VERSION ""

NS_ :

BS_:

BU_:  Battery  Charger  Host

BO_ 2566852862 BATT_eventMatrix_A_8: 8 Battery
 SG_ BATT_packModIdFault_8 : 8|1@1+ (1,0) [0|1] "" Host
 SG_ BATT_packModExitedFromBus_8 : 16|1@1+ (1,0) [0|1] "" Host
 SG_ BATT_packFetChgWelded_8 : 35|1@1+ (1,0) [0|1] "" Host
 SG_ BATT_packFetDsgWelded_8 : 36|1@1+ (1,0) [0|1] "" Host
 SG_ BATT_fetDsgShortedAux_8 : 63|1@1+ (1,0) [0|1] "" Host
 SG_ BATT_fetChgShortedAux_8 : 25|1@1+ (1,0) [0|1] "" Host
 SG_ BATT_prechargeFetFail_8 : 39|1@1+ (1,0) [0|1] "" Host
 SG_ BATT_abnormalResetReason_8 : 31|1@1+ (1,0) [0|1] "" Host
 SG_ BATT_prechargeTooSlow_8 : 49|1@1+ (1,0) [0|1] "" Host
 SG_ BATT_prechargeTooFast_8 : 50|1@1+ (1,0) [0|1] "" Host
 SG_ BATT_prechargeTimeout_8 : 51|1@1+ (1,0) [0|1] "" Host
 SG_ BATT_fetChgShorted_8 : 23|1@1+ (1,0) [0|1] "" Host
 SG_ BATT_fetChgFailToClose_8 : 22|1@1+ (1,0) [0|1] "" Host
 SG_ BATT_packModSelectFault_8 : 21|1@1+ (1,0) [0|1] "" Host
 SG_ BATT_packModConnectFault_8 : 20|1@1+ (1,0) [0|1] "" Host
 SG_ BATT_packModMIA_8 : 19|1@1+ (1,0) [0|1] "" Host
 SG_ BATT_packModImbalance_8 : 18|1@1+ (1,0) [0|1] "" Host
 SG_ BATT_afeFault_8 : 17|1@1+ (1,0) [0|1] "" Host
 SG_ BATT_chargerMIA_8 : 60|1@1+ (1,0) [0|1] "" Host
 SG_ BATT_chargerError_8 : 59|1@1+ (1,0) [0|1] "" Host
 SG_ BATT_vBrickUnderWar_8 : 58|1@1+ (1,0) [0|1] "" Host
 SG_ BATT_vBrickUnderSev_8 : 57|1@1+ (1,0) [0|1] "" Host
 SG_ BATT_vBrickUnderMod_8 : 56|1@1+ (1,0) [0|1] "" Host
 SG_ BATT_vBrickOverWar_8 : 55|1@1+ (1,0) [0|1] "" Host
 SG_ BATT_vBrickOverSev_8 : 54|1@1+ (1,0) [0|1] "" Host
 SG_ BATT_vBrickOverMod_8 : 53|1@1+ (1,0) [0|1] "" Host
 SG_ BATT_vBrickImbalance_8 : 52|1@1+ (1,0) [0|1] "" Host
 SG_ BATT_loggerAlmostFull_8 : 61|1@1+ (1,0) [0|1] "" Host
 SG_ BATT_tempModuleUnderWar_8 : 48|1@1+ (1,0) [0|1] "" Host
 SG_ BATT_tempModuleUnderSev_8 : 47|1@1+ (1,0) [0|1] "" Host
 SG_ BATT_tempModuleUnderMod_8 : 46|1@1+ (1,0) [0|1] "" Host
 SG_ BATT_tempModuleOverWar_8 : 45|1@1+ (1,0) [0|1] "" Host
 SG_ BATT_tempModuleOverSev_8 : 44|1@1+ (1,0) [0|1] "" Host
 SG_ BATT_tempModuleOverMod_8 : 43|1@1+ (1,0) [0|1] "" Host
 SG_ BATT_tempBrickImbalance_8 : 42|1@1+ (1,0) [0|1] "" Host
 SG_ BATT_taskLockupError_8 : 41|1@1+ (1,0) [0|1] "" Host
 SG_ BATT_tempBoardOverWar_8 : 40|1@1+ (1,0) [0|1] "" Host
 SG_ BATT_tempBoardOverSev_8 : 38|1@1+ (1,0) [0|1] "" Host
 SG_ BATT_tempBoardOverMod_8 : 37|1@1+ (1,0) [0|1] "" Host
 SG_ BATT_sensePackVoltError_8 : 34|1@1+ (1,0) [0|1] "" Host
 SG_ BATT_senseLoadVoltError_8 : 33|1@1+ (1,0) [0|1] "" Host
 SG_ BATT_loggerFull_8 : 62|1@1+ (1,0) [0|1] "" Host
 SG_ BATT_senseCurrentError_8 : 32|1@1+ (1,0) [0|1] "" Host
 SG_ BATT_senseBrickTempError_8 : 30|1@1+ (1,0) [0|1] "" Host
 SG_ BATT_resPackHigh_8 : 29|1@1+ (1,0) [0|1] "" Host
 SG_ BATT_ramOverUtilError_8 : 28|1@1+ (1,0) [0|1] "" Host
 SG_ BATT_powerPackInsufficient_8 : 27|1@1+ (1,0) [0|1] "" Host
 SG_ BATT_packCellSoftShort_8 : 26|1@1+ (1,0) [0|1] "" Host
 SG_ BATT_iOverHardware_8 : 24|1@1+ (1,0) [0|1] "" Host
 SG_ BATT_fetOverTemp_8 : 15|1@1+ (1,0) [0|1] "" Host
 SG_ BATT_iOverDischarge_8 : 14|1@1+ (1,0) [0|1] "" Host
 SG_ BATT_iOverCharge_8 : 13|1@1+ (1,0) [0|1] "" Host
 SG_ BATT_inverterDriveMIA_8 : 12|1@1+ (1,0) [0|1] "" Host
 SG_ BATT_iUnderCharge_8 : 11|1@1+ (1,0) [0|1] "" Host
 SG_ BATT_hostMIA_8 : 10|1@1+ (1,0) [0|1] "" Host
 SG_ BATT_fetDsgShorted_8 : 7|1@1+ (1,0) [0|1] "" Host
 SG_ BATT_fetDsgFailToClose_8 : 6|1@1+ (1,0) [0|1] "" Host
 SG_ BATT_capLow_8 : 5|1@1+ (1,0) [0|1] "" Host
 SG_ BATT_brickOverDischarge_8 : 4|1@1+ (1,0) [0|1] "" Host
 SG_ BATT_brickOverCharge_8 : 3|1@1+ (1,0) [0|1] "" Host
 SG_ BATT_bmsProcessorError_8 : 2|1@1+ (1,0) [0|1] "" Host
 SG_ BATT_bmsMemoryError_8 : 1|1@1+ (1,0) [0|1] "" Host
 SG_ BATT_afeError_8 : 0|1@1+ (1,0) [0|1] "" Host

BO_ 2566852863 BATT_eventMatrix_A_9: 8 Battery
 SG_ BATT_packModIdFault_9 : 8|1@1+ (1,0) [0|1] "" Host
 SG_ BATT_packModExitedFromBus_9 : 16|1@1+ (1,0) [0|1] "" Host
 SG_ BATT_packFetChgWelded_9 : 35|1@1+ (1,0) [0|1] "" Host
 SG_ BATT_packFetDsgWelded_9 : 36|1@1+ (1,0) [0|1] "" Host
 SG_ BATT_fetDsgShortedAux_9 : 63|1@1+ (1,0) [0|1] "" Host
 SG_ BATT_fetChgShortedAux_9 : 25|1@1+ (1,0) [0|1] "" Host
 SG_ BATT_prechargeFetFail_9 : 39|1@1+ (1,0) [0|1] "" Host
 SG_ BATT_abnormalResetReason_9 : 31|1@1+ (1,0) [0|1] "" Host
 SG_ BATT_prechargeTooSlow_9 : 49|1@1+ (1,0) [0|1] "" Host
 SG_ BATT_prechargeTooFast_9 : 50|1@1+ (1,0) [0|1] "" Host
 SG_ BATT_prechargeTimeout_9 : 51|1@1+ (1,0) [0|1] "" Host
 SG_ BATT_fetChgShorted_9 : 23|1@1+ (1,0) [0|1] "" Host
 SG_ BATT_fetChgFailToClose_9 : 22|1@1+ (1,0) [0|1] "" Host
 SG_ BATT_packModSelectFault_9 : 21|1@1+ (1,0) [0|1] "" Host
 SG_ BATT_packModConnectFault_9 : 20|1@1+ (1,0) [0|1] "" Host
 SG_ BATT_packModMIA_9 : 19|1@1+ (1,0) [0|1] "" Host
 SG_ BATT_packModImbalance_9 : 18|1@1+ (1,0) [0|1] "" Host
 SG_ BATT_afeFault_9 : 17|1@1+ (1,0) [0|1] "" Host
 SG_ BATT_chargerMIA_9 : 60|1@1+ (1,0) [0|1] "" Host
 SG_ BATT_chargerError_9 : 59|1@1+ (1,0) [0|1] "" Host
 SG_ BATT_vBrickUnderWar_9 : 58|1@1+ (1,0) [0|1] "" Host
 SG_ BATT_vBrickUnderSev_9 : 57|1@1+ (1,0) [0|1] "" Host
 SG_ BATT_vBrickUnderMod_9 : 56|1@1+ (1,0) [0|1] "" Host
 SG_ BATT_vBrickOverWar_9 : 55|1@1+ (1,0) [0|1] "" Host
 SG_ BATT_vBrickOverSev_9 : 54|1@1+ (1,0) [0|1] "" Host
 SG_ BATT_vBrickOverMod_9 : 53|1@1+ (1,0) [0|1] "" Host
 SG_ BATT_vBrickImbalance_9 : 52|1@1+ (1,0) [0|1] "" Host
 SG_ BATT_loggerAlmostFull_9 : 61|1@1+ (1,0) [0|1] "" Host
 SG_ BATT_tempModuleUnderWar_9 : 48|1@1+ (1,0) [0|1] "" Host
 SG_ BATT_tempModuleUnderSev_9 : 47|1@1+ (1,0) [0|1] "" Host
 SG_ BATT_tempModuleUnderMod_9 : 46|1@1+ (1,0) [0|1] "" Host
 SG_ BATT_tempModuleOverWar_9 : 45|1@1+ (1,0) [0|1] "" Host
 SG_ BATT_tempModuleOverSev_9 : 44|1@1+ (1,0) [0|1] "" Host
 SG_ BATT_tempModuleOverMod_9 : 43|1@1+ (1,0) [0|1] "" Host
 SG_ BATT_tempBrickImbalance_9 : 42|1@1+ (1,0) [0|1] "" Host
 SG_ BATT_taskLockupError_9 : 41|1@1+ (1,0) [0|1] "" Host
 SG_ BATT_tempBoardOverWar_9 : 40|1@1+ (1,0) [0|1] "" Host
 SG_ BATT_tempBoardOverSev_9 : 38|1@1+ (1,0) [0|1] "" Host
 SG_ BATT_tempBoardOverMod_9 : 37|1@1+ (1,0) [0|1] "" Host
 SG_ BATT_sensePackVoltError_9 : 34|1@1+ (1,0) [0|1] "" Host
 SG_ BATT_senseLoadVoltError_9 : 33|1@1+ (1,0) [0|1] "" Host
 SG_ BATT_loggerFull_9 : 62|1@1+ (1,0) [0|1] "" Host
 SG_ BATT_senseCurrentError_9 : 32|1@1+ (1,0) [0|1] "" Host
 SG_ BATT_senseBrickTempError_9 : 30|1@1+ (1,0) [0|1] "" Host
 SG_ BATT_resPackHigh_9 : 29|1@1+ (1,0) [0|1] "" Host
 SG_ BATT_ramOverUtilError_9 : 28|1@1+ (1,0) [0|1] "" Host
 SG_ BATT_powerPackInsufficient_9 : 27|1@1+ (1,0) [0|1] "" Host
 SG_ BATT_packCellSoftShort_9 : 26|1@1+ (1,0) [0|1] "" Host
 SG_ BATT_iOverHardware_9 : 24|1@1+ (1,0) [0|1] "" Host
 SG_ BATT_fetOverTemp_9 : 15|1@1+ (1,0) [0|1] "" Host
 SG_ BATT_iOverDischarge_9 : 14|1@1+ (1,0) [0|1] "" Host
 SG_ BATT_iOverCharge_9 : 13|1@1+ (1,0) [0|1] "" Host
 SG_ BATT_inverterDriveMIA_9 : 12|1@1+ (1,0) [0|1] "" Host
 SG_ BATT_iUnderCharge_9 : 11|1@1+ (1,0) [0|1] "" Host
 SG_ BATT_hostMIA_9 : 10|1@1+ (1,0) [0|1] "" Host
 SG_ BATT_fetDsgShorted_9 : 7|1@1+ (1,0) [0|1] "" Host
 SG_ BATT_fetDsgFailToClose_9 : 6|1@1+ (1,0) [0|1] "" Host
 SG_ BATT_capLow_9 : 5|1@1+ (1,0) [0|1] "" Host
 SG_ BATT_brickOverDischarge_9 : 4|1@1+ (1,0) [0|1] "" Host
 SG_ BATT_brickOverCharge_9 : 3|1@1+ (1,0) [0|1] "" Host
 SG_ BATT_bmsProcessorError_9 : 2|1@1+ (1,0) [0|1] "" Host
 SG_ BATT_bmsMemoryError_9 : 1|1@1+ (1,0) [0|1] "" Host
 SG_ BATT_afeError_9 : 0|1@1+ (1,0) [0|1] "" Host

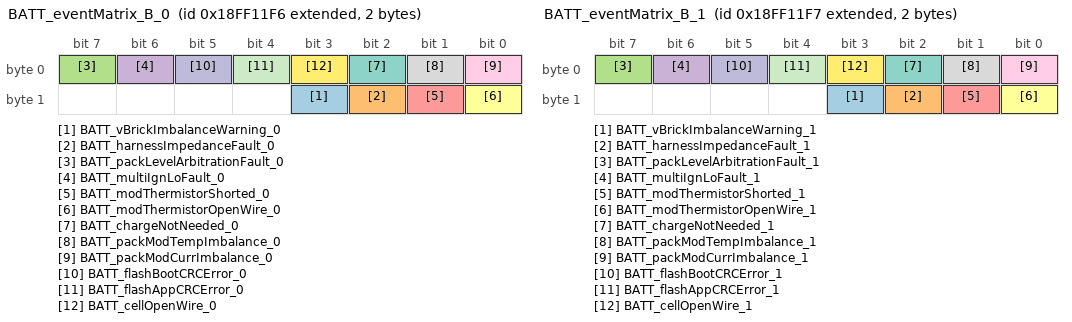
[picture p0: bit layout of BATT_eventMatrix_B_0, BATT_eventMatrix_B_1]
BO_ 2566853110 BATT_eventMatrix_B_0: 2 Battery
 SG_ BATT_vBrickImbalanceWarning_0 : 11|1@1+ (1,0) [0|1] "" Host
 SG_ BATT_harnessImpedanceFault_0 : 10|1@1+ (1,0) [0|1] "mOhms" Host
 SG_ BATT_packLevelArbitrationFault_0 : 7|1@1+ (1,0) [0|1] "" Host
 SG_ BATT_multiIgnLoFault_0 : 6|1@1+ (1,0) [0|1] "" Host
 SG_ BATT_modThermistorShorted_0 : 9|1@1+ (1,0) [0|1] "" Host
 SG_ BATT_modThermistorOpenWire_0 : 8|1@1+ (1,0) [0|1] "" Host
 SG_ BATT_chargeNotNeeded_0 : 2|1@1+ (1,0) [0|1] "" Host
 SG_ BATT_packModTempImbalance_0 : 1|1@1+ (1,0) [0|1] "" Host
 SG_ BATT_packModCurrImbalance_0 : 0|1@1+ (1,0) [0|1] "" Host
 SG_ BATT_flashBootCRCError_0 : 5|1@1+ (1,0) [0|1] "" Host
 SG_ BATT_flashAppCRCError_0 : 4|1@1+ (1,0) [0|1] "" Host
 SG_ BATT_cellOpenWire_0 : 3|1@1+ (1,0) [0|1] "" Host

BO_ 2566853111 BATT_eventMatrix_B_1: 2 Battery
 SG_ BATT_vBrickImbalanceWarning_1 : 11|1@1+ (1,0) [0|1] "" Host
 SG_ BATT_harnessImpedanceFault_1 : 10|1@1+ (1,0) [0|1] "mOhms" Host
 SG_ BATT_packLevelArbitrationFault_1 : 7|1@1+ (1,0) [0|1] "" Host
 SG_ BATT_multiIgnLoFault_1 : 6|1@1+ (1,0) [0|1] "" Host
 SG_ BATT_modThermistorShorted_1 : 9|1@1+ (1,0) [0|1] "" Host
 SG_ BATT_modThermistorOpenWire_1 : 8|1@1+ (1,0) [0|1] "" Host
 SG_ BATT_chargeNotNeeded_1 : 2|1@1+ (1,0) [0|1] "" Host
 SG_ BATT_packModTempImbalance_1 : 1|1@1+ (1,0) [0|1] "" Host
 SG_ BATT_packModCurrImbalance_1 : 0|1@1+ (1,0) [0|1] "" Host
 SG_ BATT_flashBootCRCError_1 : 5|1@1+ (1,0) [0|1] "" Host
 SG_ BATT_flashAppCRCError_1 : 4|1@1+ (1,0) [0|1] "" Host
 SG_ BATT_cellOpenWire_1 : 3|1@1+ (1,0) [0|1] "" Host

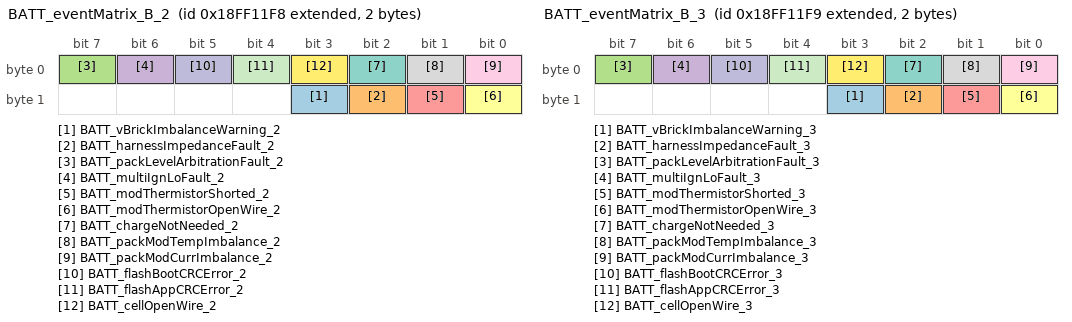
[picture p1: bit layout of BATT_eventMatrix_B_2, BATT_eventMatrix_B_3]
BO_ 2566853112 BATT_eventMatrix_B_2: 2 Battery
 SG_ BATT_vBrickImbalanceWarning_2 : 11|1@1+ (1,0) [0|1] "" Host
 SG_ BATT_harnessImpedanceFault_2 : 10|1@1+ (1,0) [0|1] "mOhms" Host
 SG_ BATT_packLevelArbitrationFault_2 : 7|1@1+ (1,0) [0|1] "" Host
 SG_ BATT_multiIgnLoFault_2 : 6|1@1+ (1,0) [0|1] "" Host
 SG_ BATT_modThermistorShorted_2 : 9|1@1+ (1,0) [0|1] "" Host
 SG_ BATT_modThermistorOpenWire_2 : 8|1@1+ (1,0) [0|1] "" Host
 SG_ BATT_chargeNotNeeded_2 : 2|1@1+ (1,0) [0|1] "" Host
 SG_ BATT_packModTempImbalance_2 : 1|1@1+ (1,0) [0|1] "" Host
 SG_ BATT_packModCurrImbalance_2 : 0|1@1+ (1,0) [0|1] "" Host
 SG_ BATT_flashBootCRCError_2 : 5|1@1+ (1,0) [0|1] "" Host
 SG_ BATT_flashAppCRCError_2 : 4|1@1+ (1,0) [0|1] "" Host
 SG_ BATT_cellOpenWire_2 : 3|1@1+ (1,0) [0|1] "" Host

BO_ 2566853113 BATT_eventMatrix_B_3: 2 Battery
 SG_ BATT_vBrickImbalanceWarning_3 : 11|1@1+ (1,0) [0|1] "" Host
 SG_ BATT_harnessImpedanceFault_3 : 10|1@1+ (1,0) [0|1] "mOhms" Host
 SG_ BATT_packLevelArbitrationFault_3 : 7|1@1+ (1,0) [0|1] "" Host
 SG_ BATT_multiIgnLoFault_3 : 6|1@1+ (1,0) [0|1] "" Host
 SG_ BATT_modThermistorShorted_3 : 9|1@1+ (1,0) [0|1] "" Host
 SG_ BATT_modThermistorOpenWire_3 : 8|1@1+ (1,0) [0|1] "" Host
 SG_ BATT_chargeNotNeeded_3 : 2|1@1+ (1,0) [0|1] "" Host
 SG_ BATT_packModTempImbalance_3 : 1|1@1+ (1,0) [0|1] "" Host
 SG_ BATT_packModCurrImbalance_3 : 0|1@1+ (1,0) [0|1] "" Host
 SG_ BATT_flashBootCRCError_3 : 5|1@1+ (1,0) [0|1] "" Host
 SG_ BATT_flashAppCRCError_3 : 4|1@1+ (1,0) [0|1] "" Host
 SG_ BATT_cellOpenWire_3 : 3|1@1+ (1,0) [0|1] "" Host

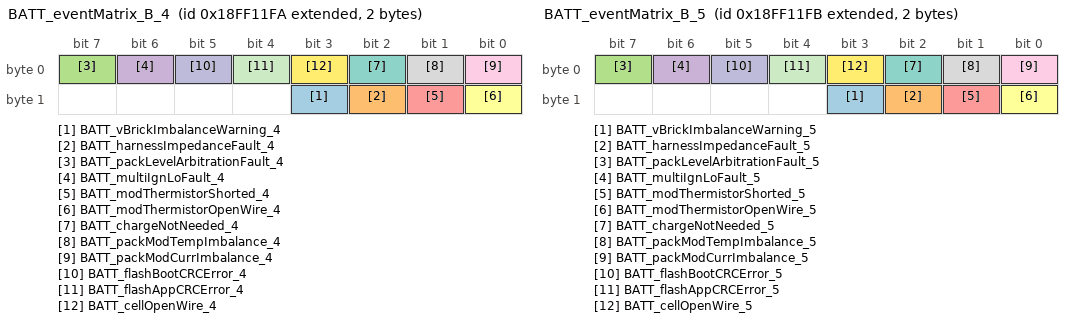
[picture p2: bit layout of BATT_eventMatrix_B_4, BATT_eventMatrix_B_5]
BO_ 2566853114 BATT_eventMatrix_B_4: 2 Battery
 SG_ BATT_vBrickImbalanceWarning_4 : 11|1@1+ (1,0) [0|1] "" Host
 SG_ BATT_harnessImpedanceFault_4 : 10|1@1+ (1,0) [0|1] "mOhms" Host
 SG_ BATT_packLevelArbitrationFault_4 : 7|1@1+ (1,0) [0|1] "" Host
 SG_ BATT_multiIgnLoFault_4 : 6|1@1+ (1,0) [0|1] "" Host
 SG_ BATT_modThermistorShorted_4 : 9|1@1+ (1,0) [0|1] "" Host
 SG_ BATT_modThermistorOpenWire_4 : 8|1@1+ (1,0) [0|1] "" Host
 SG_ BATT_chargeNotNeeded_4 : 2|1@1+ (1,0) [0|1] "" Host
 SG_ BATT_packModTempImbalance_4 : 1|1@1+ (1,0) [0|1] "" Host
 SG_ BATT_packModCurrImbalance_4 : 0|1@1+ (1,0) [0|1] "" Host
 SG_ BATT_flashBootCRCError_4 : 5|1@1+ (1,0) [0|1] "" Host
 SG_ BATT_flashAppCRCError_4 : 4|1@1+ (1,0) [0|1] "" Host
 SG_ BATT_cellOpenWire_4 : 3|1@1+ (1,0) [0|1] "" Host

BO_ 2566853115 BATT_eventMatrix_B_5: 2 Battery
 SG_ BATT_vBrickImbalanceWarning_5 : 11|1@1+ (1,0) [0|1] "" Host
 SG_ BATT_harnessImpedanceFault_5 : 10|1@1+ (1,0) [0|1] "mOhms" Host
 SG_ BATT_packLevelArbitrationFault_5 : 7|1@1+ (1,0) [0|1] "" Host
 SG_ BATT_multiIgnLoFault_5 : 6|1@1+ (1,0) [0|1] "" Host
 SG_ BATT_modThermistorShorted_5 : 9|1@1+ (1,0) [0|1] "" Host
 SG_ BATT_modThermistorOpenWire_5 : 8|1@1+ (1,0) [0|1] "" Host
 SG_ BATT_chargeNotNeeded_5 : 2|1@1+ (1,0) [0|1] "" Host
 SG_ BATT_packModTempImbalance_5 : 1|1@1+ (1,0) [0|1] "" Host
 SG_ BATT_packModCurrImbalance_5 : 0|1@1+ (1,0) [0|1] "" Host
 SG_ BATT_flashBootCRCError_5 : 5|1@1+ (1,0) [0|1] "" Host
 SG_ BATT_flashAppCRCError_5 : 4|1@1+ (1,0) [0|1] "" Host
 SG_ BATT_cellOpenWire_5 : 3|1@1+ (1,0) [0|1] "" Host

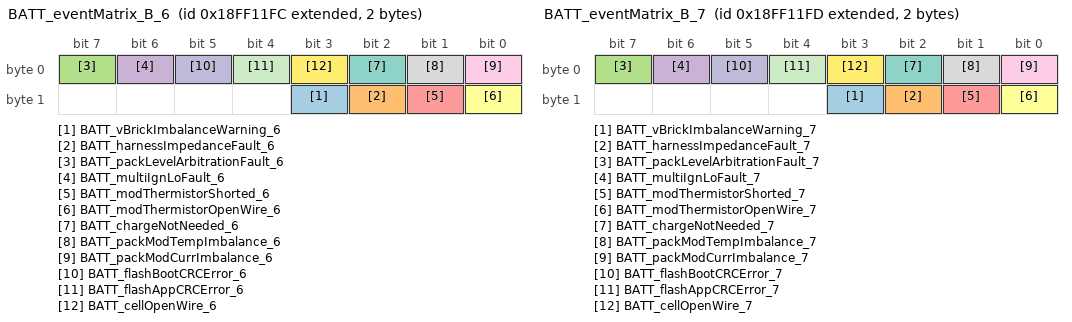
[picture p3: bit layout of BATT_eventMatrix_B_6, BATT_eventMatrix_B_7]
BO_ 2566853116 BATT_eventMatrix_B_6: 2 Battery
 SG_ BATT_vBrickImbalanceWarning_6 : 11|1@1+ (1,0) [0|1] "" Host
 SG_ BATT_harnessImpedanceFault_6 : 10|1@1+ (1,0) [0|1] "mOhms" Host
 SG_ BATT_packLevelArbitrationFault_6 : 7|1@1+ (1,0) [0|1] "" Host
 SG_ BATT_multiIgnLoFault_6 : 6|1@1+ (1,0) [0|1] "" Host
 SG_ BATT_modThermistorShorted_6 : 9|1@1+ (1,0) [0|1] "" Host
 SG_ BATT_modThermistorOpenWire_6 : 8|1@1+ (1,0) [0|1] "" Host
 SG_ BATT_chargeNotNeeded_6 : 2|1@1+ (1,0) [0|1] "" Host
 SG_ BATT_packModTempImbalance_6 : 1|1@1+ (1,0) [0|1] "" Host
 SG_ BATT_packModCurrImbalance_6 : 0|1@1+ (1,0) [0|1] "" Host
 SG_ BATT_flashBootCRCError_6 : 5|1@1+ (1,0) [0|1] "" Host
 SG_ BATT_flashAppCRCError_6 : 4|1@1+ (1,0) [0|1] "" Host
 SG_ BATT_cellOpenWire_6 : 3|1@1+ (1,0) [0|1] "" Host

BO_ 2566853117 BATT_eventMatrix_B_7: 2 Battery
 SG_ BATT_vBrickImbalanceWarning_7 : 11|1@1+ (1,0) [0|1] "" Host
 SG_ BATT_harnessImpedanceFault_7 : 10|1@1+ (1,0) [0|1] "mOhms" Host
 SG_ BATT_packLevelArbitrationFault_7 : 7|1@1+ (1,0) [0|1] "" Host
 SG_ BATT_multiIgnLoFault_7 : 6|1@1+ (1,0) [0|1] "" Host
 SG_ BATT_modThermistorShorted_7 : 9|1@1+ (1,0) [0|1] "" Host
 SG_ BATT_modThermistorOpenWire_7 : 8|1@1+ (1,0) [0|1] "" Host
 SG_ BATT_chargeNotNeeded_7 : 2|1@1+ (1,0) [0|1] "" Host
 SG_ BATT_packModTempImbalance_7 : 1|1@1+ (1,0) [0|1] "" Host
 SG_ BATT_packModCurrImbalance_7 : 0|1@1+ (1,0) [0|1] "" Host
 SG_ BATT_flashBootCRCError_7 : 5|1@1+ (1,0) [0|1] "" Host
 SG_ BATT_flashAppCRCError_7 : 4|1@1+ (1,0) [0|1] "" Host
 SG_ BATT_cellOpenWire_7 : 3|1@1+ (1,0) [0|1] "" Host

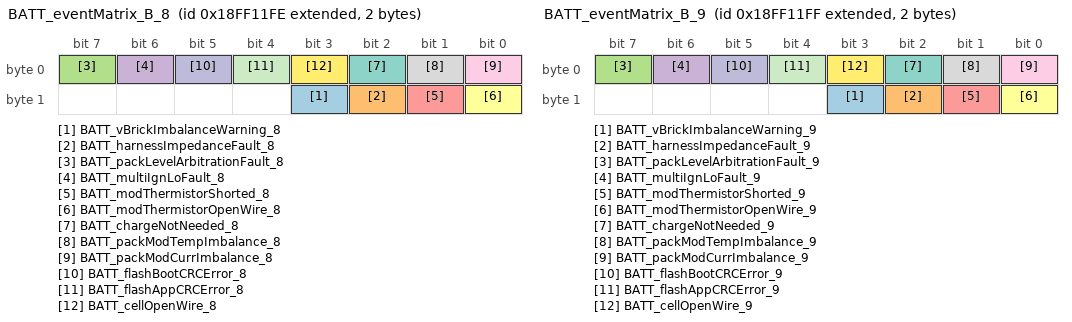
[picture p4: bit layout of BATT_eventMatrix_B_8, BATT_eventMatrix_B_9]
BO_ 2566853118 BATT_eventMatrix_B_8: 2 Battery
 SG_ BATT_vBrickImbalanceWarning_8 : 11|1@1+ (1,0) [0|1] "" Host
 SG_ BATT_harnessImpedanceFault_8 : 10|1@1+ (1,0) [0|1] "mOhms" Host
 SG_ BATT_packLevelArbitrationFault_8 : 7|1@1+ (1,0) [0|1] "" Host
 SG_ BATT_multiIgnLoFault_8 : 6|1@1+ (1,0) [0|1] "" Host
 SG_ BATT_modThermistorShorted_8 : 9|1@1+ (1,0) [0|1] "" Host
 SG_ BATT_modThermistorOpenWire_8 : 8|1@1+ (1,0) [0|1] "" Host
 SG_ BATT_chargeNotNeeded_8 : 2|1@1+ (1,0) [0|1] "" Host
 SG_ BATT_packModTempImbalance_8 : 1|1@1+ (1,0) [0|1] "" Host
 SG_ BATT_packModCurrImbalance_8 : 0|1@1+ (1,0) [0|1] "" Host
 SG_ BATT_flashBootCRCError_8 : 5|1@1+ (1,0) [0|1] "" Host
 SG_ BATT_flashAppCRCError_8 : 4|1@1+ (1,0) [0|1] "" Host
 SG_ BATT_cellOpenWire_8 : 3|1@1+ (1,0) [0|1] "" Host

BO_ 2566853119 BATT_eventMatrix_B_9: 2 Battery
 SG_ BATT_vBrickImbalanceWarning_9 : 11|1@1+ (1,0) [0|1] "" Host
 SG_ BATT_harnessImpedanceFault_9 : 10|1@1+ (1,0) [0|1] "mOhms" Host
 SG_ BATT_packLevelArbitrationFault_9 : 7|1@1+ (1,0) [0|1] "" Host
 SG_ BATT_multiIgnLoFault_9 : 6|1@1+ (1,0) [0|1] "" Host
 SG_ BATT_modThermistorShorted_9 : 9|1@1+ (1,0) [0|1] "" Host
 SG_ BATT_modThermistorOpenWire_9 : 8|1@1+ (1,0) [0|1] "" Host
 SG_ BATT_chargeNotNeeded_9 : 2|1@1+ (1,0) [0|1] "" Host
 SG_ BATT_packModTempImbalance_9 : 1|1@1+ (1,0) [0|1] "" Host
 SG_ BATT_packModCurrImbalance_9 : 0|1@1+ (1,0) [0|1] "" Host
 SG_ BATT_flashBootCRCError_9 : 5|1@1+ (1,0) [0|1] "" Host
 SG_ BATT_flashAppCRCError_9 : 4|1@1+ (1,0) [0|1] "" Host
 SG_ BATT_cellOpenWire_9 : 3|1@1+ (1,0) [0|1] "" Host

BO_ 2566853622 BATT_diagnosticSOHRBricksB_0: 8 Battery
 SG_ BATT_sohrBrick08_0 : 48|16@1+ (0.00075,0) [0|49.15125] "Ah" Host
 SG_ BATT_sohrBrick07_0 : 32|16@1+ (0.00075,0) [0|49.15125] "Ah" Host
 SG_ BATT_sohrBrick06_0 : 16|16@1+ (0.00075,0) [0|49.15125] "Ah" Host
 SG_ BATT_sohrBrick05_0 : 0|16@1+ (0.00075,0) [0|49.15125] "Ah" Host

BO_ 2566853623 BATT_diagnosticSOHRBricksB_1: 8 Battery
 SG_ BATT_sohrBrick08_1 : 48|16@1+ (0.00075,0) [0|49.15125] "Ah" Host
 SG_ BATT_sohrBrick07_1 : 32|16@1+ (0.00075,0) [0|49.15125] "Ah" Host
 SG_ BATT_sohrBrick06_1 : 16|16@1+ (0.00075,0) [0|49.15125] "Ah" Host
 SG_ BATT_sohrBrick05_1 : 0|16@1+ (0.00075,0) [0|49.15125] "Ah" Host

BO_ 2566853624 BATT_diagnosticSOHRBricksB_2: 8 Battery
 SG_ BATT_sohrBrick08_2 : 48|16@1+ (0.00075,0) [0|49.15125] "Ah" Host
 SG_ BATT_sohrBrick07_2 : 32|16@1+ (0.00075,0) [0|49.15125] "Ah" Host
 SG_ BATT_sohrBrick06_2 : 16|16@1+ (0.00075,0) [0|49.15125] "Ah" Host
 SG_ BATT_sohrBrick05_2 : 0|16@1+ (0.00075,0) [0|49.15125] "Ah" Host

BO_ 2566853625 BATT_diagnosticSOHRBricksB_3: 8 Battery
 SG_ BATT_sohrBrick08_3 : 48|16@1+ (0.00075,0) [0|49.15125] "Ah" Host
 SG_ BATT_sohrBrick07_3 : 32|16@1+ (0.00075,0) [0|49.15125] "Ah" Host
 SG_ BATT_sohrBrick06_3 : 16|16@1+ (0.00075,0) [0|49.15125] "Ah" Host
 SG_ BATT_sohrBrick05_3 : 0|16@1+ (0.00075,0) [0|49.15125] "Ah" Host

BO_ 2566853626 BATT_diagnosticSOHRBricksB_4: 8 Battery
 SG_ BATT_sohrBrick08_4 : 48|16@1+ (0.00075,0) [0|49.15125] "Ah" Host
 SG_ BATT_sohrBrick07_4 : 32|16@1+ (0.00075,0) [0|49.15125] "Ah" Host
 SG_ BATT_sohrBrick06_4 : 16|16@1+ (0.00075,0) [0|49.15125] "Ah" Host
 SG_ BATT_sohrBrick05_4 : 0|16@1+ (0.00075,0) [0|49.15125] "Ah" Host

BO_ 2566853627 BATT_diagnosticSOHRBricksB_5: 8 Battery
 SG_ BATT_sohrBrick08_5 : 48|16@1+ (0.00075,0) [0|49.15125] "Ah" Host
 SG_ BATT_sohrBrick07_5 : 32|16@1+ (0.00075,0) [0|49.15125] "Ah" Host
 SG_ BATT_sohrBrick06_5 : 16|16@1+ (0.00075,0) [0|49.15125] "Ah" Host
 SG_ BATT_sohrBrick05_5 : 0|16@1+ (0.00075,0) [0|49.15125] "Ah" Host

BO_ 2566853628 BATT_diagnosticSOHRBricksB_6: 8 Battery
 SG_ BATT_sohrBrick08_6 : 48|16@1+ (0.00075,0) [0|49.15125] "Ah" Host
 SG_ BATT_sohrBrick07_6 : 32|16@1+ (0.00075,0) [0|49.15125] "Ah" Host
 SG_ BATT_sohrBrick06_6 : 16|16@1+ (0.00075,0) [0|49.15125] "Ah" Host
 SG_ BATT_sohrBrick05_6 : 0|16@1+ (0.00075,0) [0|49.15125] "Ah" Host

BO_ 2566853629 BATT_diagnosticSOHRBricksB_7: 8 Battery
 SG_ BATT_sohrBrick08_7 : 48|16@1+ (0.00075,0) [0|49.15125] "Ah" Host
 SG_ BATT_sohrBrick07_7 : 32|16@1+ (0.00075,0) [0|49.15125] "Ah" Host
 SG_ BATT_sohrBrick06_7 : 16|16@1+ (0.00075,0) [0|49.15125] "Ah" Host
 SG_ BATT_sohrBrick05_7 : 0|16@1+ (0.00075,0) [0|49.15125] "Ah" Host

BO_ 2566853630 BATT_diagnosticSOHRBricksB_8: 8 Battery
 SG_ BATT_sohrBrick08_8 : 48|16@1+ (0.00075,0) [0|49.15125] "Ah" Host
 SG_ BATT_sohrBrick07_8 : 32|16@1+ (0.00075,0) [0|49.15125] "Ah" Host
 SG_ BATT_sohrBrick06_8 : 16|16@1+ (0.00075,0) [0|49.15125] "Ah" Host
 SG_ BATT_sohrBrick05_8 : 0|16@1+ (0.00075,0) [0|49.15125] "Ah" Host

BO_ 2566853631 BATT_diagnosticSOHRBricksB_9: 8 Battery
 SG_ BATT_sohrBrick08_9 : 48|16@1+ (0.00075,0) [0|49.15125] "Ah" Host
 SG_ BATT_sohrBrick07_9 : 32|16@1+ (0.00075,0) [0|49.15125] "Ah" Host
 SG_ BATT_sohrBrick06_9 : 16|16@1+ (0.00075,0) [0|49.15125] "Ah" Host
 SG_ BATT_sohrBrick05_9 : 0|16@1+ (0.00075,0) [0|49.15125] "Ah" Host

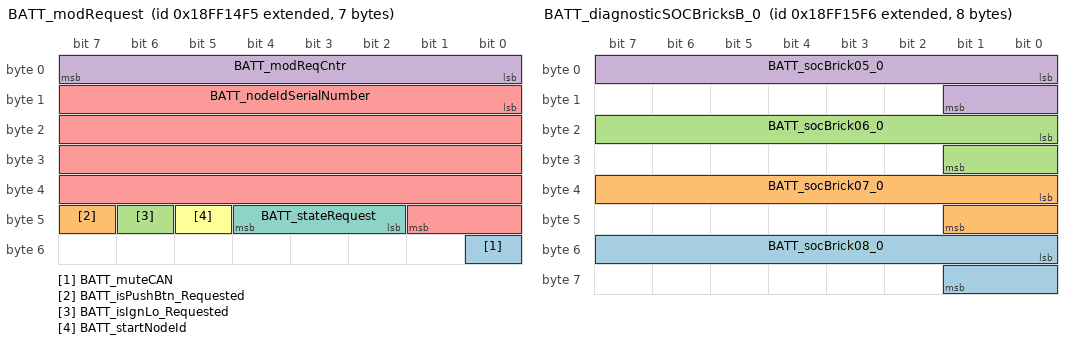
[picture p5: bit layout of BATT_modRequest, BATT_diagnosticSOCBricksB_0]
BO_ 2566853877 BATT_modRequest: 7 Battery
 SG_ BATT_muteCAN : 48|1@1+ (1,0) [0|1] "" Host,Battery
 SG_ BATT_isPushBtn_Requested : 47|1@1+ (1,0) [0|1] "" Battery,Host
 SG_ BATT_isIgnLo_Requested : 46|1@1+ (1,0) [0|1] "" Battery,Host
 SG_ BATT_modReqCntr : 0|8@1+ (1,0) [0|255] "" Battery,Host
 SG_ BATT_nodeIdSerialNumber : 8|34@1+ (1,0) [0|17179869183] "" Battery,Host
 SG_ BATT_startNodeId : 45|1@1+ (1,0) [0|1] "" Battery,Host
 SG_ BATT_stateRequest : 42|3@1+ (1,0) [0|7] "" Battery,Host

BO_ 2566854134 BATT_diagnosticSOCBricksB_0: 8 Battery
 SG_ BATT_socBrick08_0 : 48|10@1+ (0.1,0) [0|102.3] "%" Host
 SG_ BATT_socBrick07_0 : 32|10@1+ (0.1,0) [0|102.3] "%" Host
 SG_ BATT_socBrick06_0 : 16|10@1+ (0.1,0) [0|102.3] "%" Host
 SG_ BATT_socBrick05_0 : 0|10@1+ (0.1,0) [0|102.3] "%" Host

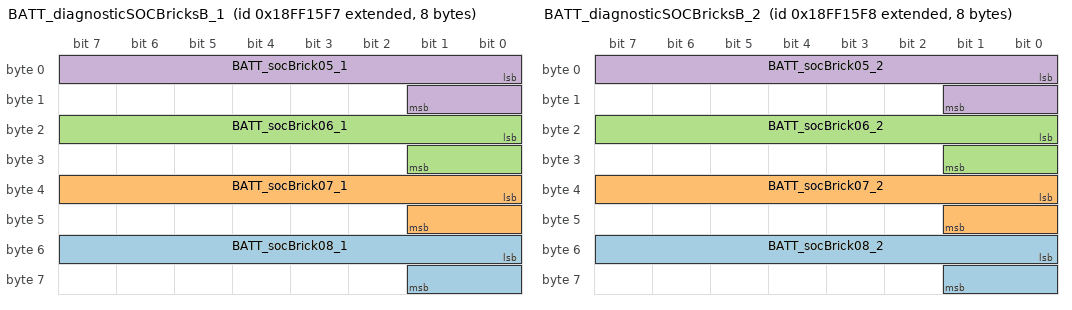
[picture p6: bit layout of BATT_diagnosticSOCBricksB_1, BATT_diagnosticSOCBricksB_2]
BO_ 2566854135 BATT_diagnosticSOCBricksB_1: 8 Battery
 SG_ BATT_socBrick08_1 : 48|10@1+ (0.1,0) [0|102.3] "%" Host
 SG_ BATT_socBrick07_1 : 32|10@1+ (0.1,0) [0|102.3] "%" Host
 SG_ BATT_socBrick06_1 : 16|10@1+ (0.1,0) [0|102.3] "%" Host
 SG_ BATT_socBrick05_1 : 0|10@1+ (0.1,0) [0|102.3] "%" Host

BO_ 2566854136 BATT_diagnosticSOCBricksB_2: 8 Battery
 SG_ BATT_socBrick08_2 : 48|10@1+ (0.1,0) [0|102.3] "%" Host
 SG_ BATT_socBrick07_2 : 32|10@1+ (0.1,0) [0|102.3] "%" Host
 SG_ BATT_socBrick06_2 : 16|10@1+ (0.1,0) [0|102.3] "%" Host
 SG_ BATT_socBrick05_2 : 0|10@1+ (0.1,0) [0|102.3] "%" Host

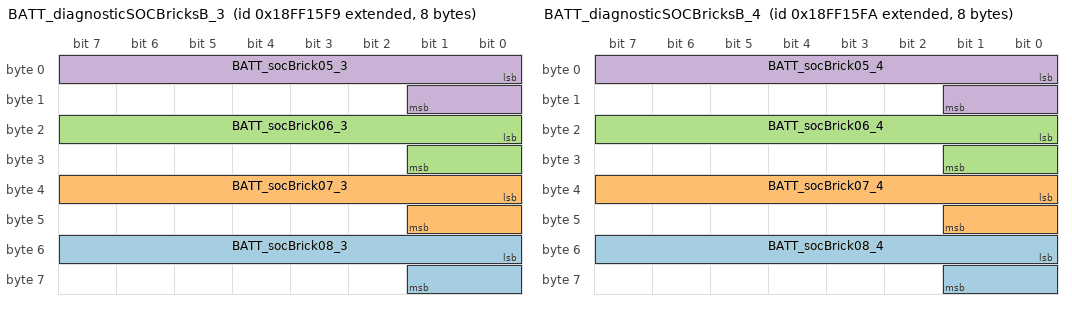
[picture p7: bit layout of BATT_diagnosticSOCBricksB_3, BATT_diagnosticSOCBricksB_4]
BO_ 2566854137 BATT_diagnosticSOCBricksB_3: 8 Battery
 SG_ BATT_socBrick08_3 : 48|10@1+ (0.1,0) [0|102.3] "%" Host
 SG_ BATT_socBrick07_3 : 32|10@1+ (0.1,0) [0|102.3] "%" Host
 SG_ BATT_socBrick06_3 : 16|10@1+ (0.1,0) [0|102.3] "%" Host
 SG_ BATT_socBrick05_3 : 0|10@1+ (0.1,0) [0|102.3] "%" Host

BO_ 2566854138 BATT_diagnosticSOCBricksB_4: 8 Battery
 SG_ BATT_socBrick08_4 : 48|10@1+ (0.1,0) [0|102.3] "%" Host
 SG_ BATT_socBrick07_4 : 32|10@1+ (0.1,0) [0|102.3] "%" Host
 SG_ BATT_socBrick06_4 : 16|10@1+ (0.1,0) [0|102.3] "%" Host
 SG_ BATT_socBrick05_4 : 0|10@1+ (0.1,0) [0|102.3] "%" Host

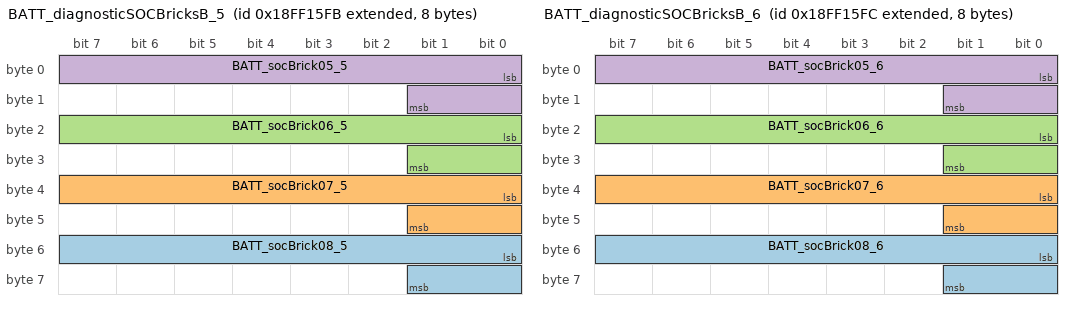
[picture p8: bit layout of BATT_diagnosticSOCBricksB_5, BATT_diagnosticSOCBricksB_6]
BO_ 2566854139 BATT_diagnosticSOCBricksB_5: 8 Battery
 SG_ BATT_socBrick08_5 : 48|10@1+ (0.1,0) [0|102.3] "%" Host
 SG_ BATT_socBrick07_5 : 32|10@1+ (0.1,0) [0|102.3] "%" Host
 SG_ BATT_socBrick06_5 : 16|10@1+ (0.1,0) [0|102.3] "%" Host
 SG_ BATT_socBrick05_5 : 0|10@1+ (0.1,0) [0|102.3] "%" Host

BO_ 2566854140 BATT_diagnosticSOCBricksB_6: 8 Battery
 SG_ BATT_socBrick08_6 : 48|10@1+ (0.1,0) [0|102.3] "%" Host
 SG_ BATT_socBrick07_6 : 32|10@1+ (0.1,0) [0|102.3] "%" Host
 SG_ BATT_socBrick06_6 : 16|10@1+ (0.1,0) [0|102.3] "%" Host
 SG_ BATT_socBrick05_6 : 0|10@1+ (0.1,0) [0|102.3] "%" Host

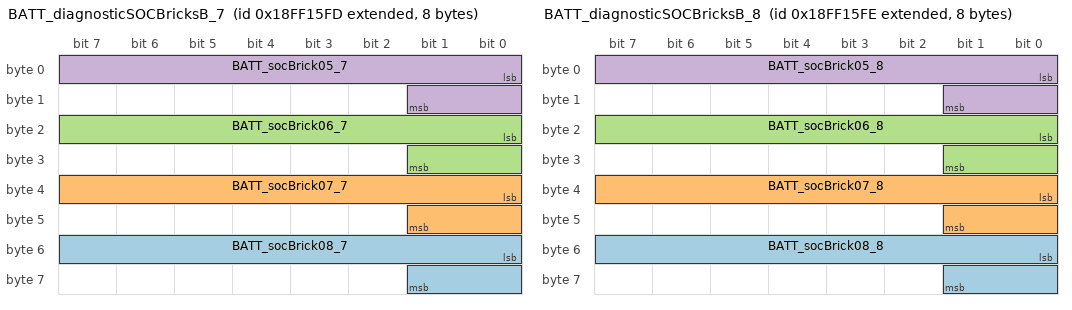
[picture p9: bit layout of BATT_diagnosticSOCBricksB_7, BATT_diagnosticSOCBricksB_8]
BO_ 2566854141 BATT_diagnosticSOCBricksB_7: 8 Battery
 SG_ BATT_socBrick08_7 : 48|10@1+ (0.1,0) [0|102.3] "%" Host
 SG_ BATT_socBrick07_7 : 32|10@1+ (0.1,0) [0|102.3] "%" Host
 SG_ BATT_socBrick06_7 : 16|10@1+ (0.1,0) [0|102.3] "%" Host
 SG_ BATT_socBrick05_7 : 0|10@1+ (0.1,0) [0|102.3] "%" Host

BO_ 2566854142 BATT_diagnosticSOCBricksB_8: 8 Battery
 SG_ BATT_socBrick08_8 : 48|10@1+ (0.1,0) [0|102.3] "%" Host
 SG_ BATT_socBrick07_8 : 32|10@1+ (0.1,0) [0|102.3] "%" Host
 SG_ BATT_socBrick06_8 : 16|10@1+ (0.1,0) [0|102.3] "%" Host
 SG_ BATT_socBrick05_8 : 0|10@1+ (0.1,0) [0|102.3] "%" Host

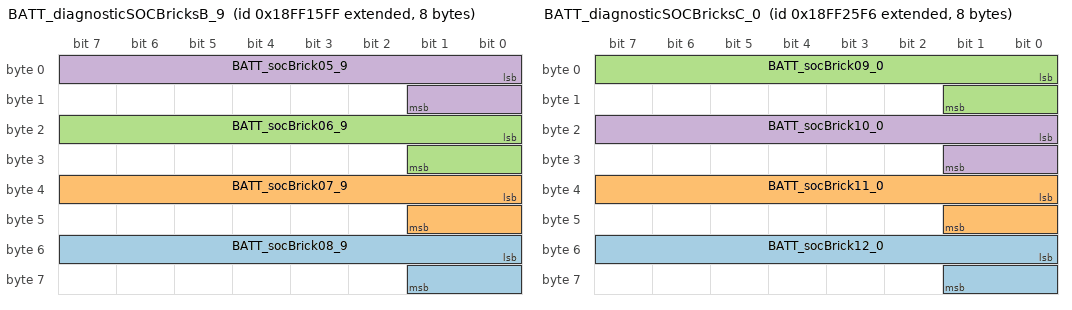
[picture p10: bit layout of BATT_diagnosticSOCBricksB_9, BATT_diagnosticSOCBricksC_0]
BO_ 2566854143 BATT_diagnosticSOCBricksB_9: 8 Battery
 SG_ BATT_socBrick08_9 : 48|10@1+ (0.1,0) [0|102.3] "%" Host
 SG_ BATT_socBrick07_9 : 32|10@1+ (0.1,0) [0|102.3] "%" Host
 SG_ BATT_socBrick06_9 : 16|10@1+ (0.1,0) [0|102.3] "%" Host
 SG_ BATT_socBrick05_9 : 0|10@1+ (0.1,0) [0|102.3] "%" Host

BO_ 2566854390 BATT_diagnosticCapBricksB_0: 8 Battery
 SG_ BATT_capBrick08_0 : 48|16@1+ (0.0025,0) [0|163.8375] "Ah" Host
 SG_ BATT_capBrick07_0 : 32|16@1+ (0.0025,0) [0|163.8375] "Ah" Host
 SG_ BATT_capBrick06_0 : 16|16@1+ (0.0025,0) [0|163.8375] "Ah" Host
 SG_ BATT_capBrick05_0 : 0|16@1+ (0.0025,0) [0|163.8375] "Ah" Host

BO_ 2566854391 BATT_diagnosticCapBricksB_1: 8 Battery
 SG_ BATT_capBrick08_1 : 48|16@1+ (0.0025,0) [0|163.8375] "Ah" Host
 SG_ BATT_capBrick07_1 : 32|16@1+ (0.0025,0) [0|163.8375] "Ah" Host
 SG_ BATT_capBrick06_1 : 16|16@1+ (0.0025,0) [0|163.8375] "Ah" Host
 SG_ BATT_capBrick05_1 : 0|16@1+ (0.0025,0) [0|163.8375] "Ah" Host

BO_ 2566854392 BATT_diagnosticCapBricksB_2: 8 Battery
 SG_ BATT_capBrick08_2 : 48|16@1+ (0.0025,0) [0|163.8375] "Ah" Host
 SG_ BATT_capBrick07_2 : 32|16@1+ (0.0025,0) [0|163.8375] "Ah" Host
 SG_ BATT_capBrick06_2 : 16|16@1+ (0.0025,0) [0|163.8375] "Ah" Host
 SG_ BATT_capBrick05_2 : 0|16@1+ (0.0025,0) [0|163.8375] "Ah" Host

BO_ 2566854393 BATT_diagnosticCapBricksB_3: 8 Battery
 SG_ BATT_capBrick08_3 : 48|16@1+ (0.0025,0) [0|163.8375] "Ah" Host
 SG_ BATT_capBrick07_3 : 32|16@1+ (0.0025,0) [0|163.8375] "Ah" Host
 SG_ BATT_capBrick06_3 : 16|16@1+ (0.0025,0) [0|163.8375] "Ah" Host
 SG_ BATT_capBrick05_3 : 0|16@1+ (0.0025,0) [0|163.8375] "Ah" Host

BO_ 2566854394 BATT_diagnosticCapBricksB_4: 8 Battery
 SG_ BATT_capBrick08_4 : 48|16@1+ (0.0025,0) [0|163.8375] "Ah" Host
 SG_ BATT_capBrick07_4 : 32|16@1+ (0.0025,0) [0|163.8375] "Ah" Host
 SG_ BATT_capBrick06_4 : 16|16@1+ (0.0025,0) [0|163.8375] "Ah" Host
 SG_ BATT_capBrick05_4 : 0|16@1+ (0.0025,0) [0|163.8375] "Ah" Host

BO_ 2566854395 BATT_diagnosticCapBricksB_5: 8 Battery
 SG_ BATT_capBrick08_5 : 48|16@1+ (0.0025,0) [0|163.8375] "Ah" Host
 SG_ BATT_capBrick07_5 : 32|16@1+ (0.0025,0) [0|163.8375] "Ah" Host
 SG_ BATT_capBrick06_5 : 16|16@1+ (0.0025,0) [0|163.8375] "Ah" Host
 SG_ BATT_capBrick05_5 : 0|16@1+ (0.0025,0) [0|163.8375] "Ah" Host

BO_ 2566854396 BATT_diagnosticCapBricksB_6: 8 Battery
 SG_ BATT_capBrick08_6 : 48|16@1+ (0.0025,0) [0|163.8375] "Ah" Host
 SG_ BATT_capBrick07_6 : 32|16@1+ (0.0025,0) [0|163.8375] "Ah" Host
 SG_ BATT_capBrick06_6 : 16|16@1+ (0.0025,0) [0|163.8375] "Ah" Host
 SG_ BATT_capBrick05_6 : 0|16@1+ (0.0025,0) [0|163.8375] "Ah" Host

BO_ 2566854397 BATT_diagnosticCapBricksB_7: 8 Battery
 SG_ BATT_capBrick08_7 : 48|16@1+ (0.0025,0) [0|163.8375] "Ah" Host
 SG_ BATT_capBrick07_7 : 32|16@1+ (0.0025,0) [0|163.8375] "Ah" Host
 SG_ BATT_capBrick06_7 : 16|16@1+ (0.0025,0) [0|163.8375] "Ah" Host
 SG_ BATT_capBrick05_7 : 0|16@1+ (0.0025,0) [0|163.8375] "Ah" Host

BO_ 2566854398 BATT_diagnosticCapBricksB_8: 8 Battery
 SG_ BATT_capBrick08_8 : 48|16@1+ (0.0025,0) [0|163.8375] "Ah" Host
 SG_ BATT_capBrick07_8 : 32|16@1+ (0.0025,0) [0|163.8375] "Ah" Host
 SG_ BATT_capBrick06_8 : 16|16@1+ (0.0025,0) [0|163.8375] "Ah" Host
 SG_ BATT_capBrick05_8 : 0|16@1+ (0.0025,0) [0|163.8375] "Ah" Host

BO_ 2566854399 BATT_diagnosticCapBricksB_9: 8 Battery
 SG_ BATT_capBrick08_9 : 48|16@1+ (0.0025,0) [0|163.8375] "Ah" Host
 SG_ BATT_capBrick07_9 : 32|16@1+ (0.0025,0) [0|163.8375] "Ah" Host
 SG_ BATT_capBrick06_9 : 16|16@1+ (0.0025,0) [0|163.8375] "Ah" Host
 SG_ BATT_capBrick05_9 : 0|16@1+ (0.0025,0) [0|163.8375] "Ah" Host

BO_ 2566854646 BATT_diagnosticVBricksB_0: 8 Battery
 SG_ BATT_vBrick06_0 : 16|16@1+ (7.6e-05,0) [0|4.98066] "V" Host
 SG_ BATT_vBrick07_0 : 32|16@1+ (7.6e-05,0) [0|4.98066] "V" Host
 SG_ BATT_vBrick05_0 : 0|16@1+ (7.6e-05,0) [0|4.98066] "V" Host
 SG_ BATT_vBrick08_0 : 48|16@1+ (7.6e-05,0) [0|4.98066] "V" Host

BO_ 2566854647 BATT_diagnosticVBricksB_1: 8 Battery
 SG_ BATT_vBrick06_1 : 16|16@1+ (7.6e-05,0) [0|4.98066] "V" Host
 SG_ BATT_vBrick07_1 : 32|16@1+ (7.6e-05,0) [0|4.98066] "V" Host
 SG_ BATT_vBrick05_1 : 0|16@1+ (7.6e-05,0) [0|4.98066] "V" Host
 SG_ BATT_vBrick08_1 : 48|16@1+ (7.6e-05,0) [0|4.98066] "V" Host

BO_ 2566854648 BATT_diagnosticVBricksB_2: 8 Battery
 SG_ BATT_vBrick06_2 : 16|16@1+ (7.6e-05,0) [0|4.98066] "V" Host
 SG_ BATT_vBrick07_2 : 32|16@1+ (7.6e-05,0) [0|4.98066] "V" Host
 SG_ BATT_vBrick05_2 : 0|16@1+ (7.6e-05,0) [0|4.98066] "V" Host
 SG_ BATT_vBrick08_2 : 48|16@1+ (7.6e-05,0) [0|4.98066] "V" Host

BO_ 2566854649 BATT_diagnosticVBricksB_3: 8 Battery
 SG_ BATT_vBrick06_3 : 16|16@1+ (7.6e-05,0) [0|4.98066] "V" Host
 SG_ BATT_vBrick07_3 : 32|16@1+ (7.6e-05,0) [0|4.98066] "V" Host
 SG_ BATT_vBrick05_3 : 0|16@1+ (7.6e-05,0) [0|4.98066] "V" Host
 SG_ BATT_vBrick08_3 : 48|16@1+ (7.6e-05,0) [0|4.98066] "V" Host

BO_ 2566854650 BATT_diagnosticVBricksB_4: 8 Battery
 SG_ BATT_vBrick06_4 : 16|16@1+ (7.6e-05,0) [0|4.98066] "V" Host
 SG_ BATT_vBrick07_4 : 32|16@1+ (7.6e-05,0) [0|4.98066] "V" Host
 SG_ BATT_vBrick05_4 : 0|16@1+ (7.6e-05,0) [0|4.98066] "V" Host
 SG_ BATT_vBrick08_4 : 48|16@1+ (7.6e-05,0) [0|4.98066] "V" Host

BO_ 2566854651 BATT_diagnosticVBricksB_5: 8 Battery
 SG_ BATT_vBrick06_5 : 16|16@1+ (7.6e-05,0) [0|4.98066] "V" Host
 SG_ BATT_vBrick07_5 : 32|16@1+ (7.6e-05,0) [0|4.98066] "V" Host
 SG_ BATT_vBrick05_5 : 0|16@1+ (7.6e-05,0) [0|4.98066] "V" Host
 SG_ BATT_vBrick08_5 : 48|16@1+ (7.6e-05,0) [0|4.98066] "V" Host

BO_ 2566854652 BATT_diagnosticVBricksB_6: 8 Battery
 SG_ BATT_vBrick06_6 : 16|16@1+ (7.6e-05,0) [0|4.98066] "V" Host
 SG_ BATT_vBrick07_6 : 32|16@1+ (7.6e-05,0) [0|4.98066] "V" Host
 SG_ BATT_vBrick05_6 : 0|16@1+ (7.6e-05,0) [0|4.98066] "V" Host
 SG_ BATT_vBrick08_6 : 48|16@1+ (7.6e-05,0) [0|4.98066] "V" Host

BO_ 2566854653 BATT_diagnosticVBricksB_7: 8 Battery
 SG_ BATT_vBrick06_7 : 16|16@1+ (7.6e-05,0) [0|4.98066] "V" Host
 SG_ BATT_vBrick07_7 : 32|16@1+ (7.6e-05,0) [0|4.98066] "V" Host
 SG_ BATT_vBrick05_7 : 0|16@1+ (7.6e-05,0) [0|4.98066] "V" Host
 SG_ BATT_vBrick08_7 : 48|16@1+ (7.6e-05,0) [0|4.98066] "V" Host

BO_ 2566854654 BATT_diagnosticVBricksB_8: 8 Battery
 SG_ BATT_vBrick06_8 : 16|16@1+ (7.6e-05,0) [0|4.98066] "V" Host
 SG_ BATT_vBrick07_8 : 32|16@1+ (7.6e-05,0) [0|4.98066] "V" Host
 SG_ BATT_vBrick05_8 : 0|16@1+ (7.6e-05,0) [0|4.98066] "V" Host
 SG_ BATT_vBrick08_8 : 48|16@1+ (7.6e-05,0) [0|4.98066] "V" Host

BO_ 2566854655 BATT_diagnosticVBricksB_9: 8 Battery
 SG_ BATT_vBrick06_9 : 16|16@1+ (7.6e-05,0) [0|4.98066] "V" Host
 SG_ BATT_vBrick07_9 : 32|16@1+ (7.6e-05,0) [0|4.98066] "V" Host
 SG_ BATT_vBrick05_9 : 0|16@1+ (7.6e-05,0) [0|4.98066] "V" Host
 SG_ BATT_vBrick08_9 : 48|16@1+ (7.6e-05,0) [0|4.98066] "V" Host

BO_ 2566854902 BATT_diagnosticResBricksB_0: 8 Battery
 SG_ BATT_resBrick08_0 : 48|16@1+ (0.01,0) [0|655.35] "mOhms" Host
 SG_ BATT_resBrick07_0 : 32|16@1+ (0.01,0) [0|655.35] "mOhms" Host
 SG_ BATT_resBrick06_0 : 16|16@1+ (0.01,0) [0|655.35] "mOhms" Host
 SG_ BATT_resBrick05_0 : 0|16@1+ (0.01,0) [0|655.35] "mOhms" Host

BO_ 2566854903 BATT_diagnosticResBricksB_1: 8 Battery
 SG_ BATT_resBrick08_1 : 48|16@1+ (0.01,0) [0|655.35] "mOhms" Host
 SG_ BATT_resBrick07_1 : 32|16@1+ (0.01,0) [0|655.35] "mOhms" Host
 SG_ BATT_resBrick06_1 : 16|16@1+ (0.01,0) [0|655.35] "mOhms" Host
 SG_ BATT_resBrick05_1 : 0|16@1+ (0.01,0) [0|655.35] "mOhms" Host

BO_ 2566854904 BATT_diagnosticResBricksB_2: 8 Battery
 SG_ BATT_resBrick08_2 : 48|16@1+ (0.01,0) [0|655.35] "mOhms" Host
 SG_ BATT_resBrick07_2 : 32|16@1+ (0.01,0) [0|655.35] "mOhms" Host
 SG_ BATT_resBrick06_2 : 16|16@1+ (0.01,0) [0|655.35] "mOhms" Host
 SG_ BATT_resBrick05_2 : 0|16@1+ (0.01,0) [0|655.35] "mOhms" Host

BO_ 2566854905 BATT_diagnosticResBricksB_3: 8 Battery
 SG_ BATT_resBrick08_3 : 48|16@1+ (0.01,0) [0|655.35] "mOhms" Host
 SG_ BATT_resBrick07_3 : 32|16@1+ (0.01,0) [0|655.35] "mOhms" Host
 SG_ BATT_resBrick06_3 : 16|16@1+ (0.01,0) [0|655.35] "mOhms" Host
 SG_ BATT_resBrick05_3 : 0|16@1+ (0.01,0) [0|655.35] "mOhms" Host

BO_ 2566854906 BATT_diagnosticResBricksB_4: 8 Battery
 SG_ BATT_resBrick08_4 : 48|16@1+ (0.01,0) [0|655.35] "mOhms" Host
 SG_ BATT_resBrick07_4 : 32|16@1+ (0.01,0) [0|655.35] "mOhms" Host
 SG_ BATT_resBrick06_4 : 16|16@1+ (0.01,0) [0|655.35] "mOhms" Host
 SG_ BATT_resBrick05_4 : 0|16@1+ (0.01,0) [0|655.35] "mOhms" Host

BO_ 2566854907 BATT_diagnosticResBricksB_5: 8 Battery
 SG_ BATT_resBrick08_5 : 48|16@1+ (0.01,0) [0|655.35] "mOhms" Host
 SG_ BATT_resBrick07_5 : 32|16@1+ (0.01,0) [0|655.35] "mOhms" Host
 SG_ BATT_resBrick06_5 : 16|16@1+ (0.01,0) [0|655.35] "mOhms" Host
 SG_ BATT_resBrick05_5 : 0|16@1+ (0.01,0) [0|655.35] "mOhms" Host

BO_ 2566854908 BATT_diagnosticResBricksB_6: 8 Battery
 SG_ BATT_resBrick08_6 : 48|16@1+ (0.01,0) [0|655.35] "mOhms" Host
 SG_ BATT_resBrick07_6 : 32|16@1+ (0.01,0) [0|655.35] "mOhms" Host
 SG_ BATT_resBrick06_6 : 16|16@1+ (0.01,0) [0|655.35] "mOhms" Host
 SG_ BATT_resBrick05_6 : 0|16@1+ (0.01,0) [0|655.35] "mOhms" Host

BO_ 2566854909 BATT_diagnosticResBricksB_7: 8 Battery
 SG_ BATT_resBrick08_7 : 48|16@1+ (0.01,0) [0|655.35] "mOhms" Host
 SG_ BATT_resBrick07_7 : 32|16@1+ (0.01,0) [0|655.35] "mOhms" Host
 SG_ BATT_resBrick06_7 : 16|16@1+ (0.01,0) [0|655.35] "mOhms" Host
 SG_ BATT_resBrick05_7 : 0|16@1+ (0.01,0) [0|655.35] "mOhms" Host

BO_ 2566854910 BATT_diagnosticResBricksB_8: 8 Battery
 SG_ BATT_resBrick08_8 : 48|16@1+ (0.01,0) [0|655.35] "mOhms" Host
 SG_ BATT_resBrick07_8 : 32|16@1+ (0.01,0) [0|655.35] "mOhms" Host
 SG_ BATT_resBrick06_8 : 16|16@1+ (0.01,0) [0|655.35] "mOhms" Host
 SG_ BATT_resBrick05_8 : 0|16@1+ (0.01,0) [0|655.35] "mOhms" Host

BO_ 2566854911 BATT_diagnosticResBricksB_9: 8 Battery
 SG_ BATT_resBrick08_9 : 48|16@1+ (0.01,0) [0|655.35] "mOhms" Host
 SG_ BATT_resBrick07_9 : 32|16@1+ (0.01,0) [0|655.35] "mOhms" Host
 SG_ BATT_resBrick06_9 : 16|16@1+ (0.01,0) [0|655.35] "mOhms" Host
 SG_ BATT_resBrick05_9 : 0|16@1+ (0.01,0) [0|655.35] "mOhms" Host

BO_ 2566855158 BATT_modTemperaturesB: 8 Battery
 SG_ BATT_tPreChg : 16|16@1- (0.1,0) [-40|125] "deg C" Host
 SG_ BATT_tShunt : 48|16@1- (0.1,0) [-40|125] "deg C" Host
 SG_ BATT_tFET : 32|16@1- (0.1,0) [-40|125] "deg C" Host

BO_ 2566857718 BATT_diagnosticSOHRBricksC_0: 8 Battery
 SG_ BATT_sohrBrick12_0 : 48|16@1+ (0.00075,0) [0|49.15125] "Ah" Host
 SG_ BATT_sohrBrick11_0 : 32|16@1+ (0.00075,0) [0|49.15125] "Ah" Host
 SG_ BATT_sohrBrick10_0 : 16|16@1+ (0.00075,0) [0|49.15125] "Ah" Host
 SG_ BATT_sohrBrick09_0 : 0|16@1+ (0.00075,0) [0|49.15125] "Ah" Host

BO_ 2566857719 BATT_diagnosticSOHRBricksC_1: 8 Battery
 SG_ BATT_sohrBrick12_1 : 48|16@1+ (0.00075,0) [0|49.15125] "Ah" Host
 SG_ BATT_sohrBrick11_1 : 32|16@1+ (0.00075,0) [0|49.15125] "Ah" Host
 SG_ BATT_sohrBrick10_1 : 16|16@1+ (0.00075,0) [0|49.15125] "Ah" Host
 SG_ BATT_sohrBrick09_1 : 0|16@1+ (0.00075,0) [0|49.15125] "Ah" Host

BO_ 2566857720 BATT_diagnosticSOHRBricksC_2: 8 Battery
 SG_ BATT_sohrBrick12_2 : 48|16@1+ (0.00075,0) [0|49.15125] "Ah" Host
 SG_ BATT_sohrBrick11_2 : 32|16@1+ (0.00075,0) [0|49.15125] "Ah" Host
 SG_ BATT_sohrBrick10_2 : 16|16@1+ (0.00075,0) [0|49.15125] "Ah" Host
 SG_ BATT_sohrBrick09_2 : 0|16@1+ (0.00075,0) [0|49.15125] "Ah" Host

BO_ 2566857721 BATT_diagnosticSOHRBricksC_3: 8 Battery
 SG_ BATT_sohrBrick12_3 : 48|16@1+ (0.00075,0) [0|49.15125] "Ah" Host
 SG_ BATT_sohrBrick11_3 : 32|16@1+ (0.00075,0) [0|49.15125] "Ah" Host
 SG_ BATT_sohrBrick10_3 : 16|16@1+ (0.00075,0) [0|49.15125] "Ah" Host
 SG_ BATT_sohrBrick09_3 : 0|16@1+ (0.00075,0) [0|49.15125] "Ah" Host

BO_ 2566857722 BATT_diagnosticSOHRBricksC_4: 8 Battery
 SG_ BATT_sohrBrick12_4 : 48|16@1+ (0.00075,0) [0|49.15125] "Ah" Host
 SG_ BATT_sohrBrick11_4 : 32|16@1+ (0.00075,0) [0|49.15125] "Ah" Host
 SG_ BATT_sohrBrick10_4 : 16|16@1+ (0.00075,0) [0|49.15125] "Ah" Host
 SG_ BATT_sohrBrick09_4 : 0|16@1+ (0.00075,0) [0|49.15125] "Ah" Host

BO_ 2566857723 BATT_diagnosticSOHRBricksC_5: 8 Battery
 SG_ BATT_sohrBrick12_5 : 48|16@1+ (0.00075,0) [0|49.15125] "Ah" Host
 SG_ BATT_sohrBrick11_5 : 32|16@1+ (0.00075,0) [0|49.15125] "Ah" Host
 SG_ BATT_sohrBrick10_5 : 16|16@1+ (0.00075,0) [0|49.15125] "Ah" Host
 SG_ BATT_sohrBrick09_5 : 0|16@1+ (0.00075,0) [0|49.15125] "Ah" Host

BO_ 2566857724 BATT_diagnosticSOHRBricksC_6: 8 Battery
 SG_ BATT_sohrBrick12_6 : 48|16@1+ (0.00075,0) [0|49.15125] "Ah" Host
 SG_ BATT_sohrBrick11_6 : 32|16@1+ (0.00075,0) [0|49.15125] "Ah" Host
 SG_ BATT_sohrBrick10_6 : 16|16@1+ (0.00075,0) [0|49.15125] "Ah" Host
 SG_ BATT_sohrBrick09_6 : 0|16@1+ (0.00075,0) [0|49.15125] "Ah" Host

BO_ 2566857725 BATT_diagnosticSOHRBricksC_7: 8 Battery
 SG_ BATT_sohrBrick12_7 : 48|16@1+ (0.00075,0) [0|49.15125] "Ah" Host
 SG_ BATT_sohrBrick11_7 : 32|16@1+ (0.00075,0) [0|49.15125] "Ah" Host
 SG_ BATT_sohrBrick10_7 : 16|16@1+ (0.00075,0) [0|49.15125] "Ah" Host
 SG_ BATT_sohrBrick09_7 : 0|16@1+ (0.00075,0) [0|49.15125] "Ah" Host

BO_ 2566857726 BATT_diagnosticSOHRBricksC_8: 8 Battery
 SG_ BATT_sohrBrick12_8 : 48|16@1+ (0.00075,0) [0|49.15125] "Ah" Host
 SG_ BATT_sohrBrick11_8 : 32|16@1+ (0.00075,0) [0|49.15125] "Ah" Host
 SG_ BATT_sohrBrick10_8 : 16|16@1+ (0.00075,0) [0|49.15125] "Ah" Host
 SG_ BATT_sohrBrick09_8 : 0|16@1+ (0.00075,0) [0|49.15125] "Ah" Host

BO_ 2566857727 BATT_diagnosticSOHRBricksC_9: 8 Battery
 SG_ BATT_sohrBrick12_9 : 48|16@1+ (0.00075,0) [0|49.15125] "Ah" Host
 SG_ BATT_sohrBrick11_9 : 32|16@1+ (0.00075,0) [0|49.15125] "Ah" Host
 SG_ BATT_sohrBrick10_9 : 16|16@1+ (0.00075,0) [0|49.15125] "Ah" Host
 SG_ BATT_sohrBrick09_9 : 0|16@1+ (0.00075,0) [0|49.15125] "Ah" Host

BO_ 2566858230 BATT_diagnosticSOCBricksC_0: 8 Battery
 SG_ BATT_socBrick12_0 : 48|10@1+ (0.1,0) [0|102.3] "%" Host
 SG_ BATT_socBrick11_0 : 32|10@1+ (0.1,0) [0|102.3] "%" Host
 SG_ BATT_socBrick09_0 : 0|10@1+ (0.1,0) [0|102.3] "%" Host
 SG_ BATT_socBrick10_0 : 16|10@1+ (0.1,0) [0|102.3] "%" Host

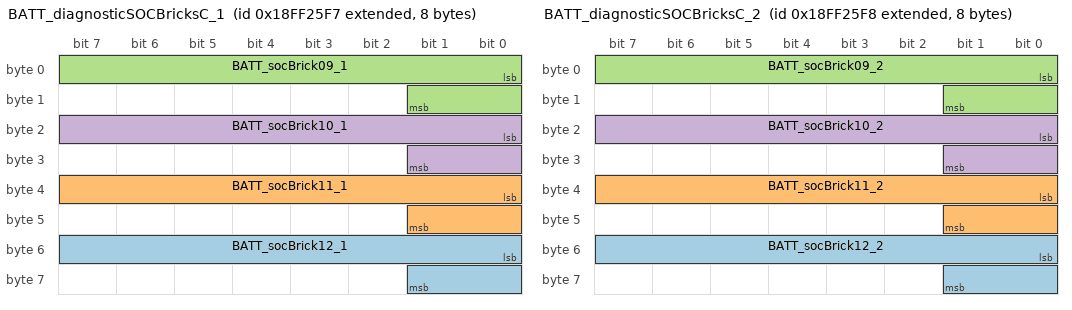
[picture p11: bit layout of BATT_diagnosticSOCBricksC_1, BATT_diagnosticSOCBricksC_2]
BO_ 2566858231 BATT_diagnosticSOCBricksC_1: 8 Battery
 SG_ BATT_socBrick12_1 : 48|10@1+ (0.1,0) [0|102.3] "%" Host
 SG_ BATT_socBrick11_1 : 32|10@1+ (0.1,0) [0|102.3] "%" Host
 SG_ BATT_socBrick09_1 : 0|10@1+ (0.1,0) [0|102.3] "%" Host
 SG_ BATT_socBrick10_1 : 16|10@1+ (0.1,0) [0|102.3] "%" Host

BO_ 2566858232 BATT_diagnosticSOCBricksC_2: 8 Battery
 SG_ BATT_socBrick12_2 : 48|10@1+ (0.1,0) [0|102.3] "%" Host
 SG_ BATT_socBrick11_2 : 32|10@1+ (0.1,0) [0|102.3] "%" Host
 SG_ BATT_socBrick09_2 : 0|10@1+ (0.1,0) [0|102.3] "%" Host
 SG_ BATT_socBrick10_2 : 16|10@1+ (0.1,0) [0|102.3] "%" Host

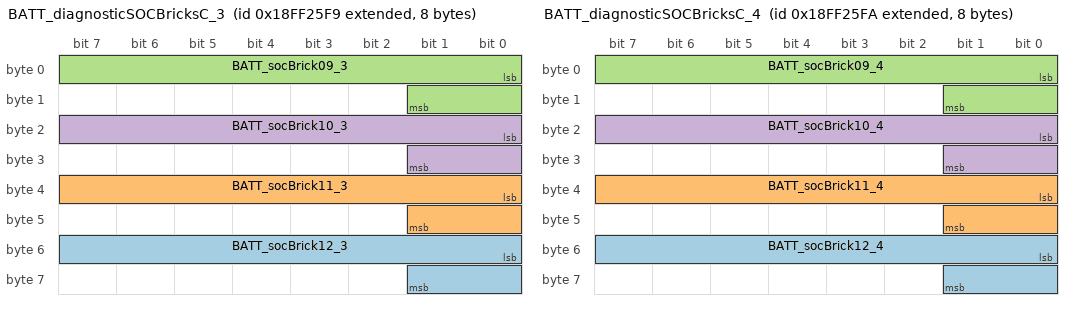
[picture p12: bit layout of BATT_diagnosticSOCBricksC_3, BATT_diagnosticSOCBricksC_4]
BO_ 2566858233 BATT_diagnosticSOCBricksC_3: 8 Battery
 SG_ BATT_socBrick12_3 : 48|10@1+ (0.1,0) [0|102.3] "%" Host
 SG_ BATT_socBrick11_3 : 32|10@1+ (0.1,0) [0|102.3] "%" Host
 SG_ BATT_socBrick09_3 : 0|10@1+ (0.1,0) [0|102.3] "%" Host
 SG_ BATT_socBrick10_3 : 16|10@1+ (0.1,0) [0|102.3] "%" Host

BO_ 2566858234 BATT_diagnosticSOCBricksC_4: 8 Battery
 SG_ BATT_socBrick12_4 : 48|10@1+ (0.1,0) [0|102.3] "%" Host
 SG_ BATT_socBrick11_4 : 32|10@1+ (0.1,0) [0|102.3] "%" Host
 SG_ BATT_socBrick09_4 : 0|10@1+ (0.1,0) [0|102.3] "%" Host
 SG_ BATT_socBrick10_4 : 16|10@1+ (0.1,0) [0|102.3] "%" Host

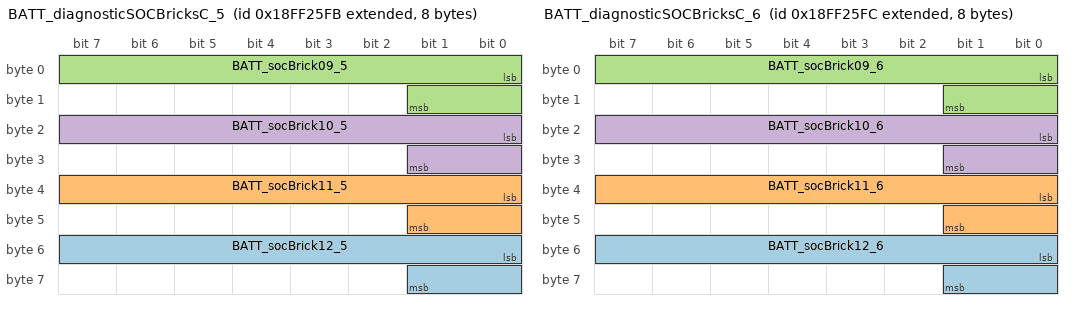
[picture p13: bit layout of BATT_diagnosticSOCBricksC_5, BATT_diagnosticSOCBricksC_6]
BO_ 2566858235 BATT_diagnosticSOCBricksC_5: 8 Battery
 SG_ BATT_socBrick12_5 : 48|10@1+ (0.1,0) [0|102.3] "%" Host
 SG_ BATT_socBrick11_5 : 32|10@1+ (0.1,0) [0|102.3] "%" Host
 SG_ BATT_socBrick09_5 : 0|10@1+ (0.1,0) [0|102.3] "%" Host
 SG_ BATT_socBrick10_5 : 16|10@1+ (0.1,0) [0|102.3] "%" Host

BO_ 2566858236 BATT_diagnosticSOCBricksC_6: 8 Battery
 SG_ BATT_socBrick12_6 : 48|10@1+ (0.1,0) [0|102.3] "%" Host
 SG_ BATT_socBrick11_6 : 32|10@1+ (0.1,0) [0|102.3] "%" Host
 SG_ BATT_socBrick09_6 : 0|10@1+ (0.1,0) [0|102.3] "%" Host
 SG_ BATT_socBrick10_6 : 16|10@1+ (0.1,0) [0|102.3] "%" Host

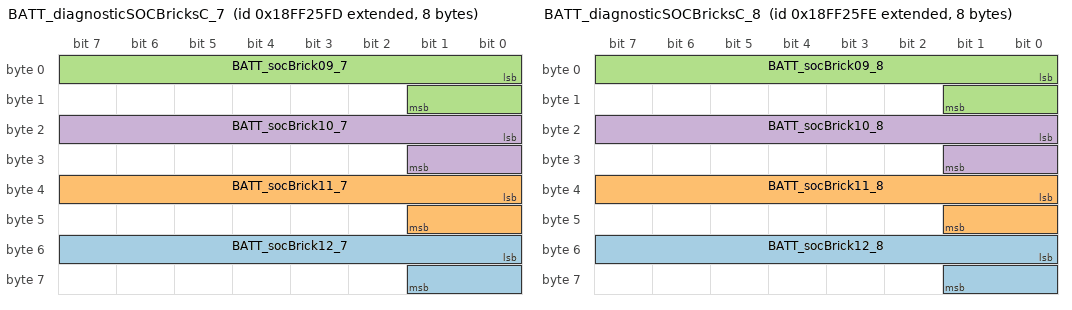
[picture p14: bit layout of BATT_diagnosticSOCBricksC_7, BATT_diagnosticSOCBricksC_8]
BO_ 2566858237 BATT_diagnosticSOCBricksC_7: 8 Battery
 SG_ BATT_socBrick12_7 : 48|10@1+ (0.1,0) [0|102.3] "%" Host
 SG_ BATT_socBrick11_7 : 32|10@1+ (0.1,0) [0|102.3] "%" Host
 SG_ BATT_socBrick09_7 : 0|10@1+ (0.1,0) [0|102.3] "%" Host
 SG_ BATT_socBrick10_7 : 16|10@1+ (0.1,0) [0|102.3] "%" Host

BO_ 2566858238 BATT_diagnosticSOCBricksC_8: 8 Battery
 SG_ BATT_socBrick12_8 : 48|10@1+ (0.1,0) [0|102.3] "%" Host
 SG_ BATT_socBrick11_8 : 32|10@1+ (0.1,0) [0|102.3] "%" Host
 SG_ BATT_socBrick09_8 : 0|10@1+ (0.1,0) [0|102.3] "%" Host
 SG_ BATT_socBrick10_8 : 16|10@1+ (0.1,0) [0|102.3] "%" Host

BO_ 2566858239 BATT_diagnosticSOCBricksC_9: 8 Battery
 SG_ BATT_socBrick12_9 : 48|10@1+ (0.1,0) [0|102.3] "%" Host
 SG_ BATT_socBrick11_9 : 32|10@1+ (0.1,0) [0|102.3] "%" Host
 SG_ BATT_socBrick09_9 : 0|10@1+ (0.1,0) [0|102.3] "%" Host
 SG_ BATT_socBrick10_9 : 16|10@1+ (0.1,0) [0|102.3] "%" Host

BO_ 2566858486 BATT_diagnosticCapBricksC_0: 8 Battery
 SG_ BATT_capBrick12_0 : 48|16@1+ (0.0025,0) [0|163.8375] "Ah" Host
 SG_ BATT_capBrick11_0 : 32|16@1+ (0.0025,0) [0|163.8375] "Ah" Host
 SG_ BATT_capBrick09_0 : 0|16@1+ (0.0025,0) [0|163.8375] "Ah" Host
 SG_ BATT_capBrick10_0 : 16|16@1+ (0.0025,0) [0|163.8375] "Ah" Host

BO_ 2566858487 BATT_diagnosticCapBricksC_1: 8 Battery
 SG_ BATT_capBrick12_1 : 48|16@1+ (0.0025,0) [0|163.8375] "Ah" Host
 SG_ BATT_capBrick11_1 : 32|16@1+ (0.0025,0) [0|163.8375] "Ah" Host
 SG_ BATT_capBrick09_1 : 0|16@1+ (0.0025,0) [0|163.8375] "Ah" Host
 SG_ BATT_capBrick10_1 : 16|16@1+ (0.0025,0) [0|163.8375] "Ah" Host

BO_ 2566858488 BATT_diagnosticCapBricksC_2: 8 Battery
 SG_ BATT_capBrick12_2 : 48|16@1+ (0.0025,0) [0|163.8375] "Ah" Host
 SG_ BATT_capBrick11_2 : 32|16@1+ (0.0025,0) [0|163.8375] "Ah" Host
 SG_ BATT_capBrick09_2 : 0|16@1+ (0.0025,0) [0|163.8375] "Ah" Host
 SG_ BATT_capBrick10_2 : 16|16@1+ (0.0025,0) [0|163.8375] "Ah" Host

BO_ 2566858489 BATT_diagnosticCapBricksC_3: 8 Battery
 SG_ BATT_capBrick12_3 : 48|16@1+ (0.0025,0) [0|163.8375] "Ah" Host
 SG_ BATT_capBrick11_3 : 32|16@1+ (0.0025,0) [0|163.8375] "Ah" Host
 SG_ BATT_capBrick09_3 : 0|16@1+ (0.0025,0) [0|163.8375] "Ah" Host
 SG_ BATT_capBrick10_3 : 16|16@1+ (0.0025,0) [0|163.8375] "Ah" Host

BO_ 2566858490 BATT_diagnosticCapBricksC_4: 8 Battery
 SG_ BATT_capBrick12_4 : 48|16@1+ (0.0025,0) [0|163.8375] "Ah" Host
 SG_ BATT_capBrick11_4 : 32|16@1+ (0.0025,0) [0|163.8375] "Ah" Host
 SG_ BATT_capBrick09_4 : 0|16@1+ (0.0025,0) [0|163.8375] "Ah" Host
 SG_ BATT_capBrick10_4 : 16|16@1+ (0.0025,0) [0|163.8375] "Ah" Host

BO_ 2566858491 BATT_diagnosticCapBricksC_5: 8 Battery
 SG_ BATT_capBrick12_5 : 48|16@1+ (0.0025,0) [0|163.8375] "Ah" Host
 SG_ BATT_capBrick11_5 : 32|16@1+ (0.0025,0) [0|163.8375] "Ah" Host
 SG_ BATT_capBrick09_5 : 0|16@1+ (0.0025,0) [0|163.8375] "Ah" Host
 SG_ BATT_capBrick10_5 : 16|16@1+ (0.0025,0) [0|163.8375] "Ah" Host

BO_ 2566858492 BATT_diagnosticCapBricksC_6: 8 Battery
 SG_ BATT_capBrick12_6 : 48|16@1+ (0.0025,0) [0|163.8375] "Ah" Host
 SG_ BATT_capBrick11_6 : 32|16@1+ (0.0025,0) [0|163.8375] "Ah" Host
 SG_ BATT_capBrick09_6 : 0|16@1+ (0.0025,0) [0|163.8375] "Ah" Host
 SG_ BATT_capBrick10_6 : 16|16@1+ (0.0025,0) [0|163.8375] "Ah" Host

BO_ 2566858493 BATT_diagnosticCapBricksC_7: 8 Battery
 SG_ BATT_capBrick12_7 : 48|16@1+ (0.0025,0) [0|163.8375] "Ah" Host
 SG_ BATT_capBrick11_7 : 32|16@1+ (0.0025,0) [0|163.8375] "Ah" Host
 SG_ BATT_capBrick09_7 : 0|16@1+ (0.0025,0) [0|163.8375] "Ah" Host
 SG_ BATT_capBrick10_7 : 16|16@1+ (0.0025,0) [0|163.8375] "Ah" Host

BO_ 2566858494 BATT_diagnosticCapBricksC_8: 8 Battery
 SG_ BATT_capBrick12_8 : 48|16@1+ (0.0025,0) [0|163.8375] "Ah" Host
 SG_ BATT_capBrick11_8 : 32|16@1+ (0.0025,0) [0|163.8375] "Ah" Host
 SG_ BATT_capBrick09_8 : 0|16@1+ (0.0025,0) [0|163.8375] "Ah" Host
 SG_ BATT_capBrick10_8 : 16|16@1+ (0.0025,0) [0|163.8375] "Ah" Host

BO_ 2566858495 BATT_diagnosticCapBricksC_9: 8 Battery
 SG_ BATT_capBrick12_9 : 48|16@1+ (0.0025,0) [0|163.8375] "Ah" Host
 SG_ BATT_capBrick11_9 : 32|16@1+ (0.0025,0) [0|163.8375] "Ah" Host
 SG_ BATT_capBrick09_9 : 0|16@1+ (0.0025,0) [0|163.8375] "Ah" Host
 SG_ BATT_capBrick10_9 : 16|16@1+ (0.0025,0) [0|163.8375] "Ah" Host

BO_ 2566858742 BATT_diagnosticVBricksC_0: 8 Battery
 SG_ BATT_vBrick12_0 : 48|16@1+ (7.6e-05,0) [0|4.98066] "V" Host
 SG_ BATT_vBrick11_0 : 32|16@1+ (7.6e-05,0) [0|4.98066] "V" Host
 SG_ BATT_vBrick10_0 : 16|16@1+ (7.6e-05,0) [0|4.98066] "V" Host
 SG_ BATT_vBrick09_0 : 0|16@1+ (7.6e-05,0) [0|4.98066] "V" Host

BO_ 2566858743 BATT_diagnosticVBricksC_1: 8 Battery
 SG_ BATT_vBrick12_1 : 48|16@1+ (7.6e-05,0) [0|4.98066] "V" Host
 SG_ BATT_vBrick11_1 : 32|16@1+ (7.6e-05,0) [0|4.98066] "V" Host
 SG_ BATT_vBrick10_1 : 16|16@1+ (7.6e-05,0) [0|4.98066] "V" Host
 SG_ BATT_vBrick09_1 : 0|16@1+ (7.6e-05,0) [0|4.98066] "V" Host

BO_ 2566858744 BATT_diagnosticVBricksC_2: 8 Battery
 SG_ BATT_vBrick12_2 : 48|16@1+ (7.6e-05,0) [0|4.98066] "V" Host
 SG_ BATT_vBrick11_2 : 32|16@1+ (7.6e-05,0) [0|4.98066] "V" Host
 SG_ BATT_vBrick10_2 : 16|16@1+ (7.6e-05,0) [0|4.98066] "V" Host
 SG_ BATT_vBrick09_2 : 0|16@1+ (7.6e-05,0) [0|4.98066] "V" Host

BO_ 2566858745 BATT_diagnosticVBricksC_3: 8 Battery
 SG_ BATT_vBrick12_3 : 48|16@1+ (7.6e-05,0) [0|4.98066] "V" Host
 SG_ BATT_vBrick11_3 : 32|16@1+ (7.6e-05,0) [0|4.98066] "V" Host
 SG_ BATT_vBrick10_3 : 16|16@1+ (7.6e-05,0) [0|4.98066] "V" Host
 SG_ BATT_vBrick09_3 : 0|16@1+ (7.6e-05,0) [0|4.98066] "V" Host

BO_ 2566858746 BATT_diagnosticVBricksC_4: 8 Battery
 SG_ BATT_vBrick12_4 : 48|16@1+ (7.6e-05,0) [0|4.98066] "V" Host
 SG_ BATT_vBrick11_4 : 32|16@1+ (7.6e-05,0) [0|4.98066] "V" Host
 SG_ BATT_vBrick10_4 : 16|16@1+ (7.6e-05,0) [0|4.98066] "V" Host
 SG_ BATT_vBrick09_4 : 0|16@1+ (7.6e-05,0) [0|4.98066] "V" Host

BO_ 2566858747 BATT_diagnosticVBricksC_5: 8 Battery
 SG_ BATT_vBrick12_5 : 48|16@1+ (7.6e-05,0) [0|4.98066] "V" Host
 SG_ BATT_vBrick11_5 : 32|16@1+ (7.6e-05,0) [0|4.98066] "V" Host
 SG_ BATT_vBrick10_5 : 16|16@1+ (7.6e-05,0) [0|4.98066] "V" Host
 SG_ BATT_vBrick09_5 : 0|16@1+ (7.6e-05,0) [0|4.98066] "V" Host

BO_ 2566858748 BATT_diagnosticVBricksC_6: 8 Battery
 SG_ BATT_vBrick12_6 : 48|16@1+ (7.6e-05,0) [0|4.98066] "V" Host
 SG_ BATT_vBrick11_6 : 32|16@1+ (7.6e-05,0) [0|4.98066] "V" Host
 SG_ BATT_vBrick10_6 : 16|16@1+ (7.6e-05,0) [0|4.98066] "V" Host
 SG_ BATT_vBrick09_6 : 0|16@1+ (7.6e-05,0) [0|4.98066] "V" Host

BO_ 2566858749 BATT_diagnosticVBricksC_7: 8 Battery
 SG_ BATT_vBrick12_7 : 48|16@1+ (7.6e-05,0) [0|4.98066] "V" Host
 SG_ BATT_vBrick11_7 : 32|16@1+ (7.6e-05,0) [0|4.98066] "V" Host
 SG_ BATT_vBrick10_7 : 16|16@1+ (7.6e-05,0) [0|4.98066] "V" Host
 SG_ BATT_vBrick09_7 : 0|16@1+ (7.6e-05,0) [0|4.98066] "V" Host

BO_ 2566858750 BATT_diagnosticVBricksC_8: 8 Battery
 SG_ BATT_vBrick12_8 : 48|16@1+ (7.6e-05,0) [0|4.98066] "V" Host
 SG_ BATT_vBrick11_8 : 32|16@1+ (7.6e-05,0) [0|4.98066] "V" Host
 SG_ BATT_vBrick10_8 : 16|16@1+ (7.6e-05,0) [0|4.98066] "V" Host
 SG_ BATT_vBrick09_8 : 0|16@1+ (7.6e-05,0) [0|4.98066] "V" Host

BO_ 2566858751 BATT_diagnosticVBricksC_9: 8 Battery
 SG_ BATT_vBrick12_9 : 48|16@1+ (7.6e-05,0) [0|4.98066] "V" Host
 SG_ BATT_vBrick11_9 : 32|16@1+ (7.6e-05,0) [0|4.98066] "V" Host
 SG_ BATT_vBrick10_9 : 16|16@1+ (7.6e-05,0) [0|4.98066] "V" Host
 SG_ BATT_vBrick09_9 : 0|16@1+ (7.6e-05,0) [0|4.98066] "V" Host

BO_ 2566858998 BATT_diagnosticResBricksC_0: 8 Battery
 SG_ BATT_resBrick12_0 : 48|16@1+ (0.01,0) [0|655.35] "mOhms" Host
 SG_ BATT_resBrick11_0 : 32|16@1+ (0.01,0) [0|655.35] "mOhms" Host
 SG_ BATT_resBrick09_0 : 0|16@1+ (0.01,0) [0|655.35] "mOhms" Host
 SG_ BATT_resBrick10_0 : 16|16@1+ (0.01,0) [0|655.35] "mOhms" Host

BO_ 2566858999 BATT_diagnosticResBricksC_1: 8 Battery
 SG_ BATT_resBrick12_1 : 48|16@1+ (0.01,0) [0|655.35] "mOhms" Host
 SG_ BATT_resBrick11_1 : 32|16@1+ (0.01,0) [0|655.35] "mOhms" Host
 SG_ BATT_resBrick09_1 : 0|16@1+ (0.01,0) [0|655.35] "mOhms" Host
 SG_ BATT_resBrick10_1 : 16|16@1+ (0.01,0) [0|655.35] "mOhms" Host

BO_ 2566859000 BATT_diagnosticResBricksC_2: 8 Battery
 SG_ BATT_resBrick12_2 : 48|16@1+ (0.01,0) [0|655.35] "mOhms" Host
 SG_ BATT_resBrick11_2 : 32|16@1+ (0.01,0) [0|655.35] "mOhms" Host
 SG_ BATT_resBrick09_2 : 0|16@1+ (0.01,0) [0|655.35] "mOhms" Host
 SG_ BATT_resBrick10_2 : 16|16@1+ (0.01,0) [0|655.35] "mOhms" Host

BO_ 2566859001 BATT_diagnosticResBricksC_3: 8 Battery
 SG_ BATT_resBrick12_3 : 48|16@1+ (0.01,0) [0|655.35] "mOhms" Host
 SG_ BATT_resBrick11_3 : 32|16@1+ (0.01,0) [0|655.35] "mOhms" Host
 SG_ BATT_resBrick09_3 : 0|16@1+ (0.01,0) [0|655.35] "mOhms" Host
 SG_ BATT_resBrick10_3 : 16|16@1+ (0.01,0) [0|655.35] "mOhms" Host

BO_ 2566859002 BATT_diagnosticResBricksC_4: 8 Battery
 SG_ BATT_resBrick12_4 : 48|16@1+ (0.01,0) [0|655.35] "mOhms" Host
 SG_ BATT_resBrick11_4 : 32|16@1+ (0.01,0) [0|655.35] "mOhms" Host
 SG_ BATT_resBrick09_4 : 0|16@1+ (0.01,0) [0|655.35] "mOhms" Host
 SG_ BATT_resBrick10_4 : 16|16@1+ (0.01,0) [0|655.35] "mOhms" Host

BO_ 2566859003 BATT_diagnosticResBricksC_5: 8 Battery
 SG_ BATT_resBrick12_5 : 48|16@1+ (0.01,0) [0|655.35] "mOhms" Host
 SG_ BATT_resBrick11_5 : 32|16@1+ (0.01,0) [0|655.35] "mOhms" Host
 SG_ BATT_resBrick09_5 : 0|16@1+ (0.01,0) [0|655.35] "mOhms" Host
 SG_ BATT_resBrick10_5 : 16|16@1+ (0.01,0) [0|655.35] "mOhms" Host

BO_ 2566859004 BATT_diagnosticResBricksC_6: 8 Battery
 SG_ BATT_resBrick12_6 : 48|16@1+ (0.01,0) [0|655.35] "mOhms" Host
 SG_ BATT_resBrick11_6 : 32|16@1+ (0.01,0) [0|655.35] "mOhms" Host
 SG_ BATT_resBrick09_6 : 0|16@1+ (0.01,0) [0|655.35] "mOhms" Host
 SG_ BATT_resBrick10_6 : 16|16@1+ (0.01,0) [0|655.35] "mOhms" Host

BO_ 2566859005 BATT_diagnosticResBricksC_7: 8 Battery
 SG_ BATT_resBrick12_7 : 48|16@1+ (0.01,0) [0|655.35] "mOhms" Host
 SG_ BATT_resBrick11_7 : 32|16@1+ (0.01,0) [0|655.35] "mOhms" Host
 SG_ BATT_resBrick09_7 : 0|16@1+ (0.01,0) [0|655.35] "mOhms" Host
 SG_ BATT_resBrick10_7 : 16|16@1+ (0.01,0) [0|655.35] "mOhms" Host

BO_ 2566859006 BATT_diagnosticResBricksC_8: 8 Battery
 SG_ BATT_resBrick12_8 : 48|16@1+ (0.01,0) [0|655.35] "mOhms" Host
 SG_ BATT_resBrick11_8 : 32|16@1+ (0.01,0) [0|655.35] "mOhms" Host
 SG_ BATT_resBrick09_8 : 0|16@1+ (0.01,0) [0|655.35] "mOhms" Host
 SG_ BATT_resBrick10_8 : 16|16@1+ (0.01,0) [0|655.35] "mOhms" Host

BO_ 2566859007 BATT_diagnosticResBricksC_9: 8 Battery
 SG_ BATT_resBrick12_9 : 48|16@1+ (0.01,0) [0|655.35] "mOhms" Host
 SG_ BATT_resBrick11_9 : 32|16@1+ (0.01,0) [0|655.35] "mOhms" Host
 SG_ BATT_resBrick09_9 : 0|16@1+ (0.01,0) [0|655.35] "mOhms" Host
 SG_ BATT_resBrick10_9 : 16|16@1+ (0.01,0) [0|655.35] "mOhms" Host

BO_ 2566861814 BATT_diagnosticSOHRBricksD_0: 4 Battery
 SG_ BATT_sohrBrick14_0 : 16|16@1+ (0.00075,0) [0|49.15125] "Ah" Host
 SG_ BATT_sohrBrick13_0 : 0|16@1+ (0.00075,0) [0|49.15125] "Ah" Host

BO_ 2566861815 BATT_diagnosticSOHRBricksD_1: 4 Battery
 SG_ BATT_sohrBrick14_1 : 16|16@1+ (0.00075,0) [0|49.15125] "Ah" Host
 SG_ BATT_sohrBrick13_1 : 0|16@1+ (0.00075,0) [0|49.15125] "Ah" Host

BO_ 2566861816 BATT_diagnosticSOHRBricksD_2: 4 Battery
 SG_ BATT_sohrBrick14_2 : 16|16@1+ (0.00075,0) [0|49.15125] "Ah" Host
 SG_ BATT_sohrBrick13_2 : 0|16@1+ (0.00075,0) [0|49.15125] "Ah" Host

BO_ 2566861817 BATT_diagnosticSOHRBricksD_3: 4 Battery
 SG_ BATT_sohrBrick14_3 : 16|16@1+ (0.00075,0) [0|49.15125] "Ah" Host
 SG_ BATT_sohrBrick13_3 : 0|16@1+ (0.00075,0) [0|49.15125] "Ah" Host

BO_ 2566861818 BATT_diagnosticSOHRBricksD_4: 4 Battery
 SG_ BATT_sohrBrick14_4 : 16|16@1+ (0.00075,0) [0|49.15125] "Ah" Host
 SG_ BATT_sohrBrick13_4 : 0|16@1+ (0.00075,0) [0|49.15125] "Ah" Host

BO_ 2566861819 BATT_diagnosticSOHRBricksD_5: 4 Battery
 SG_ BATT_sohrBrick14_5 : 16|16@1+ (0.00075,0) [0|49.15125] "Ah" Host
 SG_ BATT_sohrBrick13_5 : 0|16@1+ (0.00075,0) [0|49.15125] "Ah" Host

BO_ 2566861820 BATT_diagnosticSOHRBricksD_6: 4 Battery
 SG_ BATT_sohrBrick14_6 : 16|16@1+ (0.00075,0) [0|49.15125] "Ah" Host
 SG_ BATT_sohrBrick13_6 : 0|16@1+ (0.00075,0) [0|49.15125] "Ah" Host

BO_ 2566861821 BATT_diagnosticSOHRBricksD_7: 4 Battery
 SG_ BATT_sohrBrick14_7 : 16|16@1+ (0.00075,0) [0|49.15125] "Ah" Host
 SG_ BATT_sohrBrick13_7 : 0|16@1+ (0.00075,0) [0|49.15125] "Ah" Host

BO_ 2566861822 BATT_diagnosticSOHRBricksD_8: 4 Battery
 SG_ BATT_sohrBrick14_8 : 16|16@1+ (0.00075,0) [0|49.15125] "Ah" Host
 SG_ BATT_sohrBrick13_8 : 0|16@1+ (0.00075,0) [0|49.15125] "Ah" Host

BO_ 2566861823 BATT_diagnosticSOHRBricksD_9: 4 Battery
 SG_ BATT_sohrBrick14_9 : 16|16@1+ (0.00075,0) [0|49.15125] "Ah" Host
 SG_ BATT_sohrBrick13_9 : 0|16@1+ (0.00075,0) [0|49.15125] "Ah" Host

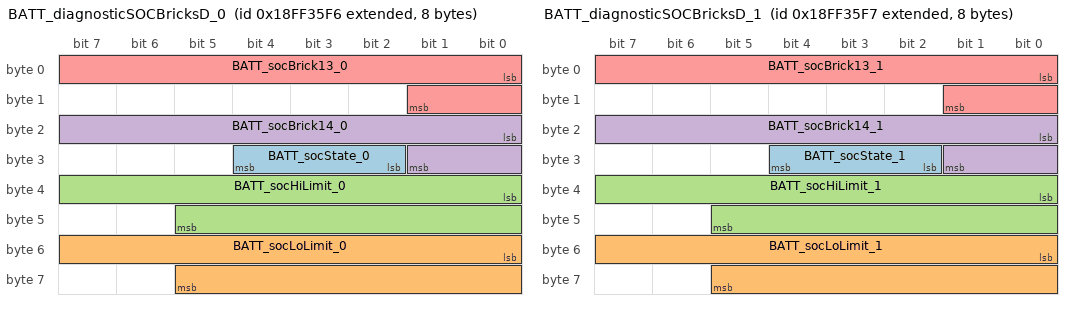
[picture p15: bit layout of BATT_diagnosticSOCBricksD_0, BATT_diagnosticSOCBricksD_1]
BO_ 2566862326 BATT_diagnosticSOCBricksD_0: 8 Battery
 SG_ BATT_socState_0 : 26|3@1+ (1,0) [0|7] "" Host
 SG_ BATT_socLoLimit_0 : 48|14@1+ (1,0) [0|16383] "" Host
 SG_ BATT_socHiLimit_0 : 32|14@1+ (1,0) [0|16383] "" Host
 SG_ BATT_socBrick14_0 : 16|10@1+ (0.1,0) [0|102.3] "%" Host
 SG_ BATT_socBrick13_0 : 0|10@1+ (0.1,0) [0|102.3] "%" Host

BO_ 2566862327 BATT_diagnosticSOCBricksD_1: 8 Battery
 SG_ BATT_socState_1 : 26|3@1+ (1,0) [0|7] "" Host
 SG_ BATT_socLoLimit_1 : 48|14@1+ (1,0) [0|16383] "" Host
 SG_ BATT_socHiLimit_1 : 32|14@1+ (1,0) [0|16383] "" Host
 SG_ BATT_socBrick14_1 : 16|10@1+ (0.1,0) [0|102.3] "%" Host
 SG_ BATT_socBrick13_1 : 0|10@1+ (0.1,0) [0|102.3] "%" Host

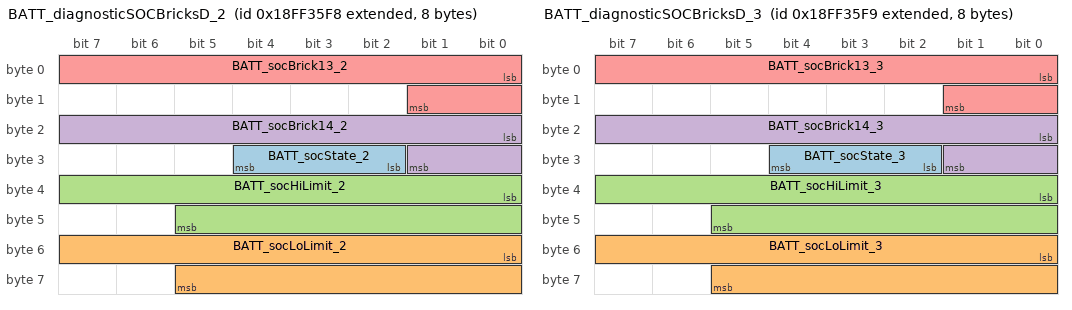
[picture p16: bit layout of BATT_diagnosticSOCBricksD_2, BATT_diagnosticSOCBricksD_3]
BO_ 2566862328 BATT_diagnosticSOCBricksD_2: 8 Battery
 SG_ BATT_socState_2 : 26|3@1+ (1,0) [0|7] "" Host
 SG_ BATT_socLoLimit_2 : 48|14@1+ (1,0) [0|16383] "" Host
 SG_ BATT_socHiLimit_2 : 32|14@1+ (1,0) [0|16383] "" Host
 SG_ BATT_socBrick14_2 : 16|10@1+ (0.1,0) [0|102.3] "%" Host
 SG_ BATT_socBrick13_2 : 0|10@1+ (0.1,0) [0|102.3] "%" Host

BO_ 2566862329 BATT_diagnosticSOCBricksD_3: 8 Battery
 SG_ BATT_socState_3 : 26|3@1+ (1,0) [0|7] "" Host
 SG_ BATT_socLoLimit_3 : 48|14@1+ (1,0) [0|16383] "" Host
 SG_ BATT_socHiLimit_3 : 32|14@1+ (1,0) [0|16383] "" Host
 SG_ BATT_socBrick14_3 : 16|10@1+ (0.1,0) [0|102.3] "%" Host
 SG_ BATT_socBrick13_3 : 0|10@1+ (0.1,0) [0|102.3] "%" Host

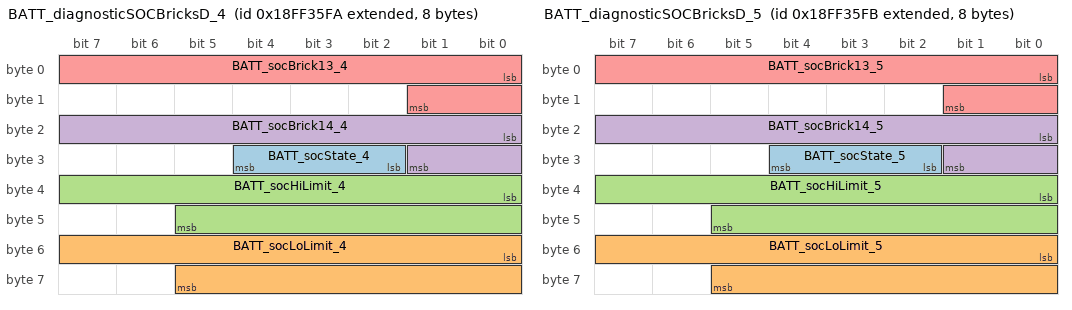
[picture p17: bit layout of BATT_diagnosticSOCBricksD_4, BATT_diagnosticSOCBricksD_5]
BO_ 2566862330 BATT_diagnosticSOCBricksD_4: 8 Battery
 SG_ BATT_socState_4 : 26|3@1+ (1,0) [0|7] "" Host
 SG_ BATT_socLoLimit_4 : 48|14@1+ (1,0) [0|16383] "" Host
 SG_ BATT_socHiLimit_4 : 32|14@1+ (1,0) [0|16383] "" Host
 SG_ BATT_socBrick14_4 : 16|10@1+ (0.1,0) [0|102.3] "%" Host
 SG_ BATT_socBrick13_4 : 0|10@1+ (0.1,0) [0|102.3] "%" Host

BO_ 2566862331 BATT_diagnosticSOCBricksD_5: 8 Battery
 SG_ BATT_socState_5 : 26|3@1+ (1,0) [0|7] "" Host
 SG_ BATT_socLoLimit_5 : 48|14@1+ (1,0) [0|16383] "" Host
 SG_ BATT_socHiLimit_5 : 32|14@1+ (1,0) [0|16383] "" Host
 SG_ BATT_socBrick14_5 : 16|10@1+ (0.1,0) [0|102.3] "%" Host
 SG_ BATT_socBrick13_5 : 0|10@1+ (0.1,0) [0|102.3] "%" Host

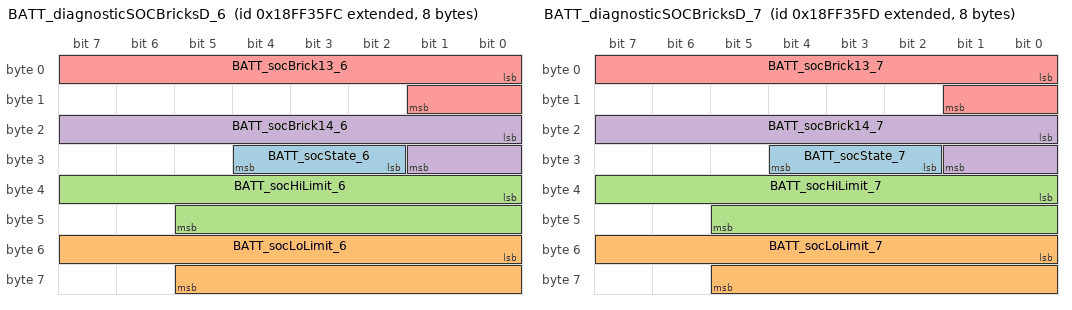
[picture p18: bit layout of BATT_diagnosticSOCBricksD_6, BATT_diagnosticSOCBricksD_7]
BO_ 2566862332 BATT_diagnosticSOCBricksD_6: 8 Battery
 SG_ BATT_socState_6 : 26|3@1+ (1,0) [0|7] "" Host
 SG_ BATT_socLoLimit_6 : 48|14@1+ (1,0) [0|16383] "" Host
 SG_ BATT_socHiLimit_6 : 32|14@1+ (1,0) [0|16383] "" Host
 SG_ BATT_socBrick14_6 : 16|10@1+ (0.1,0) [0|102.3] "%" Host
 SG_ BATT_socBrick13_6 : 0|10@1+ (0.1,0) [0|102.3] "%" Host

BO_ 2566862333 BATT_diagnosticSOCBricksD_7: 8 Battery
 SG_ BATT_socState_7 : 26|3@1+ (1,0) [0|7] "" Host
 SG_ BATT_socLoLimit_7 : 48|14@1+ (1,0) [0|16383] "" Host
 SG_ BATT_socHiLimit_7 : 32|14@1+ (1,0) [0|16383] "" Host
 SG_ BATT_socBrick14_7 : 16|10@1+ (0.1,0) [0|102.3] "%" Host
 SG_ BATT_socBrick13_7 : 0|10@1+ (0.1,0) [0|102.3] "%" Host

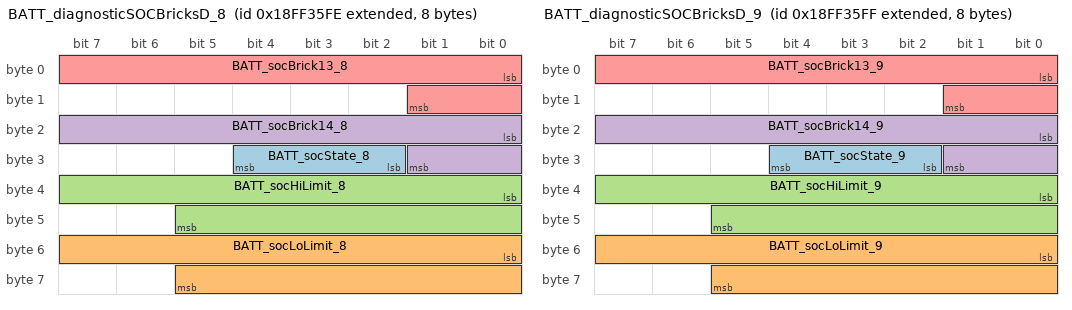
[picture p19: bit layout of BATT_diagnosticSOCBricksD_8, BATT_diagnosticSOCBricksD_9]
BO_ 2566862334 BATT_diagnosticSOCBricksD_8: 8 Battery
 SG_ BATT_socState_8 : 26|3@1+ (1,0) [0|7] "" Host
 SG_ BATT_socLoLimit_8 : 48|14@1+ (1,0) [0|16383] "" Host
 SG_ BATT_socHiLimit_8 : 32|14@1+ (1,0) [0|16383] "" Host
 SG_ BATT_socBrick14_8 : 16|10@1+ (0.1,0) [0|102.3] "%" Host
 SG_ BATT_socBrick13_8 : 0|10@1+ (0.1,0) [0|102.3] "%" Host

BO_ 2566862335 BATT_diagnosticSOCBricksD_9: 8 Battery
 SG_ BATT_socState_9 : 26|3@1+ (1,0) [0|7] "" Host
 SG_ BATT_socLoLimit_9 : 48|14@1+ (1,0) [0|16383] "" Host
 SG_ BATT_socHiLimit_9 : 32|14@1+ (1,0) [0|16383] "" Host
 SG_ BATT_socBrick14_9 : 16|10@1+ (0.1,0) [0|102.3] "%" Host
 SG_ BATT_socBrick13_9 : 0|10@1+ (0.1,0) [0|102.3] "%" Host

BO_ 2566862582 BATT_diagnosticCapBricksD_0: 8 Battery
 SG_ BATT_sohcUpdated_0 : 48|14@1+ (1,0) [0|16383] "" Host
 SG_ BATT_sohcPrimed_0 : 32|14@1+ (1,0) [0|16383] "" Host
 SG_ BATT_capBrick14_0 : 16|16@1+ (0.0025,0) [0|163.8375] "Ah" Host
 SG_ BATT_capBrick13_0 : 0|16@1+ (0.0025,0) [0|163.8375] "Ah" Host

BO_ 2566862583 BATT_diagnosticCapBricksD_1: 8 Battery
 SG_ BATT_sohcUpdated_1 : 48|14@1+ (1,0) [0|16383] "" Host
 SG_ BATT_sohcPrimed_1 : 32|14@1+ (1,0) [0|16383] "" Host
 SG_ BATT_capBrick14_1 : 16|16@1+ (0.0025,0) [0|163.8375] "Ah" Host
 SG_ BATT_capBrick13_1 : 0|16@1+ (0.0025,0) [0|163.8375] "Ah" Host

BO_ 2566862584 BATT_diagnosticCapBricksD_2: 8 Battery
 SG_ BATT_sohcUpdated_2 : 48|14@1+ (1,0) [0|16383] "" Host
 SG_ BATT_sohcPrimed_2 : 32|14@1+ (1,0) [0|16383] "" Host
 SG_ BATT_capBrick14_2 : 16|16@1+ (0.0025,0) [0|163.8375] "Ah" Host
 SG_ BATT_capBrick13_2 : 0|16@1+ (0.0025,0) [0|163.8375] "Ah" Host

BO_ 2566862585 BATT_diagnosticCapBricksD_3: 8 Battery
 SG_ BATT_sohcUpdated_3 : 48|14@1+ (1,0) [0|16383] "" Host
 SG_ BATT_sohcPrimed_3 : 32|14@1+ (1,0) [0|16383] "" Host
 SG_ BATT_capBrick14_3 : 16|16@1+ (0.0025,0) [0|163.8375] "Ah" Host
 SG_ BATT_capBrick13_3 : 0|16@1+ (0.0025,0) [0|163.8375] "Ah" Host

BO_ 2566862586 BATT_diagnosticCapBricksD_4: 8 Battery
 SG_ BATT_sohcUpdated_4 : 48|14@1+ (1,0) [0|16383] "" Host
 SG_ BATT_sohcPrimed_4 : 32|14@1+ (1,0) [0|16383] "" Host
 SG_ BATT_capBrick14_4 : 16|16@1+ (0.0025,0) [0|163.8375] "Ah" Host
 SG_ BATT_capBrick13_4 : 0|16@1+ (0.0025,0) [0|163.8375] "Ah" Host

BO_ 2566862587 BATT_diagnosticCapBricksD_5: 8 Battery
 SG_ BATT_sohcUpdated_5 : 48|14@1+ (1,0) [0|16383] "" Host
 SG_ BATT_sohcPrimed_5 : 32|14@1+ (1,0) [0|16383] "" Host
 SG_ BATT_capBrick14_5 : 16|16@1+ (0.0025,0) [0|163.8375] "Ah" Host
 SG_ BATT_capBrick13_5 : 0|16@1+ (0.0025,0) [0|163.8375] "Ah" Host

BO_ 2566862588 BATT_diagnosticCapBricksD_6: 8 Battery
 SG_ BATT_sohcUpdated_6 : 48|14@1+ (1,0) [0|16383] "" Host
 SG_ BATT_sohcPrimed_6 : 32|14@1+ (1,0) [0|16383] "" Host
 SG_ BATT_capBrick14_6 : 16|16@1+ (0.0025,0) [0|163.8375] "Ah" Host
 SG_ BATT_capBrick13_6 : 0|16@1+ (0.0025,0) [0|163.8375] "Ah" Host

BO_ 2566862589 BATT_diagnosticCapBricksD_7: 8 Battery
 SG_ BATT_sohcUpdated_7 : 48|14@1+ (1,0) [0|16383] "" Host
 SG_ BATT_sohcPrimed_7 : 32|14@1+ (1,0) [0|16383] "" Host
 SG_ BATT_capBrick14_7 : 16|16@1+ (0.0025,0) [0|163.8375] "Ah" Host
 SG_ BATT_capBrick13_7 : 0|16@1+ (0.0025,0) [0|163.8375] "Ah" Host

BO_ 2566862590 BATT_diagnosticCapBricksD_8: 8 Battery
 SG_ BATT_sohcUpdated_8 : 48|14@1+ (1,0) [0|16383] "" Host
 SG_ BATT_sohcPrimed_8 : 32|14@1+ (1,0) [0|16383] "" Host
 SG_ BATT_capBrick14_8 : 16|16@1+ (0.0025,0) [0|163.8375] "Ah" Host
 SG_ BATT_capBrick13_8 : 0|16@1+ (0.0025,0) [0|163.8375] "Ah" Host

BO_ 2566862591 BATT_diagnosticCapBricksD_9: 8 Battery
 SG_ BATT_sohcUpdated_9 : 48|14@1+ (1,0) [0|16383] "" Host
 SG_ BATT_sohcPrimed_9 : 32|14@1+ (1,0) [0|16383] "" Host
 SG_ BATT_capBrick14_9 : 16|16@1+ (0.0025,0) [0|163.8375] "Ah" Host
 SG_ BATT_capBrick13_9 : 0|16@1+ (0.0025,0) [0|163.8375] "Ah" Host

BO_ 2566862838 BATT_diagnosticVBricksD_0: 4 Battery
 SG_ BATT_vBrick14_0 : 16|16@1+ (7.6e-05,0) [0|4.98066] "V" Host
 SG_ BATT_vBrick13_0 : 0|16@1+ (7.6e-05,0) [0|4.98066] "V" Host

BO_ 2566862839 BATT_diagnosticVBricksD_1: 4 Battery
 SG_ BATT_vBrick14_1 : 16|16@1+ (7.6e-05,0) [0|4.98066] "V" Host
 SG_ BATT_vBrick13_1 : 0|16@1+ (7.6e-05,0) [0|4.98066] "V" Host

BO_ 2566862840 BATT_diagnosticVBricksD_2: 4 Battery
 SG_ BATT_vBrick14_2 : 16|16@1+ (7.6e-05,0) [0|4.98066] "V" Host
 SG_ BATT_vBrick13_2 : 0|16@1+ (7.6e-05,0) [0|4.98066] "V" Host

CM_ BO_ 2566852862 "Message with flags from event matrix";
CM_ SG_ 2566852862 BATT_packModIdFault_8 "0 - Battery pack module ID okay (default)
1 - Battery pack module ID fault";
CM_ SG_ 2566852862 BATT_packModExitedFromBus_8 "0 - Battery pack modules OK (default)
1 - Battery pack module(s) exited from the bus during charge or drive";
CM_ SG_ 2566852862 BATT_packFetChgWelded_8 "0 - Battery pack module CHG FETs not welded (default)
1 - Battery pack module CHG FETs welded ";
CM_ SG_ 2566852862 BATT_packFetDsgWelded_8 "0 - Battery pack module DSG FETs not welded (default)
1 - Battery pack module DSG FETs welded ";
CM_ SG_ 2566852862 BATT_fetDsgShortedAux_8 "0 - FETs are operational (default)
1 - FET is shorted detected by auxiliary diagnostic";
CM_ SG_ 2566852862 BATT_fetChgShortedAux_8 "0 - FETs are operational (default)
1 - FET is shorted detected by auxiliary diagnostic";
CM_ SG_ 2566852862 BATT_prechargeFetFail_8 "0 - Precharge FET okay (default)
1 - Precharge FET failed";
CM_ SG_ 2566852862 BATT_abnormalResetReason_8 "0 - Reset reason okay (default)
1 - Abnormal reset reason";
CM_ SG_ 2566852862 BATT_prechargeTooSlow_8 "0 - Precharge okay (default)
1 - Precharge too slow";
CM_ SG_ 2566852862 BATT_prechargeTooFast_8 "0 - Precharge okay (default)
1 - Precharge too fast";
CM_ SG_ 2566852862 BATT_prechargeTimeout_8 "0 - Precharge okay (default)
1 - Precharge timeout";
CM_ SG_ 2566852862 BATT_fetChgShorted_8 "0 - FETs are operational (default)
1 - FET is shorted";
CM_ SG_ 2566852862 BATT_fetChgFailToClose_8 "0 - FETs are operational (default)
1 -  FET fail to close";
CM_ SG_ 2566852862 BATT_packModSelectFault_8 "0 - Battery pack module selection okay (default)
1 - Battery pack module selection fault";
CM_ SG_ 2566852862 BATT_packModConnectFault_8 "0 - Battery pack module connection okay (default)
1 - Battery pack module connection fault";
CM_ SG_ 2566852862 BATT_packModMIA_8 "0 - Battery pack modules not MIA (default)
1 - Battery pack module MIA";
CM_ SG_ 2566852862 BATT_packModImbalance_8 "0 - Battery pack modules balanced (default)
1 - Battery pack module imblance present";
CM_ SG_ 2566852862 BATT_afeFault_8 "0 - BMS AFE okay (default)
1 - BMS AFE fault";
CM_ SG_ 2566852862 BATT_chargerMIA_8 "0 - Charger communications okay (default)
1 - Charger MIA";
CM_ SG_ 2566852862 BATT_chargerError_8 "0 - Charger working as intended (default)
1 - Charger error";
CM_ SG_ 2566852862 BATT_vBrickUnderWar_8 "0 - Brick voltage okay (default)
1 - Brick undervoltage warning";
CM_ SG_ 2566852862 BATT_vBrickUnderSev_8 "0 - Brick voltage okay (default)
1 - Brick undervoltage severe";
CM_ SG_ 2566852862 BATT_vBrickUnderMod_8 "0 - Brick voltage okay (default)
1 - Brick undervoltage moderate";
CM_ SG_ 2566852862 BATT_vBrickOverWar_8 "0 - Brick voltage okay (default)
1 - Brick overvoltage warning";
CM_ SG_ 2566852862 BATT_vBrickOverSev_8 "0 - Brick voltage okay (default)
1 - Brick overvoltage severe";
CM_ SG_ 2566852862 BATT_vBrickOverMod_8 "0 - Brick voltage okay (default)
1 - Brick overvoltage moderate";
CM_ SG_ 2566852862 BATT_vBrickImbalance_8 "0 - Battery brick voltage okay (default)
1 - Battery brick voltage imbalance";
CM_ SG_ 2566852862 BATT_loggerAlmostFull_8 "0 - Logger not almost full (default)
1 - Logger almost full (section >= 80%) ";
CM_ SG_ 2566852862 BATT_tempModuleUnderWar_8 "0 - Battery temperature okay (default)
1 - Battery under temperature warning";
CM_ SG_ 2566852862 BATT_tempModuleUnderSev_8 "0 - Battery temperature okay (default)
1 - Battery under temperature severe";
CM_ SG_ 2566852862 BATT_tempModuleUnderMod_8 "0 - Battery temperature okay (default)
1 - Battery under temperature moderate";
CM_ SG_ 2566852862 BATT_tempModuleOverWar_8 "0 - Battery temperature okay (default)
1 - Battery over temperature warning";
CM_ SG_ 2566852862 BATT_tempModuleOverSev_8 "0 - Battery temperature okay (default)
1 - Battery over temperature severe";
CM_ SG_ 2566852862 BATT_tempModuleOverMod_8 "0 - Battery temperature okay (default)
1 - Battery over temperature moderate";
CM_ SG_ 2566852862 BATT_tempBrickImbalance_8 "0 - Brick temperatures are balanced (default)
1 - Brick temperatures are imbalanced";
CM_ SG_ 2566852862 BATT_taskLockupError_8 "0 - Tasks okay (default)
1 - Task lockup error";
CM_ SG_ 2566852862 BATT_tempBoardOverWar_8 "0 - Ambient temperature okay (default)
1 - Ambient over temperature warning";
CM_ SG_ 2566852862 BATT_tempBoardOverSev_8 "0 - Temperature okay (default)
1 - Ambient over temperature severe";
CM_ SG_ 2566852862 BATT_tempBoardOverMod_8 "0 - Ambient temperature okay (default)
1 - Ambient over temparature moderate";
CM_ SG_ 2566852862 BATT_sensePackVoltError_8 "0 - Sensor okay (default)
1 - Sensor for pack voltage error";
CM_ SG_ 2566852862 BATT_senseLoadVoltError_8 "0 - Sensor okay (default)
1 - Sensor for load voltage error";
CM_ SG_ 2566852862 BATT_loggerFull_8 "0 - Logger not full (default)
1 - Logger full ";
CM_ SG_ 2566852862 BATT_senseCurrentError_8 "0 - Sensor okay (default)
1 - Sensor for current error";
CM_ SG_ 2566852862 BATT_senseBrickTempError_8 "0 - Sensor okay (default)
1 - Brick temperature sensor error";
CM_ SG_ 2566852862 BATT_resPackHigh_8 "0 - Battery pack resistance okay (default)
1 - Battery pack resistance high (High SOH-R)";
CM_ SG_ 2566852862 BATT_ramOverUtilError_8 "0 - RAM okay (default)
1 - RAM over utilization";
CM_ SG_ 2566852862 BATT_powerPackInsufficient_8 "0 - Battery pack power okay (default)
1 - Battery pack power insufficient";
CM_ SG_ 2566852862 BATT_packCellSoftShort_8 "0 - Battery back cells are okay (default)
1 - Battery pack cell soft short";
CM_ SG_ 2566852862 BATT_iOverHardware_8 "0 - Hardware current okay (default)
1 - Overcurrent in hardware";
CM_ SG_ 2566852862 BATT_fetOverTemp_8 "0 - FET temperature okay (default)
1 - Overtemp at FETs";
CM_ SG_ 2566852862 BATT_iOverDischarge_8 "0 - Discharge okay (default)
1 - Overcurrent during discharge";
CM_ SG_ 2566852862 BATT_iOverCharge_8 "0 - Charging okay (default)
1 - Overcurrent during charging";
CM_ SG_ 2566852862 BATT_inverterDriveMIA_8 "0 - Inverter drive present (default)
1 - Inverter drive MIA";
CM_ SG_ 2566852862 BATT_iUnderCharge_8 "0 - Normal charging (default)
1 -  Charging undercurrent (discharging)";
CM_ SG_ 2566852862 BATT_hostMIA_8 "0 - host communication open (default)
1 - host MIA";
CM_ SG_ 2566852862 BATT_fetDsgShorted_8 "0 - FETs are operational (default)
1 - FET is shorted";
CM_ SG_ 2566852862 BATT_fetDsgFailToClose_8 "0 - FETs are operational (default)
1 -  FET fail to close";
CM_ SG_ 2566852862 BATT_capLow_8 "0 - Battery capacity normal (SOH-C) (default)
1 - Low battery capacity (Low SOH-C)";
CM_ SG_ 2566852862 BATT_brickOverDischarge_8 "0 - Battery brick charge is normal (default)
1 - Battery brick is overdischarged";
CM_ SG_ 2566852862 BATT_brickOverCharge_8 "0 - Battery brick charge is normal (default)
1 - Battery brick is overcharged";
CM_ SG_ 2566852862 BATT_bmsProcessorError_8 "0 - No BMS processor failure (default)
1 - BMS processor failure";
CM_ SG_ 2566852862 BATT_bmsMemoryError_8 "0 - No BMS memory error
1 - BMS memory error";
CM_ SG_ 2566852862 BATT_afeError_8 "0 - No BMS AFE error (default)
1 - BMS AFE error";
CM_ BO_ 2566852863 "Message with flags from event matrix";
CM_ SG_ 2566852863 BATT_packModIdFault_9 "0 - Battery pack module ID okay (default)
1 - Battery pack module ID fault";
CM_ SG_ 2566852863 BATT_packModExitedFromBus_9 "0 - Battery pack modules OK (default)
1 - Battery pack module(s) exited from the bus during charge or drive";
CM_ SG_ 2566852863 BATT_packFetChgWelded_9 "0 - Battery pack module CHG FETs not welded (default)
1 - Battery pack module CHG FETs welded ";
CM_ SG_ 2566852863 BATT_packFetDsgWelded_9 "0 - Battery pack module DSG FETs not welded (default)
1 - Battery pack module DSG FETs welded ";
CM_ SG_ 2566852863 BATT_fetDsgShortedAux_9 "0 - FETs are operational (default)
1 - FET is shorted detected by auxiliary diagnostic";
CM_ SG_ 2566852863 BATT_fetChgShortedAux_9 "0 - FETs are operational (default)
1 - FET is shorted detected by auxiliary diagnostic";
CM_ SG_ 2566852863 BATT_prechargeFetFail_9 "0 - Precharge FET okay (default)
1 - Precharge FET failed";
CM_ SG_ 2566852863 BATT_abnormalResetReason_9 "0 - Reset reason okay (default)
1 - Abnormal reset reason";
CM_ SG_ 2566852863 BATT_prechargeTooSlow_9 "0 - Precharge okay (default)
1 - Precharge too slow";
CM_ SG_ 2566852863 BATT_prechargeTooFast_9 "0 - Precharge okay (default)
1 - Precharge too fast";
CM_ SG_ 2566852863 BATT_prechargeTimeout_9 "0 - Precharge okay (default)
1 - Precharge timeout";
CM_ SG_ 2566852863 BATT_fetChgShorted_9 "0 - FETs are operational (default)
1 - FET is shorted";
CM_ SG_ 2566852863 BATT_fetChgFailToClose_9 "0 - FETs are operational (default)
1 -  FET fail to close";
CM_ SG_ 2566852863 BATT_packModSelectFault_9 "0 - Battery pack module selection okay (default)
1 - Battery pack module selection fault";
CM_ SG_ 2566852863 BATT_packModConnectFault_9 "0 - Battery pack module connection okay (default)
1 - Battery pack module connection fault";
CM_ SG_ 2566852863 BATT_packModMIA_9 "0 - Battery pack modules not MIA (default)
1 - Battery pack module MIA";
CM_ SG_ 2566852863 BATT_packModImbalance_9 "0 - Battery pack modules balanced (default)
1 - Battery pack module imblance present";
CM_ SG_ 2566852863 BATT_afeFault_9 "0 - BMS AFE okay (default)
1 - BMS AFE fault";
CM_ SG_ 2566852863 BATT_chargerMIA_9 "0 - Charger communications okay (default)
1 - Charger MIA";
CM_ SG_ 2566852863 BATT_chargerError_9 "0 - Charger working as intended (default)
1 - Charger error";
CM_ SG_ 2566852863 BATT_vBrickUnderWar_9 "0 - Brick voltage okay (default)
1 - Brick undervoltage warning";
CM_ SG_ 2566852863 BATT_vBrickUnderSev_9 "0 - Brick voltage okay (default)
1 - Brick undervoltage severe";
CM_ SG_ 2566852863 BATT_vBrickUnderMod_9 "0 - Brick voltage okay (default)
1 - Brick undervoltage moderate";
CM_ SG_ 2566852863 BATT_vBrickOverWar_9 "0 - Brick voltage okay (default)
1 - Brick overvoltage warning";
CM_ SG_ 2566852863 BATT_vBrickOverSev_9 "0 - Brick voltage okay (default)
1 - Brick overvoltage severe";
CM_ SG_ 2566852863 BATT_vBrickOverMod_9 "0 - Brick voltage okay (default)
1 - Brick overvoltage moderate";
CM_ SG_ 2566852863 BATT_vBrickImbalance_9 "0 - Battery brick voltage okay (default)
1 - Battery brick voltage imbalance";
CM_ SG_ 2566852863 BATT_loggerAlmostFull_9 "0 - Logger not almost full (default)
1 - Logger almost full (section >= 80%) ";
CM_ SG_ 2566852863 BATT_tempModuleUnderWar_9 "0 - Battery temperature okay (default)
1 - Battery under temperature warning";
CM_ SG_ 2566852863 BATT_tempModuleUnderSev_9 "0 - Battery temperature okay (default)
1 - Battery under temperature severe";
CM_ SG_ 2566852863 BATT_tempModuleUnderMod_9 "0 - Battery temperature okay (default)
1 - Battery under temperature moderate";
CM_ SG_ 2566852863 BATT_tempModuleOverWar_9 "0 - Battery temperature okay (default)
1 - Battery over temperature warning";
CM_ SG_ 2566852863 BATT_tempModuleOverSev_9 "0 - Battery temperature okay (default)
1 - Battery over temperature severe";
CM_ SG_ 2566852863 BATT_tempModuleOverMod_9 "0 - Battery temperature okay (default)
1 - Battery over temperature moderate";
CM_ SG_ 2566852863 BATT_tempBrickImbalance_9 "0 - Brick temperatures are balanced (default)
1 - Brick temperatures are imbalanced";
CM_ SG_ 2566852863 BATT_taskLockupError_9 "0 - Tasks okay (default)
1 - Task lockup error";
CM_ SG_ 2566852863 BATT_tempBoardOverWar_9 "0 - Ambient temperature okay (default)
1 - Ambient over temperature warning";
CM_ SG_ 2566852863 BATT_tempBoardOverSev_9 "0 - Temperature okay (default)
1 - Ambient over temperature severe";
CM_ SG_ 2566852863 BATT_tempBoardOverMod_9 "0 - Ambient temperature okay (default)
1 - Ambient over temparature moderate";
CM_ SG_ 2566852863 BATT_sensePackVoltError_9 "0 - Sensor okay (default)
1 - Sensor for pack voltage error";
CM_ SG_ 2566852863 BATT_senseLoadVoltError_9 "0 - Sensor okay (default)
1 - Sensor for load voltage error";
CM_ SG_ 2566852863 BATT_loggerFull_9 "0 - Logger not full (default)
1 - Logger full ";
CM_ SG_ 2566852863 BATT_senseCurrentError_9 "0 - Sensor okay (default)
1 - Sensor for current error";
CM_ SG_ 2566852863 BATT_senseBrickTempError_9 "0 - Sensor okay (default)
1 - Brick temperature sensor error";
CM_ SG_ 2566852863 BATT_resPackHigh_9 "0 - Battery pack resistance okay (default)
1 - Battery pack resistance high (High SOH-R)";
CM_ SG_ 2566852863 BATT_ramOverUtilError_9 "0 - RAM okay (default)
1 - RAM over utilization";
CM_ SG_ 2566852863 BATT_powerPackInsufficient_9 "0 - Battery pack power okay (default)
1 - Battery pack power insufficient";
CM_ SG_ 2566852863 BATT_packCellSoftShort_9 "0 - Battery back cells are okay (default)
1 - Battery pack cell soft short";
CM_ SG_ 2566852863 BATT_iOverHardware_9 "0 - Hardware current okay (default)
1 - Overcurrent in hardware";
CM_ SG_ 2566852863 BATT_fetOverTemp_9 "0 - FET temperature okay (default)
1 - Overtemp at FETs";
CM_ SG_ 2566852863 BATT_iOverDischarge_9 "0 - Discharge okay (default)
1 - Overcurrent during discharge";
CM_ SG_ 2566852863 BATT_iOverCharge_9 "0 - Charging okay (default)
1 - Overcurrent during charging";
CM_ SG_ 2566852863 BATT_inverterDriveMIA_9 "0 - Inverter drive present (default)
1 - Inverter drive MIA";
CM_ SG_ 2566852863 BATT_iUnderCharge_9 "0 - Normal charging (default)
1 -  Charging undercurrent (discharging)";
CM_ SG_ 2566852863 BATT_hostMIA_9 "0 - host communication open (default)
1 - host MIA";
CM_ SG_ 2566852863 BATT_fetDsgShorted_9 "0 - FETs are operational (default)
1 - FET is shorted";
CM_ SG_ 2566852863 BATT_fetDsgFailToClose_9 "0 - FETs are operational (default)
1 -  FET fail to close";
CM_ SG_ 2566852863 BATT_capLow_9 "0 - Battery capacity normal (SOH-C) (default)
1 - Low battery capacity (Low SOH-C)";
CM_ SG_ 2566852863 BATT_brickOverDischarge_9 "0 - Battery brick charge is normal (default)
1 - Battery brick is overdischarged";
CM_ SG_ 2566852863 BATT_brickOverCharge_9 "0 - Battery brick charge is normal (default)
1 - Battery brick is overcharged";
CM_ SG_ 2566852863 BATT_bmsProcessorError_9 "0 - No BMS processor failure (default)
1 - BMS processor failure";
CM_ SG_ 2566852863 BATT_bmsMemoryError_9 "0 - No BMS memory error
1 - BMS memory error";
CM_ SG_ 2566852863 BATT_afeError_9 "0 - No BMS AFE error (default)
1 - BMS AFE error";
CM_ BO_ 2566853110 "Message with flags from event matrix";
CM_ SG_ 2566853110 BATT_vBrickImbalanceWarning_0 "0 - Battery brick voltage okay (default)
1 - Battery brick voltage imbalance";
CM_ SG_ 2566853110 BATT_harnessImpedanceFault_0 "Harness Impedance fault
";
CM_ SG_ 2566853110 BATT_packLevelArbitrationFault_0 "0 - Pack Level Arbitration fault clear (default)
1 - Pack Level Arbitration fault";
CM_ SG_ 2566853110 BATT_multiIgnLoFault_0 "0 - Single module has IGN_LO connection (default)
1 - Multimodule have IGN_LO connections";
CM_ SG_ 2566853110 BATT_modThermistorShorted_0 "0 - module thermistor okay (default)
1 - module thermistor shorted";
CM_ SG_ 2566853110 BATT_modThermistorOpenWire_0 "0 - module thermistor okay (default)
1 - module thermistor open wire";
CM_ SG_ 2566853110 BATT_chargeNotNeeded_0 "0 - Local module charge needed (default)
1 - Local module charge not needed";
CM_ SG_ 2566853110 BATT_packModTempImbalance_0 "0 - Battery pack module temperatures okay (default)
1 - Battery pack module temperature imblance present";
CM_ SG_ 2566853110 BATT_packModCurrImbalance_0 "0 - Battery pack module curent okay (default)
1 - Battery pack module current imblance present";
CM_ SG_ 2566853110 BATT_flashBootCRCError_0 "0 - No flash bootloader CRC error (default)
1 - Flash bootloader CRC error";
CM_ SG_ 2566853110 BATT_flashAppCRCError_0 "0 - No flash app CRC error (default)
1 -  Flash App CRC error";
CM_ SG_ 2566853110 BATT_cellOpenWire_0 "0 - Reset reason okay (default)
1 - Abnormal reset reason";
CM_ BO_ 2566853111 "Message with flags from event matrix";
CM_ SG_ 2566853111 BATT_vBrickImbalanceWarning_1 "0 - Battery brick voltage okay (default)
1 - Battery brick voltage imbalance";
CM_ SG_ 2566853111 BATT_harnessImpedanceFault_1 "Harness Impedance fault
";
CM_ SG_ 2566853111 BATT_packLevelArbitrationFault_1 "0 - Pack Level Arbitration fault clear (default)
1 - Pack Level Arbitration fault";
CM_ SG_ 2566853111 BATT_multiIgnLoFault_1 "0 - Single module has IGN_LO connection (default)
1 - Multimodule have IGN_LO connections";
CM_ SG_ 2566853111 BATT_modThermistorShorted_1 "0 - module thermistor okay (default)
1 - module thermistor shorted";
CM_ SG_ 2566853111 BATT_modThermistorOpenWire_1 "0 - module thermistor okay (default)
1 - module thermistor open wire";
CM_ SG_ 2566853111 BATT_chargeNotNeeded_1 "0 - Local module charge needed (default)
1 - Local module charge not needed";
CM_ SG_ 2566853111 BATT_packModTempImbalance_1 "0 - Battery pack module temperatures okay (default)
1 - Battery pack module temperature imblance present";
CM_ SG_ 2566853111 BATT_packModCurrImbalance_1 "0 - Battery pack module curent okay (default)
1 - Battery pack module current imblance present";
CM_ SG_ 2566853111 BATT_flashBootCRCError_1 "0 - No flash bootloader CRC error (default)
1 - Flash bootloader CRC error";
CM_ SG_ 2566853111 BATT_flashAppCRCError_1 "0 - No flash app CRC error (default)
1 -  Flash App CRC error";
CM_ SG_ 2566853111 BATT_cellOpenWire_1 "0 - Reset reason okay (default)
1 - Abnormal reset reason";
CM_ BO_ 2566853112 "Message with flags from event matrix";
CM_ SG_ 2566853112 BATT_vBrickImbalanceWarning_2 "0 - Battery brick voltage okay (default)
1 - Battery brick voltage imbalance";
CM_ SG_ 2566853112 BATT_harnessImpedanceFault_2 "Harness Impedance fault
";
CM_ SG_ 2566853112 BATT_packLevelArbitrationFault_2 "0 - Pack Level Arbitration fault clear (default)
1 - Pack Level Arbitration fault";
CM_ SG_ 2566853112 BATT_multiIgnLoFault_2 "0 - Single module has IGN_LO connection (default)
1 - Multimodule have IGN_LO connections";
CM_ SG_ 2566853112 BATT_modThermistorShorted_2 "0 - module thermistor okay (default)
1 - module thermistor shorted";
CM_ SG_ 2566853112 BATT_modThermistorOpenWire_2 "0 - module thermistor okay (default)
1 - module thermistor open wire";
CM_ SG_ 2566853112 BATT_chargeNotNeeded_2 "0 - Local module charge needed (default)
1 - Local module charge not needed";
CM_ SG_ 2566853112 BATT_packModTempImbalance_2 "0 - Battery pack module temperatures okay (default)
1 - Battery pack module temperature imblance present";
CM_ SG_ 2566853112 BATT_packModCurrImbalance_2 "0 - Battery pack module curent okay (default)
1 - Battery pack module current imblance present";
CM_ SG_ 2566853112 BATT_flashBootCRCError_2 "0 - No flash bootloader CRC error (default)
1 - Flash bootloader CRC error";
CM_ SG_ 2566853112 BATT_flashAppCRCError_2 "0 - No flash app CRC error (default)
1 -  Flash App CRC error";
CM_ SG_ 2566853112 BATT_cellOpenWire_2 "0 - Reset reason okay (default)
1 - Abnormal reset reason";
CM_ BO_ 2566853113 "Message with flags from event matrix";
CM_ SG_ 2566853113 BATT_vBrickImbalanceWarning_3 "0 - Battery brick voltage okay (default)
1 - Battery brick voltage imbalance";
CM_ SG_ 2566853113 BATT_harnessImpedanceFault_3 "Harness Impedance fault
";
CM_ SG_ 2566853113 BATT_packLevelArbitrationFault_3 "0 - Pack Level Arbitration fault clear (default)
1 - Pack Level Arbitration fault";
CM_ SG_ 2566853113 BATT_multiIgnLoFault_3 "0 - Single module has IGN_LO connection (default)
1 - Multimodule have IGN_LO connections";
CM_ SG_ 2566853113 BATT_modThermistorShorted_3 "0 - module thermistor okay (default)
1 - module thermistor shorted";
CM_ SG_ 2566853113 BATT_modThermistorOpenWire_3 "0 - module thermistor okay (default)
1 - module thermistor open wire";
CM_ SG_ 2566853113 BATT_chargeNotNeeded_3 "0 - Local module charge needed (default)
1 - Local module charge not needed";
CM_ SG_ 2566853113 BATT_packModTempImbalance_3 "0 - Battery pack module temperatures okay (default)
1 - Battery pack module temperature imblance present";
CM_ SG_ 2566853113 BATT_packModCurrImbalance_3 "0 - Battery pack module curent okay (default)
1 - Battery pack module current imblance present";
CM_ SG_ 2566853113 BATT_flashBootCRCError_3 "0 - No flash bootloader CRC error (default)
1 - Flash bootloader CRC error";
CM_ SG_ 2566853113 BATT_flashAppCRCError_3 "0 - No flash app CRC error (default)
1 -  Flash App CRC error";
CM_ SG_ 2566853113 BATT_cellOpenWire_3 "0 - Reset reason okay (default)
1 - Abnormal reset reason";
CM_ BO_ 2566853114 "Message with flags from event matrix";
CM_ SG_ 2566853114 BATT_vBrickImbalanceWarning_4 "0 - Battery brick voltage okay (default)
1 - Battery brick voltage imbalance";
CM_ SG_ 2566853114 BATT_harnessImpedanceFault_4 "Harness Impedance fault
";
CM_ SG_ 2566853114 BATT_packLevelArbitrationFault_4 "0 - Pack Level Arbitration fault clear (default)
1 - Pack Level Arbitration fault";
CM_ SG_ 2566853114 BATT_multiIgnLoFault_4 "0 - Single module has IGN_LO connection (default)
1 - Multimodule have IGN_LO connections";
CM_ SG_ 2566853114 BATT_modThermistorShorted_4 "0 - module thermistor okay (default)
1 - module thermistor shorted";
CM_ SG_ 2566853114 BATT_modThermistorOpenWire_4 "0 - module thermistor okay (default)
1 - module thermistor open wire";
CM_ SG_ 2566853114 BATT_chargeNotNeeded_4 "0 - Local module charge needed (default)
1 - Local module charge not needed";
CM_ SG_ 2566853114 BATT_packModTempImbalance_4 "0 - Battery pack module temperatures okay (default)
1 - Battery pack module temperature imblance present";
CM_ SG_ 2566853114 BATT_packModCurrImbalance_4 "0 - Battery pack module curent okay (default)
1 - Battery pack module current imblance present";
CM_ SG_ 2566853114 BATT_flashBootCRCError_4 "0 - No flash bootloader CRC error (default)
1 - Flash bootloader CRC error";
CM_ SG_ 2566853114 BATT_flashAppCRCError_4 "0 - No flash app CRC error (default)
1 -  Flash App CRC error";
CM_ SG_ 2566853114 BATT_cellOpenWire_4 "0 - Reset reason okay (default)
1 - Abnormal reset reason";
CM_ BO_ 2566853115 "Message with flags from event matrix";
CM_ SG_ 2566853115 BATT_vBrickImbalanceWarning_5 "0 - Battery brick voltage okay (default)
1 - Battery brick voltage imbalance";
CM_ SG_ 2566853115 BATT_harnessImpedanceFault_5 "Harness Impedance fault
";
CM_ SG_ 2566853115 BATT_packLevelArbitrationFault_5 "0 - Pack Level Arbitration fault clear (default)
1 - Pack Level Arbitration fault";
CM_ SG_ 2566853115 BATT_multiIgnLoFault_5 "0 - Single module has IGN_LO connection (default)
1 - Multimodule have IGN_LO connections";
CM_ SG_ 2566853115 BATT_modThermistorShorted_5 "0 - module thermistor okay (default)
1 - module thermistor shorted";
CM_ SG_ 2566853115 BATT_modThermistorOpenWire_5 "0 - module thermistor okay (default)
1 - module thermistor open wire";
CM_ SG_ 2566853115 BATT_chargeNotNeeded_5 "0 - Local module charge needed (default)
1 - Local module charge not needed";
CM_ SG_ 2566853115 BATT_packModTempImbalance_5 "0 - Battery pack module temperatures okay (default)
1 - Battery pack module temperature imblance present";
CM_ SG_ 2566853115 BATT_packModCurrImbalance_5 "0 - Battery pack module curent okay (default)
1 - Battery pack module current imblance present";
CM_ SG_ 2566853115 BATT_flashBootCRCError_5 "0 - No flash bootloader CRC error (default)
1 - Flash bootloader CRC error";
CM_ SG_ 2566853115 BATT_flashAppCRCError_5 "0 - No flash app CRC error (default)
1 -  Flash App CRC error";
CM_ SG_ 2566853115 BATT_cellOpenWire_5 "0 - Reset reason okay (default)
1 - Abnormal reset reason";
CM_ BO_ 2566853116 "Message with flags from event matrix";
CM_ SG_ 2566853116 BATT_vBrickImbalanceWarning_6 "0 - Battery brick voltage okay (default)
1 - Battery brick voltage imbalance";
CM_ SG_ 2566853116 BATT_harnessImpedanceFault_6 "Harness Impedance fault
";
CM_ SG_ 2566853116 BATT_packLevelArbitrationFault_6 "0 - Pack Level Arbitration fault clear (default)
1 - Pack Level Arbitration fault";
CM_ SG_ 2566853116 BATT_multiIgnLoFault_6 "0 - Single module has IGN_LO connection (default)
1 - Multimodule have IGN_LO connections";
CM_ SG_ 2566853116 BATT_modThermistorShorted_6 "0 - module thermistor okay (default)
1 - module thermistor shorted";
CM_ SG_ 2566853116 BATT_modThermistorOpenWire_6 "0 - module thermistor okay (default)
1 - module thermistor open wire";
CM_ SG_ 2566853116 BATT_chargeNotNeeded_6 "0 - Local module charge needed (default)
1 - Local module charge not needed";
CM_ SG_ 2566853116 BATT_packModTempImbalance_6 "0 - Battery pack module temperatures okay (default)
1 - Battery pack module temperature imblance present";
CM_ SG_ 2566853116 BATT_packModCurrImbalance_6 "0 - Battery pack module curent okay (default)
1 - Battery pack module current imblance present";
CM_ SG_ 2566853116 BATT_flashBootCRCError_6 "0 - No flash bootloader CRC error (default)
1 - Flash bootloader CRC error";
CM_ SG_ 2566853116 BATT_flashAppCRCError_6 "0 - No flash app CRC error (default)
1 -  Flash App CRC error";
CM_ SG_ 2566853116 BATT_cellOpenWire_6 "0 - Reset reason okay (default)
1 - Abnormal reset reason";
CM_ BO_ 2566853117 "Message with flags from event matrix";
CM_ SG_ 2566853117 BATT_vBrickImbalanceWarning_7 "0 - Battery brick voltage okay (default)
1 - Battery brick voltage imbalance";
CM_ SG_ 2566853117 BATT_harnessImpedanceFault_7 "Harness Impedance fault
";
CM_ SG_ 2566853117 BATT_packLevelArbitrationFault_7 "0 - Pack Level Arbitration fault clear (default)
1 - Pack Level Arbitration fault";
CM_ SG_ 2566853117 BATT_multiIgnLoFault_7 "0 - Single module has IGN_LO connection (default)
1 - Multimodule have IGN_LO connections";
CM_ SG_ 2566853117 BATT_modThermistorShorted_7 "0 - module thermistor okay (default)
1 - module thermistor shorted";
CM_ SG_ 2566853117 BATT_modThermistorOpenWire_7 "0 - module thermistor okay (default)
1 - module thermistor open wire";
CM_ SG_ 2566853117 BATT_chargeNotNeeded_7 "0 - Local module charge needed (default)
1 - Local module charge not needed";
CM_ SG_ 2566853117 BATT_packModTempImbalance_7 "0 - Battery pack module temperatures okay (default)
1 - Battery pack module temperature imblance present";
CM_ SG_ 2566853117 BATT_packModCurrImbalance_7 "0 - Battery pack module curent okay (default)
1 - Battery pack module current imblance present";
CM_ SG_ 2566853117 BATT_flashBootCRCError_7 "0 - No flash bootloader CRC error (default)
1 - Flash bootloader CRC error";
CM_ SG_ 2566853117 BATT_flashAppCRCError_7 "0 - No flash app CRC error (default)
1 -  Flash App CRC error";
CM_ SG_ 2566853117 BATT_cellOpenWire_7 "0 - Reset reason okay (default)
1 - Abnormal reset reason";
CM_ BO_ 2566853118 "Message with flags from event matrix";
CM_ SG_ 2566853118 BATT_vBrickImbalanceWarning_8 "0 - Battery brick voltage okay (default)
1 - Battery brick voltage imbalance";
CM_ SG_ 2566853118 BATT_harnessImpedanceFault_8 "Harness Impedance fault
";
CM_ SG_ 2566853118 BATT_packLevelArbitrationFault_8 "0 - Pack Level Arbitration fault clear (default)
1 - Pack Level Arbitration fault";
CM_ SG_ 2566853118 BATT_multiIgnLoFault_8 "0 - Single module has IGN_LO connection (default)
1 - Multimodule have IGN_LO connections";
CM_ SG_ 2566853118 BATT_modThermistorShorted_8 "0 - module thermistor okay (default)
1 - module thermistor shorted";
CM_ SG_ 2566853118 BATT_modThermistorOpenWire_8 "0 - module thermistor okay (default)
1 - module thermistor open wire";
CM_ SG_ 2566853118 BATT_chargeNotNeeded_8 "0 - Local module charge needed (default)
1 - Local module charge not needed";
CM_ SG_ 2566853118 BATT_packModTempImbalance_8 "0 - Battery pack module temperatures okay (default)
1 - Battery pack module temperature imblance present";
CM_ SG_ 2566853118 BATT_packModCurrImbalance_8 "0 - Battery pack module curent okay (default)
1 - Battery pack module current imblance present";
CM_ SG_ 2566853118 BATT_flashBootCRCError_8 "0 - No flash bootloader CRC error (default)
1 - Flash bootloader CRC error";
CM_ SG_ 2566853118 BATT_flashAppCRCError_8 "0 - No flash app CRC error (default)
1 -  Flash App CRC error";
CM_ SG_ 2566853118 BATT_cellOpenWire_8 "0 - Reset reason okay (default)
1 - Abnormal reset reason";
CM_ BO_ 2566853119 "Message with flags from event matrix";
CM_ SG_ 2566853119 BATT_vBrickImbalanceWarning_9 "0 - Battery brick voltage okay (default)
1 - Battery brick voltage imbalance";
CM_ SG_ 2566853119 BATT_harnessImpedanceFault_9 "Harness Impedance fault
";
CM_ SG_ 2566853119 BATT_packLevelArbitrationFault_9 "0 - Pack Level Arbitration fault clear (default)
1 - Pack Level Arbitration fault";
CM_ SG_ 2566853119 BATT_multiIgnLoFault_9 "0 - Single module has IGN_LO connection (default)
1 - Multimodule have IGN_LO connections";
CM_ SG_ 2566853119 BATT_modThermistorShorted_9 "0 - module thermistor okay (default)
1 - module thermistor shorted";
CM_ SG_ 2566853119 BATT_modThermistorOpenWire_9 "0 - module thermistor okay (default)
1 - module thermistor open wire";
CM_ SG_ 2566853119 BATT_chargeNotNeeded_9 "0 - Local module charge needed (default)
1 - Local module charge not needed";
CM_ SG_ 2566853119 BATT_packModTempImbalance_9 "0 - Battery pack module temperatures okay (default)
1 - Battery pack module temperature imblance present";
CM_ SG_ 2566853119 BATT_packModCurrImbalance_9 "0 - Battery pack module curent okay (default)
1 - Battery pack module current imblance present";
CM_ SG_ 2566853119 BATT_flashBootCRCError_9 "0 - No flash bootloader CRC error (default)
1 - Flash bootloader CRC error";
CM_ SG_ 2566853119 BATT_flashAppCRCError_9 "0 - No flash app CRC error (default)
1 -  Flash App CRC error";
CM_ SG_ 2566853119 BATT_cellOpenWire_9 "0 - Reset reason okay (default)
1 - Abnormal reset reason";
CM_ BO_ 2566853877 "BATT battery request";
CM_ SG_ 2566853877 BATT_muteCAN "0 if CAN mute is not requested
1 if CAN mute is requested
";
CM_ SG_ 2566853877 BATT_isPushBtn_Requested "0 if PUSH_BTN pin is NOT pressed
1 if PUSH_BTN pin is pressed for 3 secs and released";
CM_ SG_ 2566853877 BATT_isIgnLo_Requested "0 if IGN_LO pin is NOT triggered
1 if IGN_LO pin is triggered ";
CM_ SG_ 2566853877 BATT_modReqCntr "BATT_modRequest msg counter";
CM_ SG_ 2566853877 BATT_nodeIdSerialNumber "Unique serial number";
CM_ SG_ 2566853877 BATT_startNodeId "Start node ID claim flag from BATT";
CM_ SG_ 2566853877 BATT_stateRequest "State to be requested from battery module";
CM_ BO_ 2566854390 "Capacity of bricks 5-8";
CM_ SG_ 2566854390 BATT_capBrick08_0 "Capacity of brick 8";
CM_ SG_ 2566854390 BATT_capBrick07_0 "Capacity of brick 7";
CM_ SG_ 2566854390 BATT_capBrick06_0 "Capacity of brick 6";
CM_ SG_ 2566854390 BATT_capBrick05_0 "Capacity of brick 5";
CM_ BO_ 2566854391 "Capacity of bricks 5-8";
CM_ SG_ 2566854391 BATT_capBrick08_1 "Capacity of brick 8";
CM_ SG_ 2566854391 BATT_capBrick07_1 "Capacity of brick 7";
CM_ SG_ 2566854391 BATT_capBrick06_1 "Capacity of brick 6";
CM_ SG_ 2566854391 BATT_capBrick05_1 "Capacity of brick 5";
CM_ BO_ 2566854392 "Capacity of bricks 5-8";
CM_ SG_ 2566854392 BATT_capBrick08_2 "Capacity of brick 8";
CM_ SG_ 2566854392 BATT_capBrick07_2 "Capacity of brick 7";
CM_ SG_ 2566854392 BATT_capBrick06_2 "Capacity of brick 6";
CM_ SG_ 2566854392 BATT_capBrick05_2 "Capacity of brick 5";
CM_ BO_ 2566854393 "Capacity of bricks 5-8";
CM_ SG_ 2566854393 BATT_capBrick08_3 "Capacity of brick 8";
CM_ SG_ 2566854393 BATT_capBrick07_3 "Capacity of brick 7";
CM_ SG_ 2566854393 BATT_capBrick06_3 "Capacity of brick 6";
CM_ SG_ 2566854393 BATT_capBrick05_3 "Capacity of brick 5";
CM_ BO_ 2566854394 "Capacity of bricks 5-8";
CM_ SG_ 2566854394 BATT_capBrick08_4 "Capacity of brick 8";
CM_ SG_ 2566854394 BATT_capBrick07_4 "Capacity of brick 7";
CM_ SG_ 2566854394 BATT_capBrick06_4 "Capacity of brick 6";
CM_ SG_ 2566854394 BATT_capBrick05_4 "Capacity of brick 5";
CM_ BO_ 2566854395 "Capacity of bricks 5-8";
CM_ SG_ 2566854395 BATT_capBrick08_5 "Capacity of brick 8";
CM_ SG_ 2566854395 BATT_capBrick07_5 "Capacity of brick 7";
CM_ SG_ 2566854395 BATT_capBrick06_5 "Capacity of brick 6";
CM_ SG_ 2566854395 BATT_capBrick05_5 "Capacity of brick 5";
CM_ BO_ 2566854396 "Capacity of bricks 5-8";
CM_ SG_ 2566854396 BATT_capBrick08_6 "Capacity of brick 8";
CM_ SG_ 2566854396 BATT_capBrick07_6 "Capacity of brick 7";
CM_ SG_ 2566854396 BATT_capBrick06_6 "Capacity of brick 6";
CM_ SG_ 2566854396 BATT_capBrick05_6 "Capacity of brick 5";
CM_ BO_ 2566854397 "Capacity of bricks 5-8";
CM_ SG_ 2566854397 BATT_capBrick08_7 "Capacity of brick 8";
CM_ SG_ 2566854397 BATT_capBrick07_7 "Capacity of brick 7";
CM_ SG_ 2566854397 BATT_capBrick06_7 "Capacity of brick 6";
CM_ SG_ 2566854397 BATT_capBrick05_7 "Capacity of brick 5";
CM_ BO_ 2566854398 "Capacity of bricks 5-8";
CM_ SG_ 2566854398 BATT_capBrick08_8 "Capacity of brick 8";
CM_ SG_ 2566854398 BATT_capBrick07_8 "Capacity of brick 7";
CM_ SG_ 2566854398 BATT_capBrick06_8 "Capacity of brick 6";
CM_ SG_ 2566854398 BATT_capBrick05_8 "Capacity of brick 5";
CM_ BO_ 2566854399 "Capacity of bricks 5-8";
CM_ SG_ 2566854399 BATT_capBrick08_9 "Capacity of brick 8";
CM_ SG_ 2566854399 BATT_capBrick07_9 "Capacity of brick 7";
CM_ SG_ 2566854399 BATT_capBrick06_9 "Capacity of brick 6";
CM_ SG_ 2566854399 BATT_capBrick05_9 "Capacity of brick 5";
CM_ BO_ 2566854646 "Voltages of bricks 5-8";
CM_ SG_ 2566854646 BATT_vBrick06_0 "Voltage of brick 6";
CM_ SG_ 2566854646 BATT_vBrick07_0 "Voltage of brick 7";
CM_ SG_ 2566854646 BATT_vBrick05_0 "Voltage of brick 5";
CM_ SG_ 2566854646 BATT_vBrick08_0 "Voltage of brick 8";
CM_ BO_ 2566854647 "Voltages of bricks 5-8";
CM_ SG_ 2566854647 BATT_vBrick06_1 "Voltage of brick 6";
CM_ SG_ 2566854647 BATT_vBrick07_1 "Voltage of brick 7";
CM_ SG_ 2566854647 BATT_vBrick05_1 "Voltage of brick 5";
CM_ SG_ 2566854647 BATT_vBrick08_1 "Voltage of brick 8";
CM_ BO_ 2566854648 "Voltages of bricks 5-8";
CM_ SG_ 2566854648 BATT_vBrick06_2 "Voltage of brick 6";
CM_ SG_ 2566854648 BATT_vBrick07_2 "Voltage of brick 7";
CM_ SG_ 2566854648 BATT_vBrick05_2 "Voltage of brick 5";
CM_ SG_ 2566854648 BATT_vBrick08_2 "Voltage of brick 8";
CM_ BO_ 2566854649 "Voltages of bricks 5-8";
CM_ SG_ 2566854649 BATT_vBrick06_3 "Voltage of brick 6";
CM_ SG_ 2566854649 BATT_vBrick07_3 "Voltage of brick 7";
CM_ SG_ 2566854649 BATT_vBrick05_3 "Voltage of brick 5";
CM_ SG_ 2566854649 BATT_vBrick08_3 "Voltage of brick 8";
CM_ BO_ 2566854650 "Voltages of bricks 5-8";
CM_ SG_ 2566854650 BATT_vBrick06_4 "Voltage of brick 6";
CM_ SG_ 2566854650 BATT_vBrick07_4 "Voltage of brick 7";
CM_ SG_ 2566854650 BATT_vBrick05_4 "Voltage of brick 5";
CM_ SG_ 2566854650 BATT_vBrick08_4 "Voltage of brick 8";
CM_ BO_ 2566854651 "Voltages of bricks 5-8";
CM_ SG_ 2566854651 BATT_vBrick06_5 "Voltage of brick 6";
CM_ SG_ 2566854651 BATT_vBrick07_5 "Voltage of brick 7";
CM_ SG_ 2566854651 BATT_vBrick05_5 "Voltage of brick 5";
CM_ SG_ 2566854651 BATT_vBrick08_5 "Voltage of brick 8";
CM_ BO_ 2566854652 "Voltages of bricks 5-8";
CM_ SG_ 2566854652 BATT_vBrick06_6 "Voltage of brick 6";
CM_ SG_ 2566854652 BATT_vBrick07_6 "Voltage of brick 7";
CM_ SG_ 2566854652 BATT_vBrick05_6 "Voltage of brick 5";
CM_ SG_ 2566854652 BATT_vBrick08_6 "Voltage of brick 8";
CM_ BO_ 2566854653 "Voltages of bricks 5-8";
CM_ SG_ 2566854653 BATT_vBrick06_7 "Voltage of brick 6";
CM_ SG_ 2566854653 BATT_vBrick07_7 "Voltage of brick 7";
CM_ SG_ 2566854653 BATT_vBrick05_7 "Voltage of brick 5";
CM_ SG_ 2566854653 BATT_vBrick08_7 "Voltage of brick 8";
CM_ BO_ 2566854654 "Voltages of bricks 5-8";
CM_ SG_ 2566854654 BATT_vBrick06_8 "Voltage of brick 6";
CM_ SG_ 2566854654 BATT_vBrick07_8 "Voltage of brick 7";
CM_ SG_ 2566854654 BATT_vBrick05_8 "Voltage of brick 5";
CM_ SG_ 2566854654 BATT_vBrick08_8 "Voltage of brick 8";
CM_ BO_ 2566854655 "Voltages of bricks 5-8";
CM_ SG_ 2566854655 BATT_vBrick06_9 "Voltage of brick 6";
CM_ SG_ 2566854655 BATT_vBrick07_9 "Voltage of brick 7";
CM_ SG_ 2566854655 BATT_vBrick05_9 "Voltage of brick 5";
CM_ SG_ 2566854655 BATT_vBrick08_9 "Voltage of brick 8";
CM_ SG_ 2566855158 BATT_tPreChg "Temperature of current shunt";
CM_ SG_ 2566855158 BATT_tShunt "Temperature of current shunt";
CM_ SG_ 2566855158 BATT_tFET "Temperature of FETs";
CM_ BO_ 2566858486 "Capacity of bricks 9-12";
CM_ SG_ 2566858486 BATT_capBrick12_0 "Capacity of brick 12";
CM_ SG_ 2566858486 BATT_capBrick11_0 "Capacity of brick 11";
CM_ SG_ 2566858486 BATT_capBrick09_0 "Capacity of brick 9";
CM_ SG_ 2566858486 BATT_capBrick10_0 "Capacity of brick 10";
CM_ BO_ 2566858487 "Capacity of bricks 9-12";
CM_ SG_ 2566858487 BATT_capBrick12_1 "Capacity of brick 12";
CM_ SG_ 2566858487 BATT_capBrick11_1 "Capacity of brick 11";
CM_ SG_ 2566858487 BATT_capBrick09_1 "Capacity of brick 9";
CM_ SG_ 2566858487 BATT_capBrick10_1 "Capacity of brick 10";
CM_ BO_ 2566858488 "Capacity of bricks 9-12";
CM_ SG_ 2566858488 BATT_capBrick12_2 "Capacity of brick 12";
CM_ SG_ 2566858488 BATT_capBrick11_2 "Capacity of brick 11";
CM_ SG_ 2566858488 BATT_capBrick09_2 "Capacity of brick 9";
CM_ SG_ 2566858488 BATT_capBrick10_2 "Capacity of brick 10";
CM_ BO_ 2566858489 "Capacity of bricks 9-12";
CM_ SG_ 2566858489 BATT_capBrick12_3 "Capacity of brick 12";
CM_ SG_ 2566858489 BATT_capBrick11_3 "Capacity of brick 11";
CM_ SG_ 2566858489 BATT_capBrick09_3 "Capacity of brick 9";
CM_ SG_ 2566858489 BATT_capBrick10_3 "Capacity of brick 10";
CM_ BO_ 2566858490 "Capacity of bricks 9-12";
CM_ SG_ 2566858490 BATT_capBrick12_4 "Capacity of brick 12";
CM_ SG_ 2566858490 BATT_capBrick11_4 "Capacity of brick 11";
CM_ SG_ 2566858490 BATT_capBrick09_4 "Capacity of brick 9";
CM_ SG_ 2566858490 BATT_capBrick10_4 "Capacity of brick 10";
CM_ BO_ 2566858491 "Capacity of bricks 9-12";
CM_ SG_ 2566858491 BATT_capBrick12_5 "Capacity of brick 12";
CM_ SG_ 2566858491 BATT_capBrick11_5 "Capacity of brick 11";
CM_ SG_ 2566858491 BATT_capBrick09_5 "Capacity of brick 9";
CM_ SG_ 2566858491 BATT_capBrick10_5 "Capacity of brick 10";
CM_ BO_ 2566858492 "Capacity of bricks 9-12";
CM_ SG_ 2566858492 BATT_capBrick12_6 "Capacity of brick 12";
CM_ SG_ 2566858492 BATT_capBrick11_6 "Capacity of brick 11";
CM_ SG_ 2566858492 BATT_capBrick09_6 "Capacity of brick 9";
CM_ SG_ 2566858492 BATT_capBrick10_6 "Capacity of brick 10";
CM_ BO_ 2566858493 "Capacity of bricks 9-12";
CM_ SG_ 2566858493 BATT_capBrick12_7 "Capacity of brick 12";
CM_ SG_ 2566858493 BATT_capBrick11_7 "Capacity of brick 11";
CM_ SG_ 2566858493 BATT_capBrick09_7 "Capacity of brick 9";
CM_ SG_ 2566858493 BATT_capBrick10_7 "Capacity of brick 10";
CM_ BO_ 2566858494 "Capacity of bricks 9-12";
CM_ SG_ 2566858494 BATT_capBrick12_8 "Capacity of brick 12";
CM_ SG_ 2566858494 BATT_capBrick11_8 "Capacity of brick 11";
CM_ SG_ 2566858494 BATT_capBrick09_8 "Capacity of brick 9";
CM_ SG_ 2566858494 BATT_capBrick10_8 "Capacity of brick 10";
CM_ BO_ 2566858495 "Capacity of bricks 9-12";
CM_ SG_ 2566858495 BATT_capBrick12_9 "Capacity of brick 12";
CM_ SG_ 2566858495 BATT_capBrick11_9 "Capacity of brick 11";
CM_ SG_ 2566858495 BATT_capBrick09_9 "Capacity of brick 9";
CM_ SG_ 2566858495 BATT_capBrick10_9 "Capacity of brick 10";
CM_ BO_ 2566858742 "Voltages of bricks 9-12";
CM_ SG_ 2566858742 BATT_vBrick12_0 "Voltage of brick 12";
CM_ SG_ 2566858742 BATT_vBrick11_0 "Voltage of brick 11";
CM_ SG_ 2566858742 BATT_vBrick10_0 "Voltage of brick 10";
CM_ SG_ 2566858742 BATT_vBrick09_0 "Voltage of brick 9";
CM_ BO_ 2566858743 "Voltages of bricks 9-12";
CM_ SG_ 2566858743 BATT_vBrick12_1 "Voltage of brick 12";
CM_ SG_ 2566858743 BATT_vBrick11_1 "Voltage of brick 11";
CM_ SG_ 2566858743 BATT_vBrick10_1 "Voltage of brick 10";
CM_ SG_ 2566858743 BATT_vBrick09_1 "Voltage of brick 9";
CM_ BO_ 2566858744 "Voltages of bricks 9-12";
CM_ SG_ 2566858744 BATT_vBrick12_2 "Voltage of brick 12";
CM_ SG_ 2566858744 BATT_vBrick11_2 "Voltage of brick 11";
CM_ SG_ 2566858744 BATT_vBrick10_2 "Voltage of brick 10";
CM_ SG_ 2566858744 BATT_vBrick09_2 "Voltage of brick 9";
CM_ BO_ 2566858745 "Voltages of bricks 9-12";
CM_ SG_ 2566858745 BATT_vBrick12_3 "Voltage of brick 12";
CM_ SG_ 2566858745 BATT_vBrick11_3 "Voltage of brick 11";
CM_ SG_ 2566858745 BATT_vBrick10_3 "Voltage of brick 10";
CM_ SG_ 2566858745 BATT_vBrick09_3 "Voltage of brick 9";
CM_ BO_ 2566858746 "Voltages of bricks 9-12";
CM_ SG_ 2566858746 BATT_vBrick12_4 "Voltage of brick 12";
CM_ SG_ 2566858746 BATT_vBrick11_4 "Voltage of brick 11";
CM_ SG_ 2566858746 BATT_vBrick10_4 "Voltage of brick 10";
CM_ SG_ 2566858746 BATT_vBrick09_4 "Voltage of brick 9";
CM_ BO_ 2566858747 "Voltages of bricks 9-12";
CM_ SG_ 2566858747 BATT_vBrick12_5 "Voltage of brick 12";
CM_ SG_ 2566858747 BATT_vBrick11_5 "Voltage of brick 11";
CM_ SG_ 2566858747 BATT_vBrick10_5 "Voltage of brick 10";
CM_ SG_ 2566858747 BATT_vBrick09_5 "Voltage of brick 9";
CM_ BO_ 2566858748 "Voltages of bricks 9-12";
CM_ SG_ 2566858748 BATT_vBrick12_6 "Voltage of brick 12";
CM_ SG_ 2566858748 BATT_vBrick11_6 "Voltage of brick 11";
CM_ SG_ 2566858748 BATT_vBrick10_6 "Voltage of brick 10";
CM_ SG_ 2566858748 BATT_vBrick09_6 "Voltage of brick 9";
CM_ BO_ 2566858749 "Voltages of bricks 9-12";
CM_ SG_ 2566858749 BATT_vBrick12_7 "Voltage of brick 12";
CM_ SG_ 2566858749 BATT_vBrick11_7 "Voltage of brick 11";
CM_ SG_ 2566858749 BATT_vBrick10_7 "Voltage of brick 10";
CM_ SG_ 2566858749 BATT_vBrick09_7 "Voltage of brick 9";
CM_ BO_ 2566858750 "Voltages of bricks 9-12";
CM_ SG_ 2566858750 BATT_vBrick12_8 "Voltage of brick 12";
CM_ SG_ 2566858750 BATT_vBrick11_8 "Voltage of brick 11";
CM_ SG_ 2566858750 BATT_vBrick10_8 "Voltage of brick 10";
CM_ SG_ 2566858750 BATT_vBrick09_8 "Voltage of brick 9";
CM_ BO_ 2566858751 "Voltages of bricks 9-12";
CM_ SG_ 2566858751 BATT_vBrick12_9 "Voltage of brick 12";
CM_ SG_ 2566858751 BATT_vBrick11_9 "Voltage of brick 11";
CM_ SG_ 2566858751 BATT_vBrick10_9 "Voltage of brick 10";
CM_ SG_ 2566858751 BATT_vBrick09_9 "Voltage of brick 9";
CM_ BO_ 2566862326 "State of charge of bricks 13-14";
CM_ SG_ 2566862326 BATT_socState_0 "SOC State";
CM_ SG_ 2566862326 BATT_socLoLimit_0 "SOC Low Limit Mask";
CM_ SG_ 2566862326 BATT_socHiLimit_0 "SOC Low Limit Mask";
CM_ SG_ 2566862326 BATT_socBrick14_0 "State of charge of brick 14";
CM_ SG_ 2566862326 BATT_socBrick13_0 "State of charge of brick 13";
CM_ BO_ 2566862327 "State of charge of bricks 13-14";
CM_ SG_ 2566862327 BATT_socState_1 "SOC State";
CM_ SG_ 2566862327 BATT_socLoLimit_1 "SOC Low Limit Mask";
CM_ SG_ 2566862327 BATT_socHiLimit_1 "SOC Low Limit Mask";
CM_ SG_ 2566862327 BATT_socBrick14_1 "State of charge of brick 14";
CM_ SG_ 2566862327 BATT_socBrick13_1 "State of charge of brick 13";
CM_ BO_ 2566862328 "State of charge of bricks 13-14";
CM_ SG_ 2566862328 BATT_socState_2 "SOC State";
CM_ SG_ 2566862328 BATT_socLoLimit_2 "SOC Low Limit Mask";
CM_ SG_ 2566862328 BATT_socHiLimit_2 "SOC Low Limit Mask";
CM_ SG_ 2566862328 BATT_socBrick14_2 "State of charge of brick 14";
CM_ SG_ 2566862328 BATT_socBrick13_2 "State of charge of brick 13";
CM_ BO_ 2566862329 "State of charge of bricks 13-14";
CM_ SG_ 2566862329 BATT_socState_3 "SOC State";
CM_ SG_ 2566862329 BATT_socLoLimit_3 "SOC Low Limit Mask";
CM_ SG_ 2566862329 BATT_socHiLimit_3 "SOC Low Limit Mask";
CM_ SG_ 2566862329 BATT_socBrick14_3 "State of charge of brick 14";
CM_ SG_ 2566862329 BATT_socBrick13_3 "State of charge of brick 13";
CM_ BO_ 2566862330 "State of charge of bricks 13-14";
CM_ SG_ 2566862330 BATT_socState_4 "SOC State";
CM_ SG_ 2566862330 BATT_socLoLimit_4 "SOC Low Limit Mask";
CM_ SG_ 2566862330 BATT_socHiLimit_4 "SOC Low Limit Mask";
CM_ SG_ 2566862330 BATT_socBrick14_4 "State of charge of brick 14";
CM_ SG_ 2566862330 BATT_socBrick13_4 "State of charge of brick 13";
CM_ BO_ 2566862331 "State of charge of bricks 13-14";
CM_ SG_ 2566862331 BATT_socState_5 "SOC State";
CM_ SG_ 2566862331 BATT_socLoLimit_5 "SOC Low Limit Mask";
CM_ SG_ 2566862331 BATT_socHiLimit_5 "SOC Low Limit Mask";
CM_ SG_ 2566862331 BATT_socBrick14_5 "State of charge of brick 14";
CM_ SG_ 2566862331 BATT_socBrick13_5 "State of charge of brick 13";
CM_ BO_ 2566862332 "State of charge of bricks 13-14";
CM_ SG_ 2566862332 BATT_socState_6 "SOC State";
CM_ SG_ 2566862332 BATT_socLoLimit_6 "SOC Low Limit Mask";
CM_ SG_ 2566862332 BATT_socHiLimit_6 "SOC Low Limit Mask";
CM_ SG_ 2566862332 BATT_socBrick14_6 "State of charge of brick 14";
CM_ SG_ 2566862332 BATT_socBrick13_6 "State of charge of brick 13";
CM_ BO_ 2566862333 "State of charge of bricks 13-14";
CM_ SG_ 2566862333 BATT_socState_7 "SOC State";
CM_ SG_ 2566862333 BATT_socLoLimit_7 "SOC Low Limit Mask";
CM_ SG_ 2566862333 BATT_socHiLimit_7 "SOC Low Limit Mask";
CM_ SG_ 2566862333 BATT_socBrick14_7 "State of charge of brick 14";
CM_ SG_ 2566862333 BATT_socBrick13_7 "State of charge of brick 13";
CM_ BO_ 2566862334 "State of charge of bricks 13-14";
CM_ SG_ 2566862334 BATT_socState_8 "SOC State";
CM_ SG_ 2566862334 BATT_socLoLimit_8 "SOC Low Limit Mask";
CM_ SG_ 2566862334 BATT_socHiLimit_8 "SOC Low Limit Mask";
CM_ SG_ 2566862334 BATT_socBrick14_8 "State of charge of brick 14";
CM_ SG_ 2566862334 BATT_socBrick13_8 "State of charge of brick 13";
CM_ BO_ 2566862335 "State of charge of bricks 13-14";
CM_ SG_ 2566862335 BATT_socState_9 "SOC State";
CM_ SG_ 2566862335 BATT_socLoLimit_9 "SOC Low Limit Mask";
CM_ SG_ 2566862335 BATT_socHiLimit_9 "SOC Low Limit Mask";
CM_ SG_ 2566862335 BATT_socBrick14_9 "State of charge of brick 14";
CM_ SG_ 2566862335 BATT_socBrick13_9 "State of charge of brick 13";
CM_ BO_ 2566862582 "Capacity of bricks 13-14";
CM_ SG_ 2566862582 BATT_sohcUpdated_0 "SOHC Updated Mask";
CM_ SG_ 2566862582 BATT_sohcPrimed_0 "SOHC Primed Mask";
CM_ SG_ 2566862582 BATT_capBrick14_0 "Capacity of brick 14";
CM_ SG_ 2566862582 BATT_capBrick13_0 "Capacity of brick 13";
CM_ BO_ 2566862583 "Capacity of bricks 13-14";
CM_ SG_ 2566862583 BATT_sohcUpdated_1 "SOHC Updated Mask";
CM_ SG_ 2566862583 BATT_sohcPrimed_1 "SOHC Primed Mask";
CM_ SG_ 2566862583 BATT_capBrick14_1 "Capacity of brick 14";
CM_ SG_ 2566862583 BATT_capBrick13_1 "Capacity of brick 13";
CM_ BO_ 2566862584 "Capacity of bricks 13-14";
CM_ SG_ 2566862584 BATT_sohcUpdated_2 "SOHC Updated Mask";
CM_ SG_ 2566862584 BATT_sohcPrimed_2 "SOHC Primed Mask";
CM_ SG_ 2566862584 BATT_capBrick14_2 "Capacity of brick 14";
CM_ SG_ 2566862584 BATT_capBrick13_2 "Capacity of brick 13";
CM_ BO_ 2566862585 "Capacity of bricks 13-14";
CM_ SG_ 2566862585 BATT_sohcUpdated_3 "SOHC Updated Mask";
CM_ SG_ 2566862585 BATT_sohcPrimed_3 "SOHC Primed Mask";
CM_ SG_ 2566862585 BATT_capBrick14_3 "Capacity of brick 14";
CM_ SG_ 2566862585 BATT_capBrick13_3 "Capacity of brick 13";
CM_ BO_ 2566862586 "Capacity of bricks 13-14";
CM_ SG_ 2566862586 BATT_sohcUpdated_4 "SOHC Updated Mask";
CM_ SG_ 2566862586 BATT_sohcPrimed_4 "SOHC Primed Mask";
CM_ SG_ 2566862586 BATT_capBrick14_4 "Capacity of brick 14";
CM_ SG_ 2566862586 BATT_capBrick13_4 "Capacity of brick 13";
CM_ BO_ 2566862587 "Capacity of bricks 13-14";
CM_ SG_ 2566862587 BATT_sohcUpdated_5 "SOHC Updated Mask";
CM_ SG_ 2566862587 BATT_sohcPrimed_5 "SOHC Primed Mask";
CM_ SG_ 2566862587 BATT_capBrick14_5 "Capacity of brick 14";
CM_ SG_ 2566862587 BATT_capBrick13_5 "Capacity of brick 13";
CM_ BO_ 2566862588 "Capacity of bricks 13-14";
CM_ SG_ 2566862588 BATT_sohcUpdated_6 "SOHC Updated Mask";
CM_ SG_ 2566862588 BATT_sohcPrimed_6 "SOHC Primed Mask";
CM_ SG_ 2566862588 BATT_capBrick14_6 "Capacity of brick 14";
CM_ SG_ 2566862588 BATT_capBrick13_6 "Capacity of brick 13";
CM_ BO_ 2566862589 "Capacity of bricks 13-14";
CM_ SG_ 2566862589 BATT_sohcUpdated_7 "SOHC Updated Mask";
CM_ SG_ 2566862589 BATT_sohcPrimed_7 "SOHC Primed Mask";
CM_ SG_ 2566862589 BATT_capBrick14_7 "Capacity of brick 14";
CM_ SG_ 2566862589 BATT_capBrick13_7 "Capacity of brick 13";
CM_ BO_ 2566862590 "Capacity of bricks 13-14";
CM_ SG_ 2566862590 BATT_sohcUpdated_8 "SOHC Updated Mask";
CM_ SG_ 2566862590 BATT_sohcPrimed_8 "SOHC Primed Mask";
CM_ SG_ 2566862590 BATT_capBrick14_8 "Capacity of brick 14";
CM_ SG_ 2566862590 BATT_capBrick13_8 "Capacity of brick 13";
CM_ BO_ 2566862591 "Capacity of bricks 13-14";
CM_ SG_ 2566862591 BATT_sohcUpdated_9 "SOHC Updated Mask";
CM_ SG_ 2566862591 BATT_sohcPrimed_9 "SOHC Primed Mask";
CM_ SG_ 2566862591 BATT_capBrick14_9 "Capacity of brick 14";
CM_ SG_ 2566862591 BATT_capBrick13_9 "Capacity of brick 13";
CM_ BO_ 2566862838 "Voltages of bricks 13-14";
CM_ SG_ 2566862838 BATT_vBrick14_0 "Voltage of brick 14";
CM_ SG_ 2566862838 BATT_vBrick13_0 "Voltage of brick 13";
CM_ BO_ 2566862839 "Voltages of bricks 13-14";
CM_ SG_ 2566862839 BATT_vBrick14_1 "Voltage of brick 14";
CM_ SG_ 2566862839 BATT_vBrick13_1 "Voltage of brick 13";
CM_ BO_ 2566862840 "Voltages of bricks 13-14";
CM_ SG_ 2566862840 BATT_vBrick14_2 "Voltage of brick 14";
CM_ SG_ 2566862840 BATT_vBrick13_2 "Voltage of brick 13";
BA_DEF_ SG_  "SigType" ENUM "Default","Range","RangeSigned","ASCII","Discrete","Control","ReferencePGN","DTC","StringDelimiter","StringLength","StringLengthControl","MessageCounter","MessageChecksum";
BA_DEF_ SG_  "GenSigSendType" ENUM "Cyclic","OnWrite","OnWriteWithRepetition","OnChange","OnChangeWithRepetition","IfActive","IfActiveWithRepetition","NoSigSendType";
BA_DEF_ BO_  "GenMsgDiag" ENUM "No","Yes";
BA_DEF_ BO_  "GenMsgInstanced" STRING ;
BA_DEF_ SG_  "GenSigType" ENUM "Extended","Diagnostic","Standard","Modified";
BA_DEF_ BO_  "GenMsgCycleTime" INT 0 0;
BA_DEF_ SG_  "GenSigSNA" INT 0 65535;
BA_DEF_ SG_  "Access" ENUM "r","rw";
BA_DEF_ BO_  "VFrameFormat" ENUM "StandardCAN","ExtendedCAN","reserved","J1939PG";
BA_DEF_DEF_  "SigType" "Default";
BA_DEF_DEF_  "GenSigSendType" "Cyclic";
BA_DEF_DEF_  "GenMsgDiag" "No";
BA_DEF_DEF_  "GenMsgInstanced" "No";
BA_DEF_DEF_  "GenSigType" "Standard";
BA_DEF_DEF_  "GenMsgCycleTime" 0;
BA_DEF_DEF_  "GenSigSNA" 0;
BA_DEF_DEF_  "Access" "r";
BA_DEF_DEF_  "VFrameFormat" "J1939PG";
BA_ "GenMsgDiag" BO_ 2566854390 1;
BA_ "GenMsgDiag" BO_ 2566854391 1;
BA_ "GenMsgDiag" BO_ 2566854392 1;
BA_ "GenMsgDiag" BO_ 2566854393 1;
BA_ "GenMsgDiag" BO_ 2566854394 1;
BA_ "GenMsgDiag" BO_ 2566854395 1;
BA_ "GenMsgDiag" BO_ 2566854396 1;
BA_ "GenMsgDiag" BO_ 2566854397 1;
BA_ "GenMsgDiag" BO_ 2566854398 1;
BA_ "GenMsgDiag" BO_ 2566854399 1;
BA_ "GenMsgDiag" BO_ 2566854646 1;
BA_ "GenMsgDiag" BO_ 2566854647 1;
BA_ "GenMsgDiag" BO_ 2566854648 1;
BA_ "GenMsgDiag" BO_ 2566854649 1;
BA_ "GenMsgDiag" BO_ 2566854650 1;
BA_ "GenMsgDiag" BO_ 2566854651 1;
BA_ "GenMsgDiag" BO_ 2566854652 1;
BA_ "GenMsgDiag" BO_ 2566854653 1;
BA_ "GenMsgDiag" BO_ 2566854654 1;
BA_ "GenMsgDiag" BO_ 2566854655 1;
BA_ "GenMsgDiag" BO_ 2566855158 1;
BA_ "GenMsgDiag" BO_ 2566858486 1;
BA_ "GenMsgDiag" BO_ 2566858487 1;
BA_ "GenMsgDiag" BO_ 2566858488 1;
BA_ "GenMsgDiag" BO_ 2566858489 1;
BA_ "GenMsgDiag" BO_ 2566858490 1;
BA_ "GenMsgDiag" BO_ 2566858491 1;
BA_ "GenMsgDiag" BO_ 2566858492 1;
BA_ "GenMsgDiag" BO_ 2566858493 1;
BA_ "GenMsgDiag" BO_ 2566858494 1;
BA_ "GenMsgDiag" BO_ 2566858495 1;
BA_ "GenMsgDiag" BO_ 2566858742 1;
BA_ "GenMsgDiag" BO_ 2566858743 1;
BA_ "GenMsgDiag" BO_ 2566858744 1;
BA_ "GenMsgDiag" BO_ 2566858745 1;
BA_ "GenMsgDiag" BO_ 2566858746 1;
BA_ "GenMsgDiag" BO_ 2566858747 1;
BA_ "GenMsgDiag" BO_ 2566858748 1;
BA_ "GenMsgDiag" BO_ 2566858749 1;
BA_ "GenMsgDiag" BO_ 2566858750 1;
BA_ "GenMsgDiag" BO_ 2566858751 1;
BA_ "GenMsgDiag" BO_ 2566862582 1;
BA_ "GenMsgDiag" BO_ 2566862583 1;
BA_ "GenMsgDiag" BO_ 2566862584 1;
BA_ "GenMsgDiag" BO_ 2566862585 1;
BA_ "GenMsgDiag" BO_ 2566862586 1;
BA_ "GenMsgDiag" BO_ 2566862587 1;
BA_ "GenMsgDiag" BO_ 2566862588 1;
BA_ "GenMsgDiag" BO_ 2566862589 1;
BA_ "GenMsgDiag" BO_ 2566862590 1;
BA_ "GenMsgDiag" BO_ 2566862591 1;
BA_ "GenMsgDiag" BO_ 2566862838 1;
BA_ "GenMsgDiag" BO_ 2566862839 1;
BA_ "GenMsgDiag" BO_ 2566862840 1;
BA_ "GenMsgInstanced" BO_ 2566852862 "False";
BA_ "GenMsgInstanced" BO_ 2566852863 "False";
BA_ "GenMsgInstanced" BO_ 2566853110 "False";
BA_ "GenMsgInstanced" BO_ 2566853111 "False";
BA_ "GenMsgInstanced" BO_ 2566853112 "False";
BA_ "GenMsgInstanced" BO_ 2566853113 "False";
BA_ "GenMsgInstanced" BO_ 2566853114 "False";
BA_ "GenMsgInstanced" BO_ 2566853115 "False";
BA_ "GenMsgInstanced" BO_ 2566853116 "False";
BA_ "GenMsgInstanced" BO_ 2566853117 "False";
BA_ "GenMsgInstanced" BO_ 2566853118 "False";
BA_ "GenMsgInstanced" BO_ 2566853119 "False";
BA_ "GenMsgInstanced" BO_ 2566853622 "False";
BA_ "GenMsgInstanced" BO_ 2566853623 "False";
BA_ "GenMsgInstanced" BO_ 2566853624 "False";
BA_ "GenMsgInstanced" BO_ 2566853625 "False";
BA_ "GenMsgInstanced" BO_ 2566853626 "False";
BA_ "GenMsgInstanced" BO_ 2566853627 "False";
BA_ "GenMsgInstanced" BO_ 2566853628 "False";
BA_ "GenMsgInstanced" BO_ 2566853629 "False";
BA_ "GenMsgInstanced" BO_ 2566853630 "False";
BA_ "GenMsgInstanced" BO_ 2566853631 "False";
BA_ "GenMsgInstanced" BO_ 2566853877 "False";
BA_ "GenMsgInstanced" BO_ 2566854134 "False";
BA_ "GenMsgInstanced" BO_ 2566854135 "False";
BA_ "GenMsgInstanced" BO_ 2566854136 "False";
BA_ "GenMsgInstanced" BO_ 2566854137 "False";
BA_ "GenMsgInstanced" BO_ 2566854138 "False";
BA_ "GenMsgInstanced" BO_ 2566854139 "False";
BA_ "GenMsgInstanced" BO_ 2566854140 "False";
BA_ "GenMsgInstanced" BO_ 2566854141 "False";
BA_ "GenMsgInstanced" BO_ 2566854142 "False";
BA_ "GenMsgInstanced" BO_ 2566854143 "False";
BA_ "GenMsgInstanced" BO_ 2566854390 "False";
BA_ "GenMsgInstanced" BO_ 2566854391 "False";
BA_ "GenMsgInstanced" BO_ 2566854392 "False";
BA_ "GenMsgInstanced" BO_ 2566854393 "False";
BA_ "GenMsgInstanced" BO_ 2566854394 "False";
BA_ "GenMsgInstanced" BO_ 2566854395 "False";
BA_ "GenMsgInstanced" BO_ 2566854396 "False";
BA_ "GenMsgInstanced" BO_ 2566854397 "False";
BA_ "GenMsgInstanced" BO_ 2566854398 "False";
BA_ "GenMsgInstanced" BO_ 2566854399 "False";
BA_ "GenMsgInstanced" BO_ 2566854646 "False";
BA_ "GenMsgInstanced" BO_ 2566854647 "False";
BA_ "GenMsgInstanced" BO_ 2566854648 "False";
BA_ "GenMsgInstanced" BO_ 2566854649 "False";
BA_ "GenMsgInstanced" BO_ 2566854650 "False";
BA_ "GenMsgInstanced" BO_ 2566854651 "False";
BA_ "GenMsgInstanced" BO_ 2566854652 "False";
BA_ "GenMsgInstanced" BO_ 2566854653 "False";
BA_ "GenMsgInstanced" BO_ 2566854654 "False";
BA_ "GenMsgInstanced" BO_ 2566854655 "False";
BA_ "GenMsgInstanced" BO_ 2566854902 "False";
BA_ "GenMsgInstanced" BO_ 2566854903 "False";
BA_ "GenMsgInstanced" BO_ 2566854904 "False";
BA_ "GenMsgInstanced" BO_ 2566854905 "False";
BA_ "GenMsgInstanced" BO_ 2566854906 "False";
BA_ "GenMsgInstanced" BO_ 2566854907 "False";
BA_ "GenMsgInstanced" BO_ 2566854908 "False";
BA_ "GenMsgInstanced" BO_ 2566854909 "False";
BA_ "GenMsgInstanced" BO_ 2566854910 "False";
BA_ "GenMsgInstanced" BO_ 2566854911 "False";
BA_ "GenMsgInstanced" BO_ 2566855158 "False";
BA_ "GenMsgInstanced" BO_ 2566857718 "False";
BA_ "GenMsgInstanced" BO_ 2566857719 "False";
BA_ "GenMsgInstanced" BO_ 2566857720 "False";
BA_ "GenMsgInstanced" BO_ 2566857721 "False";
BA_ "GenMsgInstanced" BO_ 2566857722 "False";
BA_ "GenMsgInstanced" BO_ 2566857723 "False";
BA_ "GenMsgInstanced" BO_ 2566857724 "False";
BA_ "GenMsgInstanced" BO_ 2566857725 "False";
BA_ "GenMsgInstanced" BO_ 2566857726 "False";
BA_ "GenMsgInstanced" BO_ 2566857727 "False";
BA_ "GenMsgInstanced" BO_ 2566858230 "False";
BA_ "GenMsgInstanced" BO_ 2566858231 "False";
BA_ "GenMsgInstanced" BO_ 2566858232 "False";
BA_ "GenMsgInstanced" BO_ 2566858233 "False";
BA_ "GenMsgInstanced" BO_ 2566858234 "False";
BA_ "GenMsgInstanced" BO_ 2566858235 "False";
BA_ "GenMsgInstanced" BO_ 2566858236 "False";
BA_ "GenMsgInstanced" BO_ 2566858237 "False";
BA_ "GenMsgInstanced" BO_ 2566858238 "False";
BA_ "GenMsgInstanced" BO_ 2566858239 "False";
BA_ "GenMsgInstanced" BO_ 2566858486 "False";
BA_ "GenMsgInstanced" BO_ 2566858487 "False";
BA_ "GenMsgInstanced" BO_ 2566858488 "False";
BA_ "GenMsgInstanced" BO_ 2566858489 "False";
BA_ "GenMsgInstanced" BO_ 2566858490 "False";
BA_ "GenMsgInstanced" BO_ 2566858491 "False";
BA_ "GenMsgInstanced" BO_ 2566858492 "False";
BA_ "GenMsgInstanced" BO_ 2566858493 "False";
BA_ "GenMsgInstanced" BO_ 2566858494 "False";
BA_ "GenMsgInstanced" BO_ 2566858495 "False";
BA_ "GenMsgInstanced" BO_ 2566858742 "False";
BA_ "GenMsgInstanced" BO_ 2566858743 "False";
BA_ "GenMsgInstanced" BO_ 2566858744 "False";
BA_ "GenMsgInstanced" BO_ 2566858745 "False";
BA_ "GenMsgInstanced" BO_ 2566858746 "False";
BA_ "GenMsgInstanced" BO_ 2566858747 "False";
BA_ "GenMsgInstanced" BO_ 2566858748 "False";
BA_ "GenMsgInstanced" BO_ 2566858749 "False";
BA_ "GenMsgInstanced" BO_ 2566858750 "False";
BA_ "GenMsgInstanced" BO_ 2566858751 "False";
BA_ "GenMsgInstanced" BO_ 2566858998 "False";
BA_ "GenMsgInstanced" BO_ 2566858999 "False";
BA_ "GenMsgInstanced" BO_ 2566859000 "False";
BA_ "GenMsgInstanced" BO_ 2566859001 "False";
BA_ "GenMsgInstanced" BO_ 2566859002 "False";
BA_ "GenMsgInstanced" BO_ 2566859003 "False";
BA_ "GenMsgInstanced" BO_ 2566859004 "False";
BA_ "GenMsgInstanced" BO_ 2566859005 "False";
BA_ "GenMsgInstanced" BO_ 2566859006 "False";
BA_ "GenMsgInstanced" BO_ 2566859007 "False";
BA_ "GenMsgInstanced" BO_ 2566861814 "False";
BA_ "GenMsgInstanced" BO_ 2566861815 "False";
BA_ "GenMsgInstanced" BO_ 2566861816 "False";
BA_ "GenMsgInstanced" BO_ 2566861817 "False";
BA_ "GenMsgInstanced" BO_ 2566861818 "False";
BA_ "GenMsgInstanced" BO_ 2566861819 "False";
BA_ "GenMsgInstanced" BO_ 2566861820 "False";
BA_ "GenMsgInstanced" BO_ 2566861821 "False";
BA_ "GenMsgInstanced" BO_ 2566861822 "False";
BA_ "GenMsgInstanced" BO_ 2566861823 "False";
BA_ "GenMsgInstanced" BO_ 2566862326 "False";
BA_ "GenMsgInstanced" BO_ 2566862327 "False";
BA_ "GenMsgInstanced" BO_ 2566862328 "False";
BA_ "GenMsgInstanced" BO_ 2566862329 "False";
BA_ "GenMsgInstanced" BO_ 2566862330 "False";
BA_ "GenMsgInstanced" BO_ 2566862331 "False";
BA_ "GenMsgInstanced" BO_ 2566862332 "False";
BA_ "GenMsgInstanced" BO_ 2566862333 "False";
BA_ "GenMsgInstanced" BO_ 2566862334 "False";
BA_ "GenMsgInstanced" BO_ 2566862335 "False";
BA_ "GenMsgInstanced" BO_ 2566862582 "False";
BA_ "GenMsgInstanced" BO_ 2566862583 "False";
BA_ "GenMsgInstanced" BO_ 2566862584 "False";
BA_ "GenMsgInstanced" BO_ 2566862585 "False";
BA_ "GenMsgInstanced" BO_ 2566862586 "False";
BA_ "GenMsgInstanced" BO_ 2566862587 "False";
BA_ "GenMsgInstanced" BO_ 2566862588 "False";
BA_ "GenMsgInstanced" BO_ 2566862589 "False";
BA_ "GenMsgInstanced" BO_ 2566862590 "False";
BA_ "GenMsgInstanced" BO_ 2566862591 "False";
BA_ "GenMsgInstanced" BO_ 2566862838 "False";
BA_ "GenMsgInstanced" BO_ 2566862839 "False";
BA_ "GenMsgInstanced" BO_ 2566862840 "False";
BA_ "GenMsgCycleTime" BO_ 2566855158 1000;
BA_ "GenSigType" SG_ 2566852862 BATT_packModIdFault_8 1;
BA_ "GenSigType" SG_ 2566852862 BATT_packModExitedFromBus_8 1;
BA_ "GenSigType" SG_ 2566852862 BATT_packFetChgWelded_8 1;
BA_ "GenSigType" SG_ 2566852862 BATT_packFetDsgWelded_8 1;
BA_ "GenSigType" SG_ 2566852862 BATT_fetDsgShortedAux_8 1;
BA_ "GenSigType" SG_ 2566852862 BATT_fetChgShortedAux_8 1;
BA_ "GenSigType" SG_ 2566852862 BATT_prechargeFetFail_8 1;
BA_ "GenSigType" SG_ 2566852862 BATT_abnormalResetReason_8 1;
BA_ "GenSigType" SG_ 2566852862 BATT_prechargeTooSlow_8 1;
BA_ "GenSigType" SG_ 2566852862 BATT_prechargeTooFast_8 1;
BA_ "GenSigType" SG_ 2566852862 BATT_prechargeTimeout_8 1;
BA_ "GenSigType" SG_ 2566852862 BATT_fetChgShorted_8 1;
BA_ "GenSigType" SG_ 2566852862 BATT_fetChgFailToClose_8 1;
BA_ "GenSigType" SG_ 2566852862 BATT_packModSelectFault_8 1;
BA_ "GenSigType" SG_ 2566852862 BATT_packModConnectFault_8 1;
BA_ "GenSigType" SG_ 2566852862 BATT_packModMIA_8 1;
BA_ "GenSigType" SG_ 2566852862 BATT_packModImbalance_8 1;
BA_ "GenSigType" SG_ 2566852862 BATT_afeFault_8 1;
BA_ "GenSigType" SG_ 2566852862 BATT_chargerMIA_8 1;
BA_ "GenSigType" SG_ 2566852862 BATT_chargerError_8 1;
BA_ "GenSigType" SG_ 2566852862 BATT_vBrickUnderWar_8 1;
BA_ "GenSigType" SG_ 2566852862 BATT_vBrickUnderSev_8 1;
BA_ "GenSigType" SG_ 2566852862 BATT_vBrickUnderMod_8 1;
BA_ "GenSigType" SG_ 2566852862 BATT_vBrickOverWar_8 1;
BA_ "GenSigType" SG_ 2566852862 BATT_vBrickOverSev_8 1;
BA_ "GenSigType" SG_ 2566852862 BATT_vBrickOverMod_8 1;
BA_ "GenSigType" SG_ 2566852862 BATT_vBrickImbalance_8 1;
BA_ "GenSigType" SG_ 2566852862 BATT_loggerAlmostFull_8 1;
BA_ "GenSigType" SG_ 2566852862 BATT_tempModuleUnderWar_8 1;
BA_ "GenSigType" SG_ 2566852862 BATT_tempModuleUnderSev_8 1;
BA_ "GenSigType" SG_ 2566852862 BATT_tempModuleUnderMod_8 1;
BA_ "GenSigType" SG_ 2566852862 BATT_tempModuleOverWar_8 1;
BA_ "GenSigType" SG_ 2566852862 BATT_tempModuleOverSev_8 1;
BA_ "GenSigType" SG_ 2566852862 BATT_tempModuleOverMod_8 1;
BA_ "GenSigType" SG_ 2566852862 BATT_tempBrickImbalance_8 1;
BA_ "GenSigType" SG_ 2566852862 BATT_taskLockupError_8 1;
BA_ "GenSigType" SG_ 2566852862 BATT_tempBoardOverWar_8 1;
BA_ "GenSigType" SG_ 2566852862 BATT_tempBoardOverSev_8 1;
BA_ "GenSigType" SG_ 2566852862 BATT_tempBoardOverMod_8 1;
BA_ "GenSigType" SG_ 2566852862 BATT_sensePackVoltError_8 1;
BA_ "GenSigType" SG_ 2566852862 BATT_senseLoadVoltError_8 1;
BA_ "GenSigType" SG_ 2566852862 BATT_loggerFull_8 1;
BA_ "GenSigType" SG_ 2566852862 BATT_senseCurrentError_8 1;
BA_ "GenSigType" SG_ 2566852862 BATT_senseBrickTempError_8 1;
BA_ "GenSigType" SG_ 2566852862 BATT_resPackHigh_8 1;
BA_ "GenSigType" SG_ 2566852862 BATT_ramOverUtilError_8 1;
BA_ "GenSigType" SG_ 2566852862 BATT_powerPackInsufficient_8 1;
BA_ "GenSigType" SG_ 2566852862 BATT_packCellSoftShort_8 1;
BA_ "GenSigType" SG_ 2566852862 BATT_iOverHardware_8 1;
BA_ "GenSigType" SG_ 2566852862 BATT_fetOverTemp_8 1;
BA_ "GenSigType" SG_ 2566852862 BATT_iOverDischarge_8 1;
BA_ "GenSigType" SG_ 2566852862 BATT_iOverCharge_8 1;
BA_ "GenSigType" SG_ 2566852862 BATT_inverterDriveMIA_8 1;
BA_ "GenSigType" SG_ 2566852862 BATT_iUnderCharge_8 1;
BA_ "GenSigType" SG_ 2566852862 BATT_hostMIA_8 1;
BA_ "GenSigType" SG_ 2566852862 BATT_fetDsgShorted_8 1;
BA_ "GenSigType" SG_ 2566852862 BATT_fetDsgFailToClose_8 1;
BA_ "GenSigType" SG_ 2566852862 BATT_capLow_8 1;
BA_ "GenSigType" SG_ 2566852862 BATT_brickOverDischarge_8 1;
BA_ "GenSigType" SG_ 2566852862 BATT_brickOverCharge_8 1;
BA_ "GenSigType" SG_ 2566852862 BATT_bmsProcessorError_8 1;
BA_ "GenSigType" SG_ 2566852862 BATT_bmsMemoryError_8 1;
BA_ "GenSigType" SG_ 2566852862 BATT_afeError_8 1;
BA_ "GenSigType" SG_ 2566852863 BATT_packModIdFault_9 1;
BA_ "GenSigType" SG_ 2566852863 BATT_packModExitedFromBus_9 1;
BA_ "GenSigType" SG_ 2566852863 BATT_packFetChgWelded_9 1;
BA_ "GenSigType" SG_ 2566852863 BATT_packFetDsgWelded_9 1;
BA_ "GenSigType" SG_ 2566852863 BATT_fetDsgShortedAux_9 1;
BA_ "GenSigType" SG_ 2566852863 BATT_fetChgShortedAux_9 1;
BA_ "GenSigType" SG_ 2566852863 BATT_prechargeFetFail_9 1;
BA_ "GenSigType" SG_ 2566852863 BATT_abnormalResetReason_9 1;
BA_ "GenSigType" SG_ 2566852863 BATT_prechargeTooSlow_9 1;
BA_ "GenSigType" SG_ 2566852863 BATT_prechargeTooFast_9 1;
BA_ "GenSigType" SG_ 2566852863 BATT_prechargeTimeout_9 1;
BA_ "GenSigType" SG_ 2566852863 BATT_fetChgShorted_9 1;
BA_ "GenSigType" SG_ 2566852863 BATT_fetChgFailToClose_9 1;
BA_ "GenSigType" SG_ 2566852863 BATT_packModSelectFault_9 1;
BA_ "GenSigType" SG_ 2566852863 BATT_packModConnectFault_9 1;
BA_ "GenSigType" SG_ 2566852863 BATT_packModMIA_9 1;
BA_ "GenSigType" SG_ 2566852863 BATT_packModImbalance_9 1;
BA_ "GenSigType" SG_ 2566852863 BATT_afeFault_9 1;
BA_ "GenSigType" SG_ 2566852863 BATT_chargerMIA_9 1;
BA_ "GenSigType" SG_ 2566852863 BATT_chargerError_9 1;
BA_ "GenSigType" SG_ 2566852863 BATT_vBrickUnderWar_9 1;
BA_ "GenSigType" SG_ 2566852863 BATT_vBrickUnderSev_9 1;
BA_ "GenSigType" SG_ 2566852863 BATT_vBrickUnderMod_9 1;
BA_ "GenSigType" SG_ 2566852863 BATT_vBrickOverWar_9 1;
BA_ "GenSigType" SG_ 2566852863 BATT_vBrickOverSev_9 1;
BA_ "GenSigType" SG_ 2566852863 BATT_vBrickOverMod_9 1;
BA_ "GenSigType" SG_ 2566852863 BATT_vBrickImbalance_9 1;
BA_ "GenSigType" SG_ 2566852863 BATT_loggerAlmostFull_9 1;
BA_ "GenSigType" SG_ 2566852863 BATT_tempModuleUnderWar_9 1;
BA_ "GenSigType" SG_ 2566852863 BATT_tempModuleUnderSev_9 1;
BA_ "GenSigType" SG_ 2566852863 BATT_tempModuleUnderMod_9 1;
BA_ "GenSigType" SG_ 2566852863 BATT_tempModuleOverWar_9 1;
BA_ "GenSigType" SG_ 2566852863 BATT_tempModuleOverSev_9 1;
BA_ "GenSigType" SG_ 2566852863 BATT_tempModuleOverMod_9 1;
BA_ "GenSigType" SG_ 2566852863 BATT_tempBrickImbalance_9 1;
BA_ "GenSigType" SG_ 2566852863 BATT_taskLockupError_9 1;
BA_ "GenSigType" SG_ 2566852863 BATT_tempBoardOverWar_9 1;
BA_ "GenSigType" SG_ 2566852863 BATT_tempBoardOverSev_9 1;
BA_ "GenSigType" SG_ 2566852863 BATT_tempBoardOverMod_9 1;
BA_ "GenSigType" SG_ 2566852863 BATT_sensePackVoltError_9 1;
BA_ "GenSigType" SG_ 2566852863 BATT_senseLoadVoltError_9 1;
BA_ "GenSigType" SG_ 2566852863 BATT_loggerFull_9 1;
BA_ "GenSigType" SG_ 2566852863 BATT_senseCurrentError_9 1;
BA_ "GenSigType" SG_ 2566852863 BATT_senseBrickTempError_9 1;
BA_ "GenSigType" SG_ 2566852863 BATT_resPackHigh_9 1;
BA_ "GenSigType" SG_ 2566852863 BATT_ramOverUtilError_9 1;
BA_ "GenSigType" SG_ 2566852863 BATT_powerPackInsufficient_9 1;
BA_ "GenSigType" SG_ 2566852863 BATT_packCellSoftShort_9 1;
BA_ "GenSigType" SG_ 2566852863 BATT_iOverHardware_9 1;
BA_ "GenSigType" SG_ 2566852863 BATT_fetOverTemp_9 1;
BA_ "GenSigType" SG_ 2566852863 BATT_iOverDischarge_9 1;
BA_ "GenSigType" SG_ 2566852863 BATT_iOverCharge_9 1;
BA_ "GenSigType" SG_ 2566852863 BATT_inverterDriveMIA_9 1;
BA_ "GenSigType" SG_ 2566852863 BATT_iUnderCharge_9 1;
BA_ "GenSigType" SG_ 2566852863 BATT_hostMIA_9 1;
BA_ "GenSigType" SG_ 2566852863 BATT_fetDsgShorted_9 1;
BA_ "GenSigType" SG_ 2566852863 BATT_fetDsgFailToClose_9 1;
BA_ "GenSigType" SG_ 2566852863 BATT_capLow_9 1;
BA_ "GenSigType" SG_ 2566852863 BATT_brickOverDischarge_9 1;
BA_ "GenSigType" SG_ 2566852863 BATT_brickOverCharge_9 1;
BA_ "GenSigType" SG_ 2566852863 BATT_bmsProcessorError_9 1;
BA_ "GenSigType" SG_ 2566852863 BATT_bmsMemoryError_9 1;
BA_ "GenSigType" SG_ 2566852863 BATT_afeError_9 1;
BA_ "GenSigType" SG_ 2566853110 BATT_packModCurrImbalance_0 1;
BA_ "GenSigType" SG_ 2566853110 BATT_packModTempImbalance_0 1;
BA_ "GenSigType" SG_ 2566853110 BATT_vBrickImbalanceWarning_0 1;
BA_ "GenSigType" SG_ 2566853110 BATT_chargeNotNeeded_0 1;
BA_ "GenSigType" SG_ 2566853110 BATT_modThermistorOpenWire_0 1;
BA_ "GenSigType" SG_ 2566853110 BATT_multiIgnLoFault_0 1;
BA_ "GenSigType" SG_ 2566853110 BATT_modThermistorShorted_0 1;
BA_ "GenSigType" SG_ 2566853110 BATT_cellOpenWire_0 1;
BA_ "GenSigType" SG_ 2566853110 BATT_flashBootCRCError_0 1;
BA_ "GenSigType" SG_ 2566853110 BATT_flashAppCRCError_0 1;
BA_ "GenSigType" SG_ 2566853110 BATT_harnessImpedanceFault_0 1;
BA_ "GenSigType" SG_ 2566853110 BATT_packLevelArbitrationFault_0 1;
BA_ "GenSigType" SG_ 2566853111 BATT_harnessImpedanceFault_1 1;
BA_ "GenSigType" SG_ 2566853111 BATT_packLevelArbitrationFault_1 1;
BA_ "GenSigType" SG_ 2566853111 BATT_multiIgnLoFault_1 1;
BA_ "GenSigType" SG_ 2566853111 BATT_modThermistorShorted_1 1;
BA_ "GenSigType" SG_ 2566853111 BATT_vBrickImbalanceWarning_1 1;
BA_ "GenSigType" SG_ 2566853111 BATT_flashAppCRCError_1 1;
BA_ "GenSigType" SG_ 2566853111 BATT_cellOpenWire_1 1;
BA_ "GenSigType" SG_ 2566853111 BATT_packModCurrImbalance_1 1;
BA_ "GenSigType" SG_ 2566853111 BATT_flashBootCRCError_1 1;
BA_ "GenSigType" SG_ 2566853111 BATT_modThermistorOpenWire_1 1;
BA_ "GenSigType" SG_ 2566853111 BATT_chargeNotNeeded_1 1;
BA_ "GenSigType" SG_ 2566853111 BATT_packModTempImbalance_1 1;
BA_ "GenSigType" SG_ 2566853112 BATT_vBrickImbalanceWarning_2 1;
BA_ "GenSigType" SG_ 2566853112 BATT_harnessImpedanceFault_2 1;
BA_ "GenSigType" SG_ 2566853112 BATT_chargeNotNeeded_2 1;
BA_ "GenSigType" SG_ 2566853112 BATT_packModTempImbalance_2 1;
BA_ "GenSigType" SG_ 2566853112 BATT_modThermistorShorted_2 1;
BA_ "GenSigType" SG_ 2566853112 BATT_modThermistorOpenWire_2 1;
BA_ "GenSigType" SG_ 2566853112 BATT_packLevelArbitrationFault_2 1;
BA_ "GenSigType" SG_ 2566853112 BATT_multiIgnLoFault_2 1;
BA_ "GenSigType" SG_ 2566853112 BATT_flashAppCRCError_2 1;
BA_ "GenSigType" SG_ 2566853112 BATT_cellOpenWire_2 1;
BA_ "GenSigType" SG_ 2566853112 BATT_packModCurrImbalance_2 1;
BA_ "GenSigType" SG_ 2566853112 BATT_flashBootCRCError_2 1;
BA_ "GenSigType" SG_ 2566853113 BATT_vBrickImbalanceWarning_3 1;
BA_ "GenSigType" SG_ 2566853113 BATT_modThermistorOpenWire_3 1;
BA_ "GenSigType" SG_ 2566853113 BATT_chargeNotNeeded_3 1;
BA_ "GenSigType" SG_ 2566853113 BATT_packModTempImbalance_3 1;
BA_ "GenSigType" SG_ 2566853113 BATT_packModCurrImbalance_3 1;
BA_ "GenSigType" SG_ 2566853113 BATT_flashBootCRCError_3 1;
BA_ "GenSigType" SG_ 2566853113 BATT_multiIgnLoFault_3 1;
BA_ "GenSigType" SG_ 2566853113 BATT_modThermistorShorted_3 1;
BA_ "GenSigType" SG_ 2566853113 BATT_harnessImpedanceFault_3 1;
BA_ "GenSigType" SG_ 2566853113 BATT_packLevelArbitrationFault_3 1;
BA_ "GenSigType" SG_ 2566853113 BATT_flashAppCRCError_3 1;
BA_ "GenSigType" SG_ 2566853113 BATT_cellOpenWire_3 1;
BA_ "GenSigType" SG_ 2566853114 BATT_harnessImpedanceFault_4 1;
BA_ "GenSigType" SG_ 2566853114 BATT_packLevelArbitrationFault_4 1;
BA_ "GenSigType" SG_ 2566853114 BATT_modThermistorOpenWire_4 1;
BA_ "GenSigType" SG_ 2566853114 BATT_chargeNotNeeded_4 1;
BA_ "GenSigType" SG_ 2566853114 BATT_vBrickImbalanceWarning_4 1;
BA_ "GenSigType" SG_ 2566853114 BATT_multiIgnLoFault_4 1;
BA_ "GenSigType" SG_ 2566853114 BATT_modThermistorShorted_4 1;
BA_ "GenSigType" SG_ 2566853114 BATT_cellOpenWire_4 1;
BA_ "GenSigType" SG_ 2566853114 BATT_flashBootCRCError_4 1;
BA_ "GenSigType" SG_ 2566853114 BATT_flashAppCRCError_4 1;
BA_ "GenSigType" SG_ 2566853114 BATT_packModTempImbalance_4 1;
BA_ "GenSigType" SG_ 2566853114 BATT_packModCurrImbalance_4 1;
BA_ "GenSigType" SG_ 2566853115 BATT_harnessImpedanceFault_5 1;
BA_ "GenSigType" SG_ 2566853115 BATT_packLevelArbitrationFault_5 1;
BA_ "GenSigType" SG_ 2566853115 BATT_multiIgnLoFault_5 1;
BA_ "GenSigType" SG_ 2566853115 BATT_modThermistorShorted_5 1;
BA_ "GenSigType" SG_ 2566853115 BATT_modThermistorOpenWire_5 1;
BA_ "GenSigType" SG_ 2566853115 BATT_vBrickImbalanceWarning_5 1;
BA_ "GenSigType" SG_ 2566853115 BATT_flashAppCRCError_5 1;
BA_ "GenSigType" SG_ 2566853115 BATT_cellOpenWire_5 1;
BA_ "GenSigType" SG_ 2566853115 BATT_packModCurrImbalance_5 1;
BA_ "GenSigType" SG_ 2566853115 BATT_flashBootCRCError_5 1;
BA_ "GenSigType" SG_ 2566853115 BATT_chargeNotNeeded_5 1;
BA_ "GenSigType" SG_ 2566853115 BATT_packModTempImbalance_5 1;
BA_ "GenSigType" SG_ 2566853116 BATT_modThermistorShorted_6 1;
BA_ "GenSigType" SG_ 2566853116 BATT_modThermistorOpenWire_6 1;
BA_ "GenSigType" SG_ 2566853116 BATT_packLevelArbitrationFault_6 1;
BA_ "GenSigType" SG_ 2566853116 BATT_multiIgnLoFault_6 1;
BA_ "GenSigType" SG_ 2566853116 BATT_flashAppCRCError_6 1;
BA_ "GenSigType" SG_ 2566853116 BATT_cellOpenWire_6 1;
BA_ "GenSigType" SG_ 2566853116 BATT_vBrickImbalanceWarning_6 1;
BA_ "GenSigType" SG_ 2566853116 BATT_harnessImpedanceFault_6 1;
BA_ "GenSigType" SG_ 2566853116 BATT_packModCurrImbalance_6 1;
BA_ "GenSigType" SG_ 2566853116 BATT_flashBootCRCError_6 1;
BA_ "GenSigType" SG_ 2566853116 BATT_chargeNotNeeded_6 1;
BA_ "GenSigType" SG_ 2566853116 BATT_packModTempImbalance_6 1;
BA_ "GenSigType" SG_ 2566853117 BATT_multiIgnLoFault_7 1;
BA_ "GenSigType" SG_ 2566853117 BATT_packLevelArbitrationFault_7 1;
BA_ "GenSigType" SG_ 2566853117 BATT_modThermistorShorted_7 1;
BA_ "GenSigType" SG_ 2566853117 BATT_cellOpenWire_7 1;
BA_ "GenSigType" SG_ 2566853117 BATT_flashBootCRCError_7 1;
BA_ "GenSigType" SG_ 2566853117 BATT_flashAppCRCError_7 1;
BA_ "GenSigType" SG_ 2566853117 BATT_packModTempImbalance_7 1;
BA_ "GenSigType" SG_ 2566853117 BATT_packModCurrImbalance_7 1;
BA_ "GenSigType" SG_ 2566853117 BATT_chargeNotNeeded_7 1;
BA_ "GenSigType" SG_ 2566853117 BATT_modThermistorOpenWire_7 1;
BA_ "GenSigType" SG_ 2566853117 BATT_vBrickImbalanceWarning_7 1;
BA_ "GenSigType" SG_ 2566853117 BATT_harnessImpedanceFault_7 1;
BA_ "GenSigType" SG_ 2566853118 BATT_packLevelArbitrationFault_8 1;
BA_ "GenSigType" SG_ 2566853118 BATT_harnessImpedanceFault_8 1;
BA_ "GenSigType" SG_ 2566853118 BATT_multiIgnLoFault_8 1;
BA_ "GenSigType" SG_ 2566853118 BATT_vBrickImbalanceWarning_8 1;
BA_ "GenSigType" SG_ 2566853118 BATT_flashAppCRCError_8 1;
BA_ "GenSigType" SG_ 2566853118 BATT_flashBootCRCError_8 1;
BA_ "GenSigType" SG_ 2566853118 BATT_packModCurrImbalance_8 1;
BA_ "GenSigType" SG_ 2566853118 BATT_cellOpenWire_8 1;
BA_ "GenSigType" SG_ 2566853118 BATT_packModTempImbalance_8 1;
BA_ "GenSigType" SG_ 2566853118 BATT_chargeNotNeeded_8 1;
BA_ "GenSigType" SG_ 2566853118 BATT_modThermistorOpenWire_8 1;
BA_ "GenSigType" SG_ 2566853118 BATT_modThermistorShorted_8 1;
BA_ "GenSigType" SG_ 2566853119 BATT_packModTempImbalance_9 1;
BA_ "GenSigType" SG_ 2566853119 BATT_modThermistorShorted_9 1;
BA_ "GenSigType" SG_ 2566853119 BATT_multiIgnLoFault_9 1;
BA_ "GenSigType" SG_ 2566853119 BATT_flashBootCRCError_9 1;
BA_ "GenSigType" SG_ 2566853119 BATT_packModCurrImbalance_9 1;
BA_ "GenSigType" SG_ 2566853119 BATT_modThermistorOpenWire_9 1;
BA_ "GenSigType" SG_ 2566853119 BATT_cellOpenWire_9 1;
BA_ "GenSigType" SG_ 2566853119 BATT_chargeNotNeeded_9 1;
BA_ "GenSigType" SG_ 2566853119 BATT_harnessImpedanceFault_9 1;
BA_ "GenSigType" SG_ 2566853119 BATT_flashAppCRCError_9 1;
BA_ "GenSigType" SG_ 2566853119 BATT_packLevelArbitrationFault_9 1;
BA_ "GenSigType" SG_ 2566853119 BATT_vBrickImbalanceWarning_9 1;
BA_ "GenSigType" SG_ 2566853877 BATT_isPushBtn_Requested 0;
BA_ "GenSigType" SG_ 2566853877 BATT_startNodeId 0;
BA_ "GenSigType" SG_ 2566853877 BATT_stateRequest 0;
BA_ "GenSigType" SG_ 2566853877 BATT_modReqCntr 0;
BA_ "GenSigType" SG_ 2566853877 BATT_isIgnLo_Requested 0;
BA_ "GenSigType" SG_ 2566854390 BATT_capBrick08_0 1;
BA_ "GenSigType" SG_ 2566854390 BATT_capBrick07_0 1;
BA_ "GenSigType" SG_ 2566854390 BATT_capBrick06_0 1;
BA_ "GenSigType" SG_ 2566854390 BATT_capBrick05_0 1;
BA_ "GenSigType" SG_ 2566854391 BATT_capBrick08_1 1;
BA_ "GenSigType" SG_ 2566854391 BATT_capBrick07_1 1;
BA_ "GenSigType" SG_ 2566854391 BATT_capBrick06_1 1;
BA_ "GenSigType" SG_ 2566854391 BATT_capBrick05_1 1;
BA_ "GenSigType" SG_ 2566854392 BATT_capBrick08_2 1;
BA_ "GenSigType" SG_ 2566854392 BATT_capBrick07_2 1;
BA_ "GenSigType" SG_ 2566854392 BATT_capBrick06_2 1;
BA_ "GenSigType" SG_ 2566854392 BATT_capBrick05_2 1;
BA_ "GenSigType" SG_ 2566854393 BATT_capBrick08_3 1;
BA_ "GenSigType" SG_ 2566854393 BATT_capBrick07_3 1;
BA_ "GenSigType" SG_ 2566854393 BATT_capBrick06_3 1;
BA_ "GenSigType" SG_ 2566854393 BATT_capBrick05_3 1;
BA_ "GenSigType" SG_ 2566854394 BATT_capBrick08_4 1;
BA_ "GenSigType" SG_ 2566854394 BATT_capBrick07_4 1;
BA_ "GenSigType" SG_ 2566854394 BATT_capBrick06_4 1;
BA_ "GenSigType" SG_ 2566854394 BATT_capBrick05_4 1;
BA_ "GenSigType" SG_ 2566854395 BATT_capBrick08_5 1;
BA_ "GenSigType" SG_ 2566854395 BATT_capBrick07_5 1;
BA_ "GenSigType" SG_ 2566854395 BATT_capBrick06_5 1;
BA_ "GenSigType" SG_ 2566854395 BATT_capBrick05_5 1;
BA_ "GenSigType" SG_ 2566854396 BATT_capBrick08_6 1;
BA_ "GenSigType" SG_ 2566854396 BATT_capBrick07_6 1;
BA_ "GenSigType" SG_ 2566854396 BATT_capBrick06_6 1;
BA_ "GenSigType" SG_ 2566854396 BATT_capBrick05_6 1;
BA_ "GenSigType" SG_ 2566854397 BATT_capBrick08_7 1;
BA_ "GenSigType" SG_ 2566854397 BATT_capBrick07_7 1;
BA_ "GenSigType" SG_ 2566854397 BATT_capBrick06_7 1;
BA_ "GenSigType" SG_ 2566854397 BATT_capBrick05_7 1;
BA_ "GenSigType" SG_ 2566854398 BATT_capBrick08_8 1;
BA_ "GenSigType" SG_ 2566854398 BATT_capBrick07_8 1;
BA_ "GenSigType" SG_ 2566854398 BATT_capBrick06_8 1;
BA_ "GenSigType" SG_ 2566854398 BATT_capBrick05_8 1;
BA_ "GenSigType" SG_ 2566854399 BATT_capBrick08_9 1;
BA_ "GenSigType" SG_ 2566854399 BATT_capBrick07_9 1;
BA_ "GenSigType" SG_ 2566854399 BATT_capBrick06_9 1;
BA_ "GenSigType" SG_ 2566854399 BATT_capBrick05_9 1;
BA_ "GenSigType" SG_ 2566854646 BATT_vBrick06_0 1;
BA_ "GenSigType" SG_ 2566854646 BATT_vBrick07_0 1;
BA_ "GenSigType" SG_ 2566854646 BATT_vBrick05_0 1;
BA_ "GenSigType" SG_ 2566854646 BATT_vBrick08_0 1;
BA_ "GenSigType" SG_ 2566854647 BATT_vBrick06_1 1;
BA_ "GenSigType" SG_ 2566854647 BATT_vBrick07_1 1;
BA_ "GenSigType" SG_ 2566854647 BATT_vBrick05_1 1;
BA_ "GenSigType" SG_ 2566854647 BATT_vBrick08_1 1;
BA_ "GenSigType" SG_ 2566854648 BATT_vBrick06_2 1;
BA_ "GenSigType" SG_ 2566854648 BATT_vBrick07_2 1;
BA_ "GenSigType" SG_ 2566854648 BATT_vBrick05_2 1;
BA_ "GenSigType" SG_ 2566854648 BATT_vBrick08_2 1;
BA_ "GenSigType" SG_ 2566854649 BATT_vBrick06_3 1;
BA_ "GenSigType" SG_ 2566854649 BATT_vBrick07_3 1;
BA_ "GenSigType" SG_ 2566854649 BATT_vBrick05_3 1;
BA_ "GenSigType" SG_ 2566854649 BATT_vBrick08_3 1;
BA_ "GenSigType" SG_ 2566854650 BATT_vBrick06_4 1;
BA_ "GenSigType" SG_ 2566854650 BATT_vBrick07_4 1;
BA_ "GenSigType" SG_ 2566854650 BATT_vBrick05_4 1;
BA_ "GenSigType" SG_ 2566854650 BATT_vBrick08_4 1;
BA_ "GenSigType" SG_ 2566854651 BATT_vBrick06_5 1;
BA_ "GenSigType" SG_ 2566854651 BATT_vBrick07_5 1;
BA_ "GenSigType" SG_ 2566854651 BATT_vBrick05_5 1;
BA_ "GenSigType" SG_ 2566854651 BATT_vBrick08_5 1;
BA_ "GenSigType" SG_ 2566854652 BATT_vBrick06_6 1;
BA_ "GenSigType" SG_ 2566854652 BATT_vBrick07_6 1;
BA_ "GenSigType" SG_ 2566854652 BATT_vBrick05_6 1;
BA_ "GenSigType" SG_ 2566854652 BATT_vBrick08_6 1;
BA_ "GenSigType" SG_ 2566854653 BATT_vBrick06_7 1;
BA_ "GenSigType" SG_ 2566854653 BATT_vBrick07_7 1;
BA_ "GenSigType" SG_ 2566854653 BATT_vBrick05_7 1;
BA_ "GenSigType" SG_ 2566854653 BATT_vBrick08_7 1;
BA_ "GenSigType" SG_ 2566854654 BATT_vBrick06_8 1;
BA_ "GenSigType" SG_ 2566854654 BATT_vBrick07_8 1;
BA_ "GenSigType" SG_ 2566854654 BATT_vBrick05_8 1;
BA_ "GenSigType" SG_ 2566854654 BATT_vBrick08_8 1;
BA_ "GenSigType" SG_ 2566854655 BATT_vBrick06_9 1;
BA_ "GenSigType" SG_ 2566854655 BATT_vBrick07_9 1;
BA_ "GenSigType" SG_ 2566854655 BATT_vBrick05_9 1;
BA_ "GenSigType" SG_ 2566854655 BATT_vBrick08_9 1;
BA_ "GenSigType" SG_ 2566855158 BATT_tPreChg 0;
BA_ "GenSigType" SG_ 2566855158 BATT_tFET 0;
BA_ "GenSigType" SG_ 2566855158 BATT_tShunt 0;
BA_ "GenSigType" SG_ 2566858486 BATT_capBrick12_0 1;
BA_ "GenSigType" SG_ 2566858486 BATT_capBrick11_0 1;
BA_ "GenSigType" SG_ 2566858486 BATT_capBrick09_0 1;
BA_ "GenSigType" SG_ 2566858486 BATT_capBrick10_0 1;
BA_ "GenSigType" SG_ 2566858487 BATT_capBrick12_1 1;
BA_ "GenSigType" SG_ 2566858487 BATT_capBrick11_1 1;
BA_ "GenSigType" SG_ 2566858487 BATT_capBrick09_1 1;
BA_ "GenSigType" SG_ 2566858487 BATT_capBrick10_1 1;
BA_ "GenSigType" SG_ 2566858488 BATT_capBrick12_2 1;
BA_ "GenSigType" SG_ 2566858488 BATT_capBrick11_2 1;
BA_ "GenSigType" SG_ 2566858488 BATT_capBrick09_2 1;
BA_ "GenSigType" SG_ 2566858488 BATT_capBrick10_2 1;
BA_ "GenSigType" SG_ 2566858489 BATT_capBrick12_3 1;
BA_ "GenSigType" SG_ 2566858489 BATT_capBrick11_3 1;
BA_ "GenSigType" SG_ 2566858489 BATT_capBrick09_3 1;
BA_ "GenSigType" SG_ 2566858489 BATT_capBrick10_3 1;
BA_ "GenSigType" SG_ 2566858490 BATT_capBrick12_4 1;
BA_ "GenSigType" SG_ 2566858490 BATT_capBrick11_4 1;
BA_ "GenSigType" SG_ 2566858490 BATT_capBrick09_4 1;
BA_ "GenSigType" SG_ 2566858490 BATT_capBrick10_4 1;
BA_ "GenSigType" SG_ 2566858491 BATT_capBrick12_5 1;
BA_ "GenSigType" SG_ 2566858491 BATT_capBrick11_5 1;
BA_ "GenSigType" SG_ 2566858491 BATT_capBrick09_5 1;
BA_ "GenSigType" SG_ 2566858491 BATT_capBrick10_5 1;
BA_ "GenSigType" SG_ 2566858492 BATT_capBrick12_6 1;
BA_ "GenSigType" SG_ 2566858492 BATT_capBrick11_6 1;
BA_ "GenSigType" SG_ 2566858492 BATT_capBrick09_6 1;
BA_ "GenSigType" SG_ 2566858492 BATT_capBrick10_6 1;
BA_ "GenSigType" SG_ 2566858493 BATT_capBrick12_7 1;
BA_ "GenSigType" SG_ 2566858493 BATT_capBrick11_7 1;
BA_ "GenSigType" SG_ 2566858493 BATT_capBrick09_7 1;
BA_ "GenSigType" SG_ 2566858493 BATT_capBrick10_7 1;
BA_ "GenSigType" SG_ 2566858494 BATT_capBrick12_8 1;
BA_ "GenSigType" SG_ 2566858494 BATT_capBrick11_8 1;
BA_ "GenSigType" SG_ 2566858494 BATT_capBrick09_8 1;
BA_ "GenSigType" SG_ 2566858494 BATT_capBrick10_8 1;
BA_ "GenSigType" SG_ 2566858495 BATT_capBrick12_9 1;
BA_ "GenSigType" SG_ 2566858495 BATT_capBrick11_9 1;
BA_ "GenSigType" SG_ 2566858495 BATT_capBrick09_9 1;
BA_ "GenSigType" SG_ 2566858495 BATT_capBrick10_9 1;
BA_ "GenSigType" SG_ 2566858742 BATT_vBrick12_0 1;
BA_ "GenSigType" SG_ 2566858742 BATT_vBrick11_0 1;
BA_ "GenSigType" SG_ 2566858742 BATT_vBrick10_0 1;
BA_ "GenSigType" SG_ 2566858742 BATT_vBrick09_0 1;
BA_ "GenSigType" SG_ 2566858743 BATT_vBrick12_1 1;
BA_ "GenSigType" SG_ 2566858743 BATT_vBrick11_1 1;
BA_ "GenSigType" SG_ 2566858743 BATT_vBrick10_1 1;
BA_ "GenSigType" SG_ 2566858743 BATT_vBrick09_1 1;
BA_ "GenSigType" SG_ 2566858744 BATT_vBrick12_2 1;
BA_ "GenSigType" SG_ 2566858744 BATT_vBrick11_2 1;
BA_ "GenSigType" SG_ 2566858744 BATT_vBrick10_2 1;
BA_ "GenSigType" SG_ 2566858744 BATT_vBrick09_2 1;
BA_ "GenSigType" SG_ 2566858745 BATT_vBrick12_3 1;
BA_ "GenSigType" SG_ 2566858745 BATT_vBrick11_3 1;
BA_ "GenSigType" SG_ 2566858745 BATT_vBrick10_3 1;
BA_ "GenSigType" SG_ 2566858745 BATT_vBrick09_3 1;
BA_ "GenSigType" SG_ 2566858746 BATT_vBrick12_4 1;
BA_ "GenSigType" SG_ 2566858746 BATT_vBrick11_4 1;
BA_ "GenSigType" SG_ 2566858746 BATT_vBrick10_4 1;
BA_ "GenSigType" SG_ 2566858746 BATT_vBrick09_4 1;
BA_ "GenSigType" SG_ 2566858747 BATT_vBrick12_5 1;
BA_ "GenSigType" SG_ 2566858747 BATT_vBrick11_5 1;
BA_ "GenSigType" SG_ 2566858747 BATT_vBrick10_5 1;
BA_ "GenSigType" SG_ 2566858747 BATT_vBrick09_5 1;
BA_ "GenSigType" SG_ 2566858748 BATT_vBrick12_6 1;
BA_ "GenSigType" SG_ 2566858748 BATT_vBrick11_6 1;
BA_ "GenSigType" SG_ 2566858748 BATT_vBrick10_6 1;
BA_ "GenSigType" SG_ 2566858748 BATT_vBrick09_6 1;
BA_ "GenSigType" SG_ 2566858749 BATT_vBrick12_7 1;
BA_ "GenSigType" SG_ 2566858749 BATT_vBrick11_7 1;
BA_ "GenSigType" SG_ 2566858749 BATT_vBrick10_7 1;
BA_ "GenSigType" SG_ 2566858749 BATT_vBrick09_7 1;
BA_ "GenSigType" SG_ 2566858750 BATT_vBrick12_8 1;
BA_ "GenSigType" SG_ 2566858750 BATT_vBrick11_8 1;
BA_ "GenSigType" SG_ 2566858750 BATT_vBrick10_8 1;
BA_ "GenSigType" SG_ 2566858750 BATT_vBrick09_8 1;
BA_ "GenSigType" SG_ 2566858751 BATT_vBrick12_9 1;
BA_ "GenSigType" SG_ 2566858751 BATT_vBrick11_9 1;
BA_ "GenSigType" SG_ 2566858751 BATT_vBrick10_9 1;
BA_ "GenSigType" SG_ 2566858751 BATT_vBrick09_9 1;
BA_ "GenSigType" SG_ 2566862582 BATT_sohcUpdated_0 1;
BA_ "GenSigType" SG_ 2566862582 BATT_sohcPrimed_0 1;
BA_ "GenSigType" SG_ 2566862582 BATT_capBrick14_0 1;
BA_ "GenSigType" SG_ 2566862582 BATT_capBrick13_0 1;
BA_ "GenSigType" SG_ 2566862583 BATT_sohcUpdated_1 1;
BA_ "GenSigType" SG_ 2566862583 BATT_sohcPrimed_1 1;
BA_ "GenSigType" SG_ 2566862583 BATT_capBrick14_1 1;
BA_ "GenSigType" SG_ 2566862583 BATT_capBrick13_1 1;
BA_ "GenSigType" SG_ 2566862584 BATT_sohcUpdated_2 1;
BA_ "GenSigType" SG_ 2566862584 BATT_sohcPrimed_2 1;
BA_ "GenSigType" SG_ 2566862584 BATT_capBrick14_2 1;
BA_ "GenSigType" SG_ 2566862584 BATT_capBrick13_2 1;
BA_ "GenSigType" SG_ 2566862585 BATT_sohcUpdated_3 1;
BA_ "GenSigType" SG_ 2566862585 BATT_sohcPrimed_3 1;
BA_ "GenSigType" SG_ 2566862585 BATT_capBrick14_3 1;
BA_ "GenSigType" SG_ 2566862585 BATT_capBrick13_3 1;
BA_ "GenSigType" SG_ 2566862586 BATT_capBrick14_4 1;
BA_ "GenSigType" SG_ 2566862586 BATT_capBrick13_4 1;
BA_ "GenSigType" SG_ 2566862586 BATT_sohcUpdated_4 1;
BA_ "GenSigType" SG_ 2566862586 BATT_sohcPrimed_4 1;
BA_ "GenSigType" SG_ 2566862587 BATT_sohcUpdated_5 1;
BA_ "GenSigType" SG_ 2566862587 BATT_sohcPrimed_5 1;
BA_ "GenSigType" SG_ 2566862587 BATT_capBrick14_5 1;
BA_ "GenSigType" SG_ 2566862587 BATT_capBrick13_5 1;
BA_ "GenSigType" SG_ 2566862588 BATT_sohcUpdated_6 1;
BA_ "GenSigType" SG_ 2566862588 BATT_sohcPrimed_6 1;
BA_ "GenSigType" SG_ 2566862588 BATT_capBrick14_6 1;
BA_ "GenSigType" SG_ 2566862588 BATT_capBrick13_6 1;
BA_ "GenSigType" SG_ 2566862589 BATT_sohcUpdated_7 1;
BA_ "GenSigType" SG_ 2566862589 BATT_sohcPrimed_7 1;
BA_ "GenSigType" SG_ 2566862589 BATT_capBrick14_7 1;
BA_ "GenSigType" SG_ 2566862589 BATT_capBrick13_7 1;
BA_ "GenSigType" SG_ 2566862590 BATT_sohcUpdated_8 1;
BA_ "GenSigType" SG_ 2566862590 BATT_sohcPrimed_8 1;
BA_ "GenSigType" SG_ 2566862590 BATT_capBrick14_8 1;
BA_ "GenSigType" SG_ 2566862590 BATT_capBrick13_8 1;
BA_ "GenSigType" SG_ 2566862591 BATT_capBrick13_9 1;
BA_ "GenSigType" SG_ 2566862591 BATT_sohcPrimed_9 1;
BA_ "GenSigType" SG_ 2566862591 BATT_capBrick14_9 1;
BA_ "GenSigType" SG_ 2566862591 BATT_sohcUpdated_9 1;
BA_ "GenSigType" SG_ 2566862838 BATT_vBrick14_0 1;
BA_ "GenSigType" SG_ 2566862838 BATT_vBrick13_0 1;
BA_ "GenSigType" SG_ 2566862839 BATT_vBrick13_1 1;
BA_ "GenSigType" SG_ 2566862839 BATT_vBrick14_1 1;
BA_ "GenSigType" SG_ 2566862840 BATT_vBrick14_2 1;
BA_ "GenSigType" SG_ 2566862840 BATT_vBrick13_2 1;
BA_ "GenSigSNA" SG_ 2566853110 BATT_harnessImpedanceFault_0 65535;
BA_ "GenSigSNA" SG_ 2566853111 BATT_harnessImpedanceFault_1 65535;
BA_ "GenSigSNA" SG_ 2566853112 BATT_harnessImpedanceFault_2 65535;
BA_ "GenSigSNA" SG_ 2566853113 BATT_harnessImpedanceFault_3 65535;
BA_ "GenSigSNA" SG_ 2566853114 BATT_harnessImpedanceFault_4 65535;
BA_ "GenSigSNA" SG_ 2566853115 BATT_harnessImpedanceFault_5 65535;
BA_ "GenSigSNA" SG_ 2566853116 BATT_harnessImpedanceFault_6 65535;
BA_ "GenSigSNA" SG_ 2566853117 BATT_harnessImpedanceFault_7 65535;
BA_ "GenSigSNA" SG_ 2566853118 BATT_harnessImpedanceFault_8 65535;
BA_ "GenSigSNA" SG_ 2566853119 BATT_harnessImpedanceFault_9 65535;
BA_ "GenSigSNA" SG_ 2566854390 BATT_capBrick08_0 65535;
BA_ "GenSigSNA" SG_ 2566854390 BATT_capBrick07_0 65535;
BA_ "GenSigSNA" SG_ 2566854390 BATT_capBrick06_0 65535;
BA_ "GenSigSNA" SG_ 2566854390 BATT_capBrick05_0 65535;
BA_ "GenSigSNA" SG_ 2566854391 BATT_capBrick08_1 65535;
BA_ "GenSigSNA" SG_ 2566854391 BATT_capBrick07_1 65535;
BA_ "GenSigSNA" SG_ 2566854391 BATT_capBrick06_1 65535;
BA_ "GenSigSNA" SG_ 2566854391 BATT_capBrick05_1 65535;
BA_ "GenSigSNA" SG_ 2566854392 BATT_capBrick08_2 65535;
BA_ "GenSigSNA" SG_ 2566854392 BATT_capBrick07_2 65535;
BA_ "GenSigSNA" SG_ 2566854392 BATT_capBrick06_2 65535;
BA_ "GenSigSNA" SG_ 2566854392 BATT_capBrick05_2 65535;
BA_ "GenSigSNA" SG_ 2566854393 BATT_capBrick08_3 65535;
BA_ "GenSigSNA" SG_ 2566854393 BATT_capBrick07_3 65535;
BA_ "GenSigSNA" SG_ 2566854393 BATT_capBrick06_3 65535;
BA_ "GenSigSNA" SG_ 2566854393 BATT_capBrick05_3 65535;
BA_ "GenSigSNA" SG_ 2566854394 BATT_capBrick08_4 65535;
BA_ "GenSigSNA" SG_ 2566854394 BATT_capBrick07_4 65535;
BA_ "GenSigSNA" SG_ 2566854394 BATT_capBrick06_4 65535;
BA_ "GenSigSNA" SG_ 2566854394 BATT_capBrick05_4 65535;
BA_ "GenSigSNA" SG_ 2566854395 BATT_capBrick08_5 65535;
BA_ "GenSigSNA" SG_ 2566854395 BATT_capBrick07_5 65535;
BA_ "GenSigSNA" SG_ 2566854395 BATT_capBrick06_5 65535;
BA_ "GenSigSNA" SG_ 2566854395 BATT_capBrick05_5 65535;
BA_ "GenSigSNA" SG_ 2566854396 BATT_capBrick08_6 65535;
BA_ "GenSigSNA" SG_ 2566854396 BATT_capBrick07_6 65535;
BA_ "GenSigSNA" SG_ 2566854396 BATT_capBrick06_6 65535;
BA_ "GenSigSNA" SG_ 2566854396 BATT_capBrick05_6 65535;
BA_ "GenSigSNA" SG_ 2566854397 BATT_capBrick08_7 65535;
BA_ "GenSigSNA" SG_ 2566854397 BATT_capBrick07_7 65535;
BA_ "GenSigSNA" SG_ 2566854397 BATT_capBrick06_7 65535;
BA_ "GenSigSNA" SG_ 2566854397 BATT_capBrick05_7 65535;
BA_ "GenSigSNA" SG_ 2566854398 BATT_capBrick08_8 65535;
BA_ "GenSigSNA" SG_ 2566854398 BATT_capBrick07_8 65535;
BA_ "GenSigSNA" SG_ 2566854398 BATT_capBrick06_8 65535;
BA_ "GenSigSNA" SG_ 2566854398 BATT_capBrick05_8 65535;
BA_ "GenSigSNA" SG_ 2566854399 BATT_capBrick08_9 65535;
BA_ "GenSigSNA" SG_ 2566854399 BATT_capBrick07_9 65535;
BA_ "GenSigSNA" SG_ 2566854399 BATT_capBrick06_9 65535;
BA_ "GenSigSNA" SG_ 2566854399 BATT_capBrick05_9 65535;
BA_ "GenSigSNA" SG_ 2566854646 BATT_vBrick06_0 65535;
BA_ "GenSigSNA" SG_ 2566854646 BATT_vBrick07_0 65535;
BA_ "GenSigSNA" SG_ 2566854646 BATT_vBrick05_0 65535;
BA_ "GenSigSNA" SG_ 2566854646 BATT_vBrick08_0 65535;
BA_ "GenSigSNA" SG_ 2566854647 BATT_vBrick06_1 65535;
BA_ "GenSigSNA" SG_ 2566854647 BATT_vBrick07_1 65535;
BA_ "GenSigSNA" SG_ 2566854647 BATT_vBrick05_1 65535;
BA_ "GenSigSNA" SG_ 2566854647 BATT_vBrick08_1 65535;
BA_ "GenSigSNA" SG_ 2566854648 BATT_vBrick06_2 65535;
BA_ "GenSigSNA" SG_ 2566854648 BATT_vBrick07_2 65535;
BA_ "GenSigSNA" SG_ 2566854648 BATT_vBrick05_2 65535;
BA_ "GenSigSNA" SG_ 2566854648 BATT_vBrick08_2 65535;
BA_ "GenSigSNA" SG_ 2566854649 BATT_vBrick06_3 65535;
BA_ "GenSigSNA" SG_ 2566854649 BATT_vBrick07_3 65535;
BA_ "GenSigSNA" SG_ 2566854649 BATT_vBrick05_3 65535;
BA_ "GenSigSNA" SG_ 2566854649 BATT_vBrick08_3 65535;
BA_ "GenSigSNA" SG_ 2566854650 BATT_vBrick06_4 65535;
BA_ "GenSigSNA" SG_ 2566854650 BATT_vBrick07_4 65535;
BA_ "GenSigSNA" SG_ 2566854650 BATT_vBrick05_4 65535;
BA_ "GenSigSNA" SG_ 2566854650 BATT_vBrick08_4 65535;
BA_ "GenSigSNA" SG_ 2566854651 BATT_vBrick06_5 65535;
BA_ "GenSigSNA" SG_ 2566854651 BATT_vBrick07_5 65535;
BA_ "GenSigSNA" SG_ 2566854651 BATT_vBrick05_5 65535;
BA_ "GenSigSNA" SG_ 2566854651 BATT_vBrick08_5 65535;
BA_ "GenSigSNA" SG_ 2566854652 BATT_vBrick06_6 65535;
BA_ "GenSigSNA" SG_ 2566854652 BATT_vBrick07_6 65535;
BA_ "GenSigSNA" SG_ 2566854652 BATT_vBrick05_6 65535;
BA_ "GenSigSNA" SG_ 2566854652 BATT_vBrick08_6 65535;
BA_ "GenSigSNA" SG_ 2566854653 BATT_vBrick06_7 65535;
BA_ "GenSigSNA" SG_ 2566854653 BATT_vBrick07_7 65535;
BA_ "GenSigSNA" SG_ 2566854653 BATT_vBrick05_7 65535;
BA_ "GenSigSNA" SG_ 2566854653 BATT_vBrick08_7 65535;
BA_ "GenSigSNA" SG_ 2566854654 BATT_vBrick06_8 65535;
BA_ "GenSigSNA" SG_ 2566854654 BATT_vBrick07_8 65535;
BA_ "GenSigSNA" SG_ 2566854654 BATT_vBrick05_8 65535;
BA_ "GenSigSNA" SG_ 2566854654 BATT_vBrick08_8 65535;
BA_ "GenSigSNA" SG_ 2566854655 BATT_vBrick06_9 65535;
BA_ "GenSigSNA" SG_ 2566854655 BATT_vBrick07_9 65535;
BA_ "GenSigSNA" SG_ 2566854655 BATT_vBrick05_9 65535;
BA_ "GenSigSNA" SG_ 2566854655 BATT_vBrick08_9 65535;
BA_ "GenSigSNA" SG_ 2566855158 BATT_tPreChg 65535;
BA_ "GenSigSNA" SG_ 2566855158 BATT_tFET 65535;
BA_ "GenSigSNA" SG_ 2566855158 BATT_tShunt 65535;
BA_ "GenSigSNA" SG_ 2566858486 BATT_capBrick12_0 65535;
BA_ "GenSigSNA" SG_ 2566858486 BATT_capBrick11_0 65535;
BA_ "GenSigSNA" SG_ 2566858486 BATT_capBrick09_0 65535;
BA_ "GenSigSNA" SG_ 2566858486 BATT_capBrick10_0 65535;
BA_ "GenSigSNA" SG_ 2566858487 BATT_capBrick12_1 65535;
BA_ "GenSigSNA" SG_ 2566858487 BATT_capBrick11_1 65535;
BA_ "GenSigSNA" SG_ 2566858487 BATT_capBrick09_1 65535;
BA_ "GenSigSNA" SG_ 2566858487 BATT_capBrick10_1 65535;
BA_ "GenSigSNA" SG_ 2566858488 BATT_capBrick12_2 65535;
BA_ "GenSigSNA" SG_ 2566858488 BATT_capBrick11_2 65535;
BA_ "GenSigSNA" SG_ 2566858488 BATT_capBrick09_2 65535;
BA_ "GenSigSNA" SG_ 2566858488 BATT_capBrick10_2 65535;
BA_ "GenSigSNA" SG_ 2566858489 BATT_capBrick12_3 65535;
BA_ "GenSigSNA" SG_ 2566858489 BATT_capBrick11_3 65535;
BA_ "GenSigSNA" SG_ 2566858489 BATT_capBrick09_3 65535;
BA_ "GenSigSNA" SG_ 2566858489 BATT_capBrick10_3 65535;
BA_ "GenSigSNA" SG_ 2566858490 BATT_capBrick12_4 65535;
BA_ "GenSigSNA" SG_ 2566858490 BATT_capBrick11_4 65535;
BA_ "GenSigSNA" SG_ 2566858490 BATT_capBrick09_4 65535;
BA_ "GenSigSNA" SG_ 2566858490 BATT_capBrick10_4 65535;
BA_ "GenSigSNA" SG_ 2566858491 BATT_capBrick12_5 65535;
BA_ "GenSigSNA" SG_ 2566858491 BATT_capBrick11_5 65535;
BA_ "GenSigSNA" SG_ 2566858491 BATT_capBrick09_5 65535;
BA_ "GenSigSNA" SG_ 2566858491 BATT_capBrick10_5 65535;
BA_ "GenSigSNA" SG_ 2566858492 BATT_capBrick12_6 65535;
BA_ "GenSigSNA" SG_ 2566858492 BATT_capBrick11_6 65535;
BA_ "GenSigSNA" SG_ 2566858492 BATT_capBrick09_6 65535;
BA_ "GenSigSNA" SG_ 2566858492 BATT_capBrick10_6 65535;
BA_ "GenSigSNA" SG_ 2566858493 BATT_capBrick12_7 65535;
BA_ "GenSigSNA" SG_ 2566858493 BATT_capBrick11_7 65535;
BA_ "GenSigSNA" SG_ 2566858493 BATT_capBrick09_7 65535;
BA_ "GenSigSNA" SG_ 2566858493 BATT_capBrick10_7 65535;
BA_ "GenSigSNA" SG_ 2566858494 BATT_capBrick12_8 65535;
BA_ "GenSigSNA" SG_ 2566858494 BATT_capBrick11_8 65535;
BA_ "GenSigSNA" SG_ 2566858494 BATT_capBrick09_8 65535;
BA_ "GenSigSNA" SG_ 2566858494 BATT_capBrick10_8 65535;
BA_ "GenSigSNA" SG_ 2566858495 BATT_capBrick12_9 65535;
BA_ "GenSigSNA" SG_ 2566858495 BATT_capBrick11_9 65535;
BA_ "GenSigSNA" SG_ 2566858495 BATT_capBrick09_9 65535;
BA_ "GenSigSNA" SG_ 2566858495 BATT_capBrick10_9 65535;
BA_ "GenSigSNA" SG_ 2566858742 BATT_vBrick12_0 65535;
BA_ "GenSigSNA" SG_ 2566858742 BATT_vBrick11_0 65535;
BA_ "GenSigSNA" SG_ 2566858742 BATT_vBrick10_0 65535;
BA_ "GenSigSNA" SG_ 2566858742 BATT_vBrick09_0 65535;
BA_ "GenSigSNA" SG_ 2566858743 BATT_vBrick12_1 65535;
BA_ "GenSigSNA" SG_ 2566858743 BATT_vBrick11_1 65535;
BA_ "GenSigSNA" SG_ 2566858743 BATT_vBrick10_1 65535;
BA_ "GenSigSNA" SG_ 2566858743 BATT_vBrick09_1 65535;
BA_ "GenSigSNA" SG_ 2566858744 BATT_vBrick12_2 65535;
BA_ "GenSigSNA" SG_ 2566858744 BATT_vBrick11_2 65535;
BA_ "GenSigSNA" SG_ 2566858744 BATT_vBrick10_2 65535;
BA_ "GenSigSNA" SG_ 2566858744 BATT_vBrick09_2 65535;
BA_ "GenSigSNA" SG_ 2566858745 BATT_vBrick12_3 65535;
BA_ "GenSigSNA" SG_ 2566858745 BATT_vBrick11_3 65535;
BA_ "GenSigSNA" SG_ 2566858745 BATT_vBrick10_3 65535;
BA_ "GenSigSNA" SG_ 2566858745 BATT_vBrick09_3 65535;
BA_ "GenSigSNA" SG_ 2566858746 BATT_vBrick12_4 65535;
BA_ "GenSigSNA" SG_ 2566858746 BATT_vBrick11_4 65535;
BA_ "GenSigSNA" SG_ 2566858746 BATT_vBrick10_4 65535;
BA_ "GenSigSNA" SG_ 2566858746 BATT_vBrick09_4 65535;
BA_ "GenSigSNA" SG_ 2566858747 BATT_vBrick12_5 65535;
BA_ "GenSigSNA" SG_ 2566858747 BATT_vBrick11_5 65535;
BA_ "GenSigSNA" SG_ 2566858747 BATT_vBrick10_5 65535;
BA_ "GenSigSNA" SG_ 2566858747 BATT_vBrick09_5 65535;
BA_ "GenSigSNA" SG_ 2566858748 BATT_vBrick12_6 65535;
BA_ "GenSigSNA" SG_ 2566858748 BATT_vBrick11_6 65535;
BA_ "GenSigSNA" SG_ 2566858748 BATT_vBrick10_6 65535;
BA_ "GenSigSNA" SG_ 2566858748 BATT_vBrick09_6 65535;
BA_ "GenSigSNA" SG_ 2566858749 BATT_vBrick12_7 65535;
BA_ "GenSigSNA" SG_ 2566858749 BATT_vBrick11_7 65535;
BA_ "GenSigSNA" SG_ 2566858749 BATT_vBrick10_7 65535;
BA_ "GenSigSNA" SG_ 2566858749 BATT_vBrick09_7 65535;
BA_ "GenSigSNA" SG_ 2566858750 BATT_vBrick12_8 65535;
BA_ "GenSigSNA" SG_ 2566858750 BATT_vBrick11_8 65535;
BA_ "GenSigSNA" SG_ 2566858750 BATT_vBrick10_8 65535;
BA_ "GenSigSNA" SG_ 2566858750 BATT_vBrick09_8 65535;
BA_ "GenSigSNA" SG_ 2566858751 BATT_vBrick12_9 65535;
BA_ "GenSigSNA" SG_ 2566858751 BATT_vBrick11_9 65535;
BA_ "GenSigSNA" SG_ 2566858751 BATT_vBrick10_9 65535;
BA_ "GenSigSNA" SG_ 2566858751 BATT_vBrick09_9 65535;
BA_ "GenSigSNA" SG_ 2566862582 BATT_capBrick14_0 65535;
BA_ "GenSigSNA" SG_ 2566862582 BATT_capBrick13_0 65535;
BA_ "GenSigSNA" SG_ 2566862583 BATT_capBrick14_1 65535;
BA_ "GenSigSNA" SG_ 2566862583 BATT_capBrick13_1 65535;
BA_ "GenSigSNA" SG_ 2566862584 BATT_capBrick14_2 65535;
BA_ "GenSigSNA" SG_ 2566862584 BATT_capBrick13_2 65535;
BA_ "GenSigSNA" SG_ 2566862585 BATT_capBrick14_3 65535;
BA_ "GenSigSNA" SG_ 2566862585 BATT_capBrick13_3 65535;
BA_ "GenSigSNA" SG_ 2566862586 BATT_capBrick14_4 65535;
BA_ "GenSigSNA" SG_ 2566862586 BATT_capBrick13_4 65535;
BA_ "GenSigSNA" SG_ 2566862587 BATT_capBrick14_5 65535;
BA_ "GenSigSNA" SG_ 2566862587 BATT_capBrick13_5 65535;
BA_ "GenSigSNA" SG_ 2566862588 BATT_capBrick14_6 65535;
BA_ "GenSigSNA" SG_ 2566862588 BATT_capBrick13_6 65535;
BA_ "GenSigSNA" SG_ 2566862589 BATT_capBrick14_7 65535;
BA_ "GenSigSNA" SG_ 2566862589 BATT_capBrick13_7 65535;
BA_ "GenSigSNA" SG_ 2566862590 BATT_capBrick14_8 65535;
BA_ "GenSigSNA" SG_ 2566862590 BATT_capBrick13_8 65535;
BA_ "GenSigSNA" SG_ 2566862591 BATT_capBrick13_9 65535;
BA_ "GenSigSNA" SG_ 2566862591 BATT_capBrick14_9 65535;
BA_ "GenSigSNA" SG_ 2566862838 BATT_vBrick14_0 65535;
BA_ "GenSigSNA" SG_ 2566862838 BATT_vBrick13_0 65535;
BA_ "GenSigSNA" SG_ 2566862839 BATT_vBrick13_1 65535;
BA_ "GenSigSNA" SG_ 2566862839 BATT_vBrick14_1 65535;
BA_ "GenSigSNA" SG_ 2566862840 BATT_vBrick14_2 65535;
BA_ "GenSigSNA" SG_ 2566862840 BATT_vBrick13_2 65535;
BA_ "Access" SG_ 2566853877 BATT_nodeIdSerialNumber 1;
VAL_ 2566853877 BATT_stateRequest  3 "Sleep"  2 "Charge"  1 "Drive"  0 "None"  ;
VAL_ 2566854390 BATT_capBrick08_0  65535 "SNA"  ;
VAL_ 2566854390 BATT_capBrick07_0  65535 "SNA"  ;
VAL_ 2566854390 BATT_capBrick06_0  65535 "SNA"  ;
VAL_ 2566854390 BATT_capBrick05_0  65535 "SNA"  ;
VAL_ 2566854391 BATT_capBrick08_1  65535 "SNA"  ;
VAL_ 2566854391 BATT_capBrick07_1  65535 "SNA"  ;
VAL_ 2566854391 BATT_capBrick06_1  65535 "SNA"  ;
VAL_ 2566854391 BATT_capBrick05_1  65535 "SNA"  ;
VAL_ 2566854392 BATT_capBrick08_2  65535 "SNA"  ;
VAL_ 2566854392 BATT_capBrick07_2  65535 "SNA"  ;
VAL_ 2566854392 BATT_capBrick06_2  65535 "SNA"  ;
VAL_ 2566854392 BATT_capBrick05_2  65535 "SNA"  ;
VAL_ 2566854393 BATT_capBrick08_3  65535 "SNA"  ;
VAL_ 2566854393 BATT_capBrick07_3  65535 "SNA"  ;
VAL_ 2566854393 BATT_capBrick06_3  65535 "SNA"  ;
VAL_ 2566854393 BATT_capBrick05_3  65535 "SNA"  ;
VAL_ 2566854394 BATT_capBrick08_4  65535 "SNA"  ;
VAL_ 2566854394 BATT_capBrick07_4  65535 "SNA"  ;
VAL_ 2566854394 BATT_capBrick06_4  65535 "SNA"  ;
VAL_ 2566854394 BATT_capBrick05_4  65535 "SNA"  ;
VAL_ 2566854395 BATT_capBrick08_5  65535 "SNA"  ;
VAL_ 2566854395 BATT_capBrick07_5  65535 "SNA"  ;
VAL_ 2566854395 BATT_capBrick06_5  65535 "SNA"  ;
VAL_ 2566854395 BATT_capBrick05_5  65535 "SNA"  ;
VAL_ 2566854396 BATT_capBrick08_6  65535 "SNA"  ;
VAL_ 2566854396 BATT_capBrick07_6  65535 "SNA"  ;
VAL_ 2566854396 BATT_capBrick06_6  65535 "SNA"  ;
VAL_ 2566854396 BATT_capBrick05_6  65535 "SNA"  ;
VAL_ 2566854397 BATT_capBrick08_7  65535 "SNA"  ;
VAL_ 2566854397 BATT_capBrick07_7  65535 "SNA"  ;
VAL_ 2566854397 BATT_capBrick06_7  65535 "SNA"  ;
VAL_ 2566854397 BATT_capBrick05_7  65535 "SNA"  ;
VAL_ 2566854398 BATT_capBrick08_8  65535 "SNA"  ;
VAL_ 2566854398 BATT_capBrick07_8  65535 "SNA"  ;
VAL_ 2566854398 BATT_capBrick06_8  65535 "SNA"  ;
VAL_ 2566854398 BATT_capBrick05_8  65535 "SNA"  ;
VAL_ 2566854399 BATT_capBrick08_9  65535 "SNA"  ;
VAL_ 2566854399 BATT_capBrick07_9  65535 "SNA"  ;
VAL_ 2566854399 BATT_capBrick06_9  65535 "SNA"  ;
VAL_ 2566854399 BATT_capBrick05_9  65535 "SNA"  ;
VAL_ 2566854646 BATT_vBrick06_0  65535 "SNA"  ;
VAL_ 2566854646 BATT_vBrick07_0  65535 "SNA"  ;
VAL_ 2566854646 BATT_vBrick05_0  65535 "SNA"  ;
VAL_ 2566854646 BATT_vBrick08_0  65535 "SNA"  ;
VAL_ 2566854647 BATT_vBrick06_1  65535 "SNA"  ;
VAL_ 2566854647 BATT_vBrick07_1  65535 "SNA"  ;
VAL_ 2566854647 BATT_vBrick05_1  65535 "SNA"  ;
VAL_ 2566854647 BATT_vBrick08_1  65535 "SNA"  ;
VAL_ 2566854648 BATT_vBrick06_2  65535 "SNA"  ;
VAL_ 2566854648 BATT_vBrick07_2  65535 "SNA"  ;
VAL_ 2566854648 BATT_vBrick05_2  65535 "SNA"  ;
VAL_ 2566854648 BATT_vBrick08_2  65535 "SNA"  ;
VAL_ 2566854649 BATT_vBrick06_3  65535 "SNA"  ;
VAL_ 2566854649 BATT_vBrick07_3  65535 "SNA"  ;
VAL_ 2566854649 BATT_vBrick05_3  65535 "SNA"  ;
VAL_ 2566854649 BATT_vBrick08_3  65535 "SNA"  ;
VAL_ 2566854650 BATT_vBrick06_4  65535 "SNA"  ;
VAL_ 2566854650 BATT_vBrick07_4  65535 "SNA"  ;
VAL_ 2566854650 BATT_vBrick05_4  65535 "SNA"  ;
VAL_ 2566854650 BATT_vBrick08_4  65535 "SNA"  ;
VAL_ 2566854651 BATT_vBrick06_5  65535 "SNA"  ;
VAL_ 2566854651 BATT_vBrick07_5  65535 "SNA"  ;
VAL_ 2566854651 BATT_vBrick05_5  65535 "SNA"  ;
VAL_ 2566854651 BATT_vBrick08_5  65535 "SNA"  ;
VAL_ 2566854652 BATT_vBrick06_6  65535 "SNA"  ;
VAL_ 2566854652 BATT_vBrick07_6  65535 "SNA"  ;
VAL_ 2566854652 BATT_vBrick05_6  65535 "SNA"  ;
VAL_ 2566854652 BATT_vBrick08_6  65535 "SNA"  ;
VAL_ 2566854653 BATT_vBrick06_7  65535 "SNA"  ;
VAL_ 2566854653 BATT_vBrick07_7  65535 "SNA"  ;
VAL_ 2566854653 BATT_vBrick05_7  65535 "SNA"  ;
VAL_ 2566854653 BATT_vBrick08_7  65535 "SNA"  ;
VAL_ 2566854654 BATT_vBrick06_8  65535 "SNA"  ;
VAL_ 2566854654 BATT_vBrick07_8  65535 "SNA"  ;
VAL_ 2566854654 BATT_vBrick05_8  65535 "SNA"  ;
VAL_ 2566854654 BATT_vBrick08_8  65535 "SNA"  ;
VAL_ 2566854655 BATT_vBrick06_9  65535 "SNA"  ;
VAL_ 2566854655 BATT_vBrick07_9  65535 "SNA"  ;
VAL_ 2566854655 BATT_vBrick05_9  65535 "SNA"  ;
VAL_ 2566854655 BATT_vBrick08_9  65535 "SNA"  ;
VAL_ 2566855158 BATT_tPreChg  65535 "SNA"  ;
VAL_ 2566855158 BATT_tFET  65535 "SNA"  ;
VAL_ 2566855158 BATT_tShunt  65535 "SNA"  ;
VAL_ 2566858486 BATT_capBrick12_0  65535 "SNA"  ;
VAL_ 2566858486 BATT_capBrick11_0  65535 "SNA"  ;
VAL_ 2566858486 BATT_capBrick09_0  65535 "SNA"  ;
VAL_ 2566858486 BATT_capBrick10_0  65535 "SNA"  ;
VAL_ 2566858487 BATT_capBrick12_1  65535 "SNA"  ;
VAL_ 2566858487 BATT_capBrick11_1  65535 "SNA"  ;
VAL_ 2566858487 BATT_capBrick09_1  65535 "SNA"  ;
VAL_ 2566858487 BATT_capBrick10_1  65535 "SNA"  ;
VAL_ 2566858488 BATT_capBrick12_2  65535 "SNA"  ;
VAL_ 2566858488 BATT_capBrick11_2  65535 "SNA"  ;
VAL_ 2566858488 BATT_capBrick09_2  65535 "SNA"  ;
VAL_ 2566858488 BATT_capBrick10_2  65535 "SNA"  ;
VAL_ 2566858489 BATT_capBrick12_3  65535 "SNA"  ;
VAL_ 2566858489 BATT_capBrick11_3  65535 "SNA"  ;
VAL_ 2566858489 BATT_capBrick09_3  65535 "SNA"  ;
VAL_ 2566858489 BATT_capBrick10_3  65535 "SNA"  ;
VAL_ 2566858490 BATT_capBrick12_4  65535 "SNA"  ;
VAL_ 2566858490 BATT_capBrick11_4  65535 "SNA"  ;
VAL_ 2566858490 BATT_capBrick09_4  65535 "SNA"  ;
VAL_ 2566858490 BATT_capBrick10_4  65535 "SNA"  ;
VAL_ 2566858491 BATT_capBrick12_5  65535 "SNA"  ;
VAL_ 2566858491 BATT_capBrick11_5  65535 "SNA"  ;
VAL_ 2566858491 BATT_capBrick09_5  65535 "SNA"  ;
VAL_ 2566858491 BATT_capBrick10_5  65535 "SNA"  ;
VAL_ 2566858492 BATT_capBrick12_6  65535 "SNA"  ;
VAL_ 2566858492 BATT_capBrick11_6  65535 "SNA"  ;
VAL_ 2566858492 BATT_capBrick09_6  65535 "SNA"  ;
VAL_ 2566858492 BATT_capBrick10_6  65535 "SNA"  ;
VAL_ 2566858493 BATT_capBrick12_7  65535 "SNA"  ;
VAL_ 2566858493 BATT_capBrick11_7  65535 "SNA"  ;
VAL_ 2566858493 BATT_capBrick09_7  65535 "SNA"  ;
VAL_ 2566858493 BATT_capBrick10_7  65535 "SNA"  ;
VAL_ 2566858494 BATT_capBrick12_8  65535 "SNA"  ;
VAL_ 2566858494 BATT_capBrick11_8  65535 "SNA"  ;
VAL_ 2566858494 BATT_capBrick09_8  65535 "SNA"  ;
VAL_ 2566858494 BATT_capBrick10_8  65535 "SNA"  ;
VAL_ 2566858495 BATT_capBrick12_9  65535 "SNA"  ;
VAL_ 2566858495 BATT_capBrick11_9  65535 "SNA"  ;
VAL_ 2566858495 BATT_capBrick09_9  65535 "SNA"  ;
VAL_ 2566858495 BATT_capBrick10_9  65535 "SNA"  ;
VAL_ 2566858742 BATT_vBrick12_0  65535 "SNA"  ;
VAL_ 2566858742 BATT_vBrick11_0  65535 "SNA"  ;
VAL_ 2566858742 BATT_vBrick10_0  65535 "SNA"  ;
VAL_ 2566858742 BATT_vBrick09_0  65535 "SNA"  ;
VAL_ 2566858743 BATT_vBrick12_1  65535 "SNA"  ;
VAL_ 2566858743 BATT_vBrick11_1  65535 "SNA"  ;
VAL_ 2566858743 BATT_vBrick10_1  65535 "SNA"  ;
VAL_ 2566858743 BATT_vBrick09_1  65535 "SNA"  ;
VAL_ 2566858744 BATT_vBrick12_2  65535 "SNA"  ;
VAL_ 2566858744 BATT_vBrick11_2  65535 "SNA"  ;
VAL_ 2566858744 BATT_vBrick10_2  65535 "SNA"  ;
VAL_ 2566858744 BATT_vBrick09_2  65535 "SNA"  ;
VAL_ 2566858745 BATT_vBrick12_3  65535 "SNA"  ;
VAL_ 2566858745 BATT_vBrick11_3  65535 "SNA"  ;
VAL_ 2566858745 BATT_vBrick10_3  65535 "SNA"  ;
VAL_ 2566858745 BATT_vBrick09_3  65535 "SNA"  ;
VAL_ 2566858746 BATT_vBrick12_4  65535 "SNA"  ;
VAL_ 2566858746 BATT_vBrick11_4  65535 "SNA"  ;
VAL_ 2566858746 BATT_vBrick10_4  65535 "SNA"  ;
VAL_ 2566858746 BATT_vBrick09_4  65535 "SNA"  ;
VAL_ 2566858747 BATT_vBrick12_5  65535 "SNA"  ;
VAL_ 2566858747 BATT_vBrick11_5  65535 "SNA"  ;
VAL_ 2566858747 BATT_vBrick10_5  65535 "SNA"  ;
VAL_ 2566858747 BATT_vBrick09_5  65535 "SNA"  ;
VAL_ 2566858748 BATT_vBrick12_6  65535 "SNA"  ;
VAL_ 2566858748 BATT_vBrick11_6  65535 "SNA"  ;
VAL_ 2566858748 BATT_vBrick10_6  65535 "SNA"  ;
VAL_ 2566858748 BATT_vBrick09_6  65535 "SNA"  ;
VAL_ 2566858749 BATT_vBrick12_7  65535 "SNA"  ;
VAL_ 2566858749 BATT_vBrick11_7  65535 "SNA"  ;
VAL_ 2566858749 BATT_vBrick10_7  65535 "SNA"  ;
VAL_ 2566858749 BATT_vBrick09_7  65535 "SNA"  ;
VAL_ 2566858750 BATT_vBrick12_8  65535 "SNA"  ;
VAL_ 2566858750 BATT_vBrick11_8  65535 "SNA"  ;
VAL_ 2566858750 BATT_vBrick10_8  65535 "SNA"  ;
VAL_ 2566858750 BATT_vBrick09_8  65535 "SNA"  ;
VAL_ 2566858751 BATT_vBrick12_9  65535 "SNA"  ;
VAL_ 2566858751 BATT_vBrick11_9  65535 "SNA"  ;
VAL_ 2566858751 BATT_vBrick10_9  65535 "SNA"  ;
VAL_ 2566858751 BATT_vBrick09_9  65535 "SNA"  ;
VAL_ 2566862582 BATT_capBrick14_0  65535 "SNA"  ;
VAL_ 2566862582 BATT_capBrick13_0  65535 "SNA"  ;
VAL_ 2566862583 BATT_capBrick14_1  65535 "SNA"  ;
VAL_ 2566862583 BATT_capBrick13_1  65535 "SNA"  ;
VAL_ 2566862584 BATT_capBrick14_2  65535 "SNA"  ;
VAL_ 2566862584 BATT_capBrick13_2  65535 "SNA"  ;
VAL_ 2566862585 BATT_capBrick14_3  65535 "SNA"  ;
VAL_ 2566862585 BATT_capBrick13_3  65535 "SNA"  ;
VAL_ 2566862586 BATT_capBrick14_4  65535 "SNA"  ;
VAL_ 2566862586 BATT_capBrick13_4  65535 "SNA"  ;
VAL_ 2566862587 BATT_capBrick14_5  65535 "SNA"  ;
VAL_ 2566862587 BATT_capBrick13_5  65535 "SNA"  ;
VAL_ 2566862588 BATT_capBrick14_6  65535 "SNA"  ;
VAL_ 2566862588 BATT_capBrick13_6  65535 "SNA"  ;
VAL_ 2566862589 BATT_capBrick14_7  65535 "SNA"  ;
VAL_ 2566862589 BATT_capBrick13_7  65535 "SNA"  ;
VAL_ 2566862590 BATT_capBrick14_8  65535 "SNA"  ;
VAL_ 2566862590 BATT_capBrick13_8  65535 "SNA"  ;
VAL_ 2566862591 BATT_capBrick13_9  65535 "SNA"  ;
VAL_ 2566862591 BATT_capBrick14_9  65535 "SNA"  ;
VAL_ 2566862838 BATT_vBrick14_0  65535 "SNA"  ;
VAL_ 2566862838 BATT_vBrick13_0  65535 "SNA"  ;
VAL_ 2566862839 BATT_vBrick13_1  65535 "SNA"  ;
VAL_ 2566862839 BATT_vBrick14_1  65535 "SNA"  ;
VAL_ 2566862840 BATT_vBrick14_2  65535 "SNA"  ;
VAL_ 2566862840 BATT_vBrick13_2  65535 "SNA"  ;
